VERSION "dbc-export 1 2025.20.8"

NS_ :

BS_:

BU_: ADSP APB APP APS BB BMS CC CP DAS DI DIF DIR EPAS3P EPAS3S EPBL EPBR GTW HVP ICR IDB PCS PM TCU UI UIS VC VCFRONT VCLEFT VCRIGHT VCSEC

BO_ 1383 ADSP_state: 7 ADSP
 SG_ ADSP_a2baState : 0|5@1+ (1,0) [0|31] "" Vector__XXX
 SG_ ADSP_a2bbState : 8|5@1+ (1,0) [0|31] "" Vector__XXX
 SG_ ADSP_baseamp0State : 13|3@1+ (1,0) [0|7] "" Vector__XXX
 SG_ ADSP_baseamp1State : 16|3@1+ (1,0) [0|7] "" Vector__XXX
 SG_ ADSP_baseamp2State : 19|3@1+ (1,0) [0|7] "" Vector__XXX
 SG_ ADSP_baseamp3State : 24|3@1+ (1,0) [0|7] "" Vector__XXX
 SG_ ADSP_audioReady : 27|1@1+ (1,0) [0|1] "" Vector__XXX
 SG_ ADSP_tcuI2SEnabled : 28|1@1+ (1,0) [0|1] "" Vector__XXX
 SG_ ADSP_ancState : 29|2@1+ (1,0) [0|3] "" Vector__XXX
 SG_ ADSP_telephonyRxMute : 31|1@1+ (1,0) [0|1] "" Vector__XXX
 SG_ ADSP_sourceSelect : 32|2@1+ (1,0) [0|3] "" Vector__XXX
 SG_ ADSP_tunerSelect : 34|1@1+ (1,0) [0|1] "" Vector__XXX
 SG_ ADSP_ancMode : 35|5@1+ (1,0) [0|31] "" Vector__XXX
 SG_ ADSP_spkMuteAll : 40|1@1+ (1,0) [0|1] "" Vector__XXX
 SG_ ADSP_allAudioReady : 41|1@1+ (1,0) [0|1] "" Vector__XXX
 SG_ ADSP_callState : 42|1@1+ (1,0) [0|1] "" Vector__XXX
 SG_ ADSP_telephonyTxMute : 43|1@1+ (1,0) [0|1] "" Vector__XXX
 SG_ ADSP_eCall_ENS_state : 44|3@1+ (1,0) [0|7] "" Vector__XXX
 SG_ ADSP_eCallSelfTest : 47|2@1+ (1,0) [0|3] "" Vector__XXX
 SG_ ADSP_eCallState : 49|1@1+ (1,0) [0|1] "" Vector__XXX
 SG_ ADSP_eCallMicrophoneStatus : 50|2@1+ (1,0) [0|3] "" Vector__XXX
 SG_ ADSP_eCallSpeakerStatus : 52|2@1+ (1,0) [0|3] "" Vector__XXX
 SG_ ADSP_a2baLoadShedded : 54|1@1+ (1,0) [0|1] "" Vector__XXX
 SG_ ADSP_requestFailoverSpeaker : 55|1@1+ (1,0) [0|1] "" Vector__XXX

BO_ 600 APB_status: 8 APB
 SG_ APB_watchdogState : 0|3@1+ (1,0) [0|6] "" Vector__XXX
 SG_ APB_fusedState : 3|2@1+ (1,0) [0|2] "" Vector__XXX
 SG_ APB_cameraHeaterRequest : 5|1@1+ (1,0) [0|1] "" Vector__XXX
 SG_ APB_factorySummonStatus : 6|4@1+ (1,0) [1|15] "" Vector__XXX
 SG_ APB_clipRecordingStatus : 10|3@1+ (1,0) [0|7] "" Vector__XXX
 SG_ APB_summonUnavailableReason : 14|5@1+ (1,0) [0|31] "" Vector__XXX
 SG_ APB_fsdSuspendState : 19|2@1+ (1,0) [0|2] "" Vector__XXX
 SG_ APB_fsdRevokeStrikeoutCount : 21|3@1+ (1,0) [0|6] "" Vector__XXX
 SG_ APB_teslaVisionSupported : 24|2@1+ (1,0) [0|2] "" Vector__XXX
 SG_ APB_teslaVisionUnsupportedReason : 26|3@1+ (1,0) [0|7] "" Vector__XXX
 SG_ APB_fsdRevokeCount : 29|3@1+ (1,0) [0|6] "" Vector__XXX
 SG_ APB_excessiveAccelPedalWarning : 32|1@1+ (1,0) [0|1] "" Vector__XXX
 SG_ APB_unifiedObjectStackSupported : 33|2@1+ (1,0) [0|2] "" Vector__XXX
 SG_ APB_DDAWSystemStatus : 38|3@1+ (1,0) [0|7] "" Vector__XXX
 SG_ APB_socOperatingMode : 41|2@1+ (1,0) [0|3] "" Vector__XXX
 SG_ APB_summonVersionIdentifier : 43|1@1+ (1,0) [0|1] "" Vector__XXX
 SG_ APB_sentryState : 44|3@1+ (1,0) [0|7] "" Vector__XXX
 SG_ APB_autoparkVersionIdentifier : 47|2@1+ (1,0) [0|3] "" Vector__XXX
 SG_ APB_suspendResumeAvailable : 51|1@1+ (1,0) [0|1] "" Vector__XXX
 SG_ APB_statusCounter : 52|4@1+ (1,0) [0|15] "" Vector__XXX
 SG_ APB_statusChecksum : 56|8@1+ (1,0) [0|255] "" Vector__XXX

BO_ 909 APP_VC_infoMessage: 8 APP
 SG_ APP_inTunnel : 0|2@1+ (1,0) [1|3] "" Vector__XXX
 SG_ APP_windshieldHeaterOnReason : 2|3@1+ (1,0) [1|7] "" Vector__XXX
 SG_ APP_selfieCameraBlocked : 6|2@1+ (1,0) [1|3] "" Vector__XXX
 SG_ APP_selfieCameraLUX : 8|8@1+ (1,0) [0|253] "lux" Vector__XXX
 SG_ APP_sceneTagClearlyRaining : 16|2@1+ (1,0) [1|3] "" Vector__XXX
 SG_ APP_sceneTagFog : 18|2@1+ (1,0) [1|3] "" Vector__XXX
 SG_ APP_sceneTagFullyBlocked : 20|2@1+ (1,0) [1|3] "" Vector__XXX
 SG_ APP_sceneTagIndoors : 22|2@1+ (1,0) [1|3] "" Vector__XXX
 SG_ APP_sceneTagLensFlare : 24|2@1+ (1,0) [1|3] "" Vector__XXX
 SG_ APP_sceneTagRaining : 26|2@1+ (1,0) [1|3] "" Vector__XXX
 SG_ APP_sceneTagSevereWeather : 28|2@1+ (1,0) [1|3] "" Vector__XXX
 SG_ APP_sceneTagSnowing : 30|2@1+ (1,0) [1|3] "" Vector__XXX
 SG_ APP_sceneTagSnowyRoad : 32|2@1+ (1,0) [1|3] "" Vector__XXX
 SG_ APP_sceneTagSunGlare : 34|2@1+ (1,0) [1|3] "" Vector__XXX
 SG_ APP_sceneTagTunnel : 36|2@1+ (1,0) [1|3] "" Vector__XXX
 SG_ APP_sceneTagWetRoad : 38|2@1+ (1,0) [1|3] "" Vector__XXX
 SG_ APP_fisheyeInPathVisibility : 40|3@1+ (1,0) [1|7] "" Vector__XXX
 SG_ APP_fisheyeOverallVisibility : 43|3@1+ (1,0) [1|7] "" Vector__XXX
 SG_ APP_mainInPathVisibility : 46|3@1+ (1,0) [1|7] "" Vector__XXX
 SG_ APP_mainOverallVisibility : 49|3@1+ (1,0) [1|7] "" Vector__XXX
 SG_ APP_narrowInPathVisibility : 52|3@1+ (1,0) [1|7] "" Vector__XXX
 SG_ APP_narrowOverallVisibility : 55|3@1+ (1,0) [1|7] "" Vector__XXX
 SG_ APP_frontCamOcclusionType : 58|3@1+ (1,0) [0|7] "" Vector__XXX

BO_ 2046 APP_camCalibrationStatus: 6 APP
 SG_ APP_cameraPosition M : 0|4@1+ (1,0) [0|15] "" Vector__XXX
 SG_ APP_mainCamExtPitchCal m1 : 8|9@1+ (0.05,-12.5) [-12.5|12.5] "deg" Vector__XXX
 SG_ APP_mainCamExtYawCal m1 : 17|9@1+ (0.05,-12.5) [-12.5|12.5] "deg" Vector__XXX
 SG_ APP_mainCalibTime m1 : 26|7@1+ (1,0) [0|126] "min" Vector__XXX
 SG_ APP_mainCalibProgress m1 : 33|7@1+ (1,0) [0|100] "percent" Vector__XXX
 SG_ APP_mainCalibrated m1 : 40|1@1+ (1,0) [0|1] "" Vector__XXX
 SG_ APP_narrowCamExtPitchCal m2 : 8|9@1+ (0.05,-12.5) [-12.5|12.5] "deg" Vector__XXX
 SG_ APP_narrowCamExtYawCal m2 : 17|9@1+ (0.05,-12.5) [-12.5|12.5] "deg" Vector__XXX
 SG_ APP_narrowCalibTime m2 : 26|7@1+ (1,0) [0|126] "min" Vector__XXX
 SG_ APP_narrowCalibProgress m2 : 33|7@1+ (1,0) [0|100] "percent" Vector__XXX
 SG_ APP_narrowCalibrated m2 : 40|1@1+ (1,0) [0|1] "" Vector__XXX
 SG_ APP_fisheyeCamExtPitchCal m3 : 8|9@1+ (0.05,-12.5) [-12.5|12.5] "deg" Vector__XXX
 SG_ APP_fisheyeCamExtYawCal m3 : 17|9@1+ (0.05,-12.5) [-12.5|12.5] "deg" Vector__XXX
 SG_ APP_fisheyeCalibTime m3 : 26|7@1+ (1,0) [0|126] "min" Vector__XXX
 SG_ APP_fisheyeCalibProgress m3 : 33|7@1+ (1,0) [0|100] "percent" Vector__XXX
 SG_ APP_fisheyeCalibrated m3 : 40|1@1+ (1,0) [0|1] "" Vector__XXX
 SG_ APP_lPillarCamExtPitchCal m4 : 8|9@1+ (0.05,-12.5) [-12.5|12.5] "deg" Vector__XXX
 SG_ APP_lPillarCamExtYawCal m4 : 17|9@1+ (0.05,-12.5) [-12.5|12.5] "deg" Vector__XXX
 SG_ APP_lPillarCalibTime m4 : 26|7@1+ (1,0) [0|126] "min" Vector__XXX
 SG_ APP_lPillarCalibProgress m4 : 33|7@1+ (1,0) [0|100] "percent" Vector__XXX
 SG_ APP_lPillarCalibrated m4 : 40|1@1+ (1,0) [0|1] "" Vector__XXX
 SG_ APP_rPillarCamExtPitchCal m5 : 8|9@1+ (0.05,-12.5) [-12.5|12.5] "deg" Vector__XXX
 SG_ APP_rPillarCamExtYawCal m5 : 17|9@1+ (0.05,-12.5) [-12.5|12.5] "deg" Vector__XXX
 SG_ APP_rPillarCalibTime m5 : 26|7@1+ (1,0) [0|126] "min" Vector__XXX
 SG_ APP_rPillarCalibProgress m5 : 33|7@1+ (1,0) [0|100] "percent" Vector__XXX
 SG_ APP_rPillarCalibrated m5 : 40|1@1+ (1,0) [0|1] "" Vector__XXX
 SG_ APP_lRepeatCamExtPitchCal m6 : 8|9@1+ (0.05,-12.5) [-12.5|12.5] "deg" Vector__XXX
 SG_ APP_lRepeatCamExtYawCal m6 : 17|9@1+ (0.05,-12.5) [-12.5|12.5] "deg" Vector__XXX
 SG_ APP_lRepeatCalibTime m6 : 26|7@1+ (1,0) [0|126] "min" Vector__XXX
 SG_ APP_lRepeatCalibProgress m6 : 33|7@1+ (1,0) [0|100] "percent" Vector__XXX
 SG_ APP_lRepeatCalibrated m6 : 40|1@1+ (1,0) [0|1] "" Vector__XXX
 SG_ APP_rRepeatCamExtPitchCal m7 : 8|9@1+ (0.05,-12.5) [-12.5|12.5] "deg" Vector__XXX
 SG_ APP_rRepeatCamExtYawCal m7 : 17|9@1+ (0.05,-12.5) [-12.5|12.5] "deg" Vector__XXX
 SG_ APP_rRepeatCalibTime m7 : 26|7@1+ (1,0) [0|126] "min" Vector__XXX
 SG_ APP_rRepeatCalibProgress m7 : 33|7@1+ (1,0) [0|100] "percent" Vector__XXX
 SG_ APP_rRepeatCalibrated m7 : 40|1@1+ (1,0) [0|1] "" Vector__XXX
 SG_ APP_backupCamExtPitchCal m8 : 8|9@1+ (0.05,-12.5) [-12.5|12.5] "deg" Vector__XXX
 SG_ APP_backupCamExtYawCal m8 : 17|9@1+ (0.05,-12.5) [-12.5|12.5] "deg" Vector__XXX
 SG_ APP_backupCalibTime m8 : 26|7@1+ (1,0) [0|126] "min" Vector__XXX
 SG_ APP_backupCalibProgress m8 : 33|7@1+ (1,0) [0|100] "percent" Vector__XXX
 SG_ APP_backupCalibrated m8 : 40|1@1+ (1,0) [0|1] "" Vector__XXX

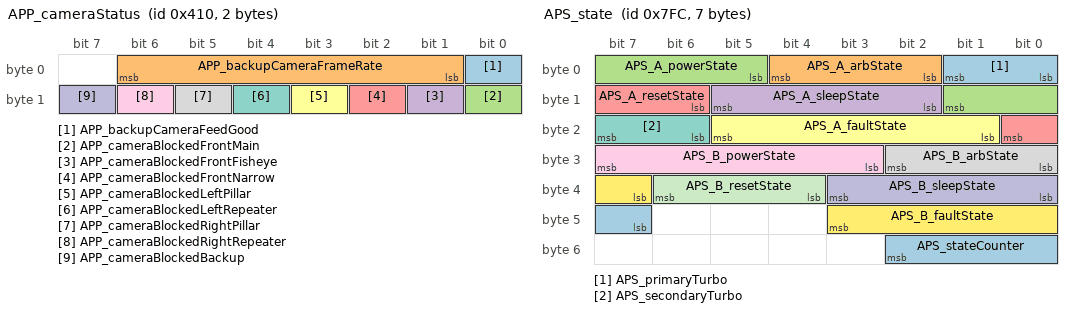
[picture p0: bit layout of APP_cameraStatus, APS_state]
BO_ 1040 APP_cameraStatus: 2 APP
 SG_ APP_backupCameraFeedGood : 0|1@1+ (1,0) [0|1] "" Vector__XXX
 SG_ APP_backupCameraFrameRate : 1|6@1+ (1,0) [0|63] "" Vector__XXX
 SG_ APP_cameraBlockedFrontMain : 8|1@1+ (1,0) [0|1] "" Vector__XXX
 SG_ APP_cameraBlockedFrontFisheye : 9|1@1+ (1,0) [0|1] "" Vector__XXX
 SG_ APP_cameraBlockedFrontNarrow : 10|1@1+ (1,0) [0|1] "" Vector__XXX
 SG_ APP_cameraBlockedLeftPillar : 11|1@1+ (1,0) [0|1] "" Vector__XXX
 SG_ APP_cameraBlockedLeftRepeater : 12|1@1+ (1,0) [0|1] "" Vector__XXX
 SG_ APP_cameraBlockedRightPillar : 13|1@1+ (1,0) [0|1] "" Vector__XXX
 SG_ APP_cameraBlockedRightRepeater : 14|1@1+ (1,0) [0|1] "" Vector__XXX
 SG_ APP_cameraBlockedBackup : 15|1@1+ (1,0) [0|1] "" Vector__XXX

BO_ 603 APP_environment: 1 APP
 SG_ APP_environmentRainy : 0|1@1+ (1,0) [0|1] "" Vector__XXX
 SG_ APP_environmentSnowy : 1|1@1+ (1,0) [0|1] "" Vector__XXX

BO_ 601 APP_status: 8 APP
 SG_ APP_watchdogState : 0|3@1+ (1,0) [0|6] "" Vector__XXX
 SG_ APP_fusedState : 3|2@1+ (1,0) [0|2] "" Vector__XXX
 SG_ APP_cameraHeaterRequest : 5|1@1+ (1,0) [0|1] "" Vector__XXX
 SG_ APP_factorySummonStatus : 6|4@1+ (1,0) [1|15] "" Vector__XXX
 SG_ APP_clipRecordingStatus : 10|3@1+ (1,0) [0|7] "" Vector__XXX
 SG_ APP_allowApActivationWithBrake : 13|1@1+ (1,0) [0|1] "" Vector__XXX
 SG_ APP_summonUnavailableReason : 14|5@1+ (1,0) [0|31] "" Vector__XXX
 SG_ APP_fsdSuspendState : 19|2@1+ (1,0) [0|2] "" Vector__XXX
 SG_ APP_fsdRevokeStrikeoutCount : 21|3@1+ (1,0) [0|6] "" Vector__XXX
 SG_ APP_teslaVisionSupported : 24|2@1+ (1,0) [0|2] "" Vector__XXX
 SG_ APP_teslaVisionUnsupportedReason : 26|3@1+ (1,0) [0|7] "" Vector__XXX
 SG_ APP_fsdRevokeCount : 29|3@1+ (1,0) [0|6] "" Vector__XXX
 SG_ APP_excessiveAccelPedalWarning : 32|1@1+ (1,0) [0|1] "" Vector__XXX
 SG_ APP_unifiedObjectStackSupported : 33|2@1+ (1,0) [0|2] "" Vector__XXX
 SG_ APP_DDAWSystemStatus : 38|3@1+ (1,0) [0|7] "" Vector__XXX
 SG_ APP_socOperatingMode : 41|2@1+ (1,0) [0|3] "" Vector__XXX
 SG_ APP_summonVersionIdentifier : 43|1@1+ (1,0) [0|1] "" Vector__XXX
 SG_ APP_sentryState : 44|3@1+ (1,0) [0|7] "" Vector__XXX
 SG_ APP_autoparkVersionIdentifier : 47|2@1+ (1,0) [0|3] "" Vector__XXX
 SG_ APP_suspendResumeAvailable : 51|1@1+ (1,0) [0|1] "" Vector__XXX
 SG_ APP_statusCounter : 52|4@1+ (1,0) [0|15] "" Vector__XXX
 SG_ APP_statusChecksum : 56|8@1+ (1,0) [0|255] "" Vector__XXX

BO_ 2044 APS_state: 7 APS
 SG_ APS_primaryTurbo : 0|2@1+ (1,0) [0|3] "" Vector__XXX
 SG_ APS_A_arbState : 2|3@1+ (1,0) [0|7] "" Vector__XXX
 SG_ APS_A_powerState : 5|5@1+ (1,0) [0|31] "" Vector__XXX
 SG_ APS_A_sleepState : 10|4@1+ (1,0) [0|15] "" Vector__XXX
 SG_ APS_A_resetState : 14|3@1+ (1,0) [0|7] "" Vector__XXX
 SG_ APS_A_faultState : 17|5@1+ (1,0) [0|31] "" Vector__XXX
 SG_ APS_secondaryTurbo : 22|2@1+ (1,0) [0|3] "" Vector__XXX
 SG_ APS_B_arbState : 24|3@1+ (1,0) [0|7] "" Vector__XXX
 SG_ APS_B_powerState : 27|5@1+ (1,0) [0|31] "" Vector__XXX
 SG_ APS_B_sleepState : 32|4@1+ (1,0) [0|15] "" Vector__XXX
 SG_ APS_B_resetState : 36|3@1+ (1,0) [0|7] "" Vector__XXX
 SG_ APS_B_faultState : 39|5@1+ (1,0) [0|31] "" Vector__XXX
 SG_ APS_stateCounter : 47|4@1+ (1,0) [0|15] "" Vector__XXX

BO_ 970 APS_status: 8 APS
 SG_ APS_appStatusMonitorState : 0|3@1+ (1,0) [0|7] "" Vector__XXX
 SG_ APS_vehBehaviorState : 4|4@1+ (1,0) [0|15] "" Vector__XXX
 SG_ APS_canMaster : 8|2@1+ (1,0) [0|2] "" Vector__XXX
 SG_ APS_appGpioState : 10|2@1+ (1,0) [0|3] "" Vector__XXX
 SG_ APS_eacInternalState : 12|3@1+ (1,0) [0|7] "" Vector__XXX
 SG_ APS_switchState : 15|1@1+ (1,0) [0|1] "" Vector__XXX
 SG_ APS_apbStatusMonitorState : 16|3@1+ (1,0) [0|7] "" Vector__XXX
 SG_ APS_apbGpioState : 20|2@1+ (1,0) [0|3] "" Vector__XXX
 SG_ APS_statusCounter : 22|4@1+ (1,0) [0|15] "" Vector__XXX
 SG_ APS_locLimitReason : 26|3@1+ (1,0) [0|7] "" Vector__XXX
 SG_ APS_appPowerStateRequest : 29|2@1+ (1,0) [0|3] "" Vector__XXX
 SG_ APS_appPowerStateReason : 31|4@1+ (1,0) [0|15] "" Vector__XXX
 SG_ APS_apbPowerStateRequest : 36|2@1+ (1,0) [0|3] "" Vector__XXX
 SG_ APS_apbPowerStateReason : 38|4@1+ (1,0) [0|15] "" Vector__XXX
 SG_ APS_heaterStateDebug : 43|3@1+ (1,0) [0|6] "" Vector__XXX
 SG_ APS_autosummonCounter : 46|3@1+ (1,0) [0|7] "" Vector__XXX
 SG_ APS_autosummonAlert : 49|1@1+ (1,0) [0|1] "" Vector__XXX
 SG_ APS_gpsAntennaState : 50|2@1+ (1,0) [0|3] "" Vector__XXX
 SG_ APS_arbState : 52|3@1+ (1,0) [0|7] "" Vector__XXX
 SG_ APS_socPowerOperatingMode : 55|2@1+ (1,0) [0|3] "" Vector__XXX
 SG_ APS_otherArbState : 57|3@1+ (1,0) [0|7] "" Vector__XXX

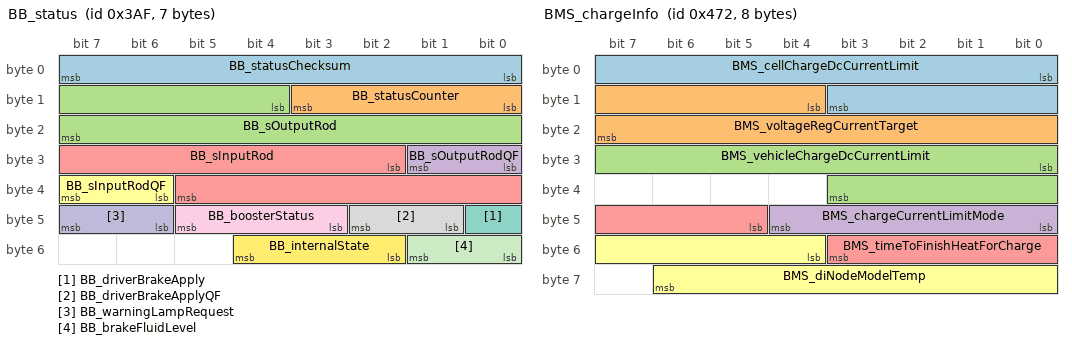
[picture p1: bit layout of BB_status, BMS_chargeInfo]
BO_ 943 BB_status: 7 BB
 SG_ BB_statusChecksum : 0|8@1+ (1,0) [0|255] "" Vector__XXX
 SG_ BB_statusCounter : 8|4@1+ (1,0) [0|15] "" Vector__XXX
 SG_ BB_sOutputRod : 12|12@1+ (0.015625,-5) [-5|47] "mm" Vector__XXX
 SG_ BB_sOutputRodQF : 24|2@1+ (1,0) [0|3] "" Vector__XXX
 SG_ BB_sInputRod : 26|12@1+ (0.015625,-5) [-5|47] "mm" Vector__XXX
 SG_ BB_sInputRodQF : 38|2@1+ (1,0) [0|3] "" Vector__XXX
 SG_ BB_driverBrakeApply : 40|1@1+ (1,0) [0|1] "" Vector__XXX
 SG_ BB_driverBrakeApplyQF : 41|2@1+ (1,0) [0|3] "" Vector__XXX
 SG_ BB_boosterStatus : 43|3@1+ (1,0) [0|7] "" Vector__XXX
 SG_ BB_warningLampRequest : 46|2@1+ (1,0) [0|3] "" Vector__XXX
 SG_ BB_brakeFluidLevel : 48|2@1+ (1,0) [0|3] "" Vector__XXX
 SG_ BB_internalState : 50|3@1+ (1,0) [0|7] "" Vector__XXX

BO_ 1138 BMS_chargeInfo: 8 BMS
 SG_ BMS_cellChargeDcCurrentLimit : 0|12@1+ (0.5,0) [0|2047.5] "A" Vector__XXX
 SG_ BMS_voltageRegCurrentTarget : 12|12@1+ (0.5,0) [0|2047.5] "A" Vector__XXX
 SG_ BMS_vehicleChargeDcCurrentLimit : 24|12@1+ (0.5,0) [0|2047.5] "A" Vector__XXX
 SG_ BMS_chargeCurrentLimitMode : 40|5@1+ (1,0) [0|31] "" Vector__XXX
 SG_ BMS_timeToFinishHeatForCharge : 45|7@1+ (5,0) [0|600] "min" Vector__XXX
 SG_ BMS_diNodeModelTemp : 52|11@1+ (0.1,-50) [-50|154.6] "degC" Vector__XXX

BO_ 2029 BMS_debugInfo_10Hz: 8 BMS
 SG_ BMS_10HzDebug_Id M : 0|6@1+ (1,0) [0|63] "" Vector__XXX
 SG_ BMS_activeCoolCellTargetT m33 : 6|9@1+ (0.25,-25) [-25|100] "DegC" Vector__XXX
 SG_ BMS_passiveCoolCellTargetT m33 : 15|9@1+ (0.25,-25) [-25|100] "DegC" Vector__XXX

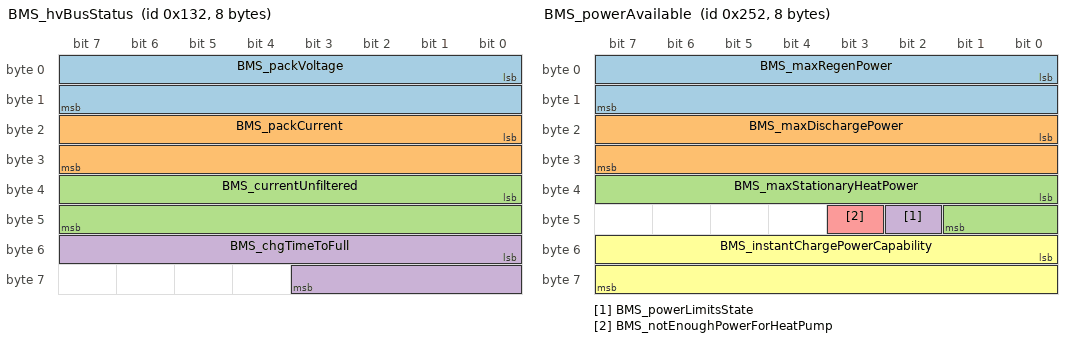
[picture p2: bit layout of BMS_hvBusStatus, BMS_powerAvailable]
BO_ 306 BMS_hvBusStatus: 8 BMS
 SG_ BMS_packVoltage : 0|16@1+ (0.01,0) [0|655.35] "V" Vector__XXX
 SG_ BMS_packCurrent : 16|16@1- (0.1,0) [-3276.7|3276.7] "A" Vector__XXX
 SG_ BMS_currentUnfiltered : 32|16@1- (0.05,-822) [-2460.3|816.3] "A" Vector__XXX
 SG_ BMS_chgTimeToFull : 48|12@1+ (0.01666667,0) [0|68.23334698] "Hours" Vector__XXX

BO_ 884 BMS_log1: 8 BMS
 SG_ BMS_log1MuxId M : 0|8@1+ (1,0) [0|255] "" Vector__XXX
 SG_ BMS_extDcPrechargeVoltageLimit m8 : 20|12@1+ (0.146502256393,0) [0|599.926739929] "V" Vector__XXX
 SG_ BMS_dcChargeCurrentRequest m8 : 32|14@1- (0.25,0) [-2048|2047.75] "A" Vector__XXX
 SG_ BMS_dcChargeCurrentLimit m8 : 46|13@1- (0.5,0) [-2048|2047.5] "A" Vector__XXX
 SG_ BMS_dcDischargeEnabled m8 : 59|1@1+ (1,0) [0|1] "" Vector__XXX
 SG_ BMS_rippleChargeRetryCount m8 : 60|3@1+ (1,0) [0|7] "" Vector__XXX
 SG_ BMS_dcChargeVoltageLimit m9 : 8|12@1+ (0.146502256393,0) [0|599.926739929] "V" Vector__XXX
 SG_ BMS_dcChargePowerLimit m9 : 20|12@1- (1,0) [-2048|2047] "kW" Vector__XXX
 SG_ BMS_maxExtIsoFcLinkV m9 : 48|13@1+ (0.134293735027,0) [0|1099.99998361] "V" Vector__XXX
 SG_ BMS_socByDeltaVEnabled m15 : 8|1@1+ (1,0) [0|1] "" Vector__XXX
 SG_ BMS_socByDvMaxSocLimit m15 : 9|10@1+ (0.1,0) [0|102.2] "%" Vector__XXX
 SG_ BMS_socByDvVoltageChangeOverAh m15 : 19|9@1+ (0.002,0) [0|1] "V" Vector__XXX
 SG_ BMS_socByDvMaxSocByAhCorrected m15 : 28|10@1+ (0.1,0) [0|102.2] "%" Vector__XXX
 SG_ BMS_socByDvMaxBrickVoltage m15 : 40|12@1+ (0.002,0) [0|5] "V" Vector__XXX
 SG_ BMS_socByDvMaxBrickId m15 : 56|8@1+ (1,1) [1|256] "" Vector__XXX

BO_ 946 BMS_log2: 8 BMS
 SG_ BMS_log2MuxId M : 0|7@1+ (1,0) [0|127] "" Vector__XXX
 SG_ BMS_cacAvg m0 : 8|13@1+ (0.1,0) [0|819.1] "Ah" Vector__XXX
 SG_ BMS_cacMin m0 : 24|13@1+ (0.1,0) [0|819.1] "Ah" Vector__XXX
 SG_ BMS_cacMinBrickId m0 : 37|7@1+ (1,1) [1|128] "" Vector__XXX
 SG_ BMS_cacMax m0 : 44|13@1+ (0.1,0) [0|819.1] "Ah" Vector__XXX
 SG_ BMS_cacMaxBrickId m0 : 57|7@1+ (1,1) [1|128] "" Vector__XXX
 SG_ BMS_acRippleConfigNvramValid m18 : 7|1@1+ (1,0) [0|1] "" Vector__XXX
 SG_ BMS_hvChain_useLeakyBucket m18 : 8|1@1+ (1,0) [0|1] "" Vector__XXX
 SG_ BMS_hvChain_iLimit m18 : 9|14@1+ (0.2,0) [0|3275] "A" Vector__XXX
 SG_ BMS_hvChain_limitingState m18 : 23|9@1+ (1,1) [1|511] "" Vector__XXX
 SG_ BMS_hvChain_limitingStateTempera m18 : 32|13@1- (0.1,367.6) [-40|775] "DegC" Vector__XXX
 SG_ BMS_acRippleIsSupported m18 : 45|1@1+ (1,0) [0|1] "" Vector__XXX
 SG_ BMS_acRippleStartTemperatureMax m18 : 46|9@1+ (0.25,-25) [-25|100] "DegC" Vector__XXX
 SG_ BMS_acRippleStartTemperatureMin m18 : 55|9@1+ (0.25,-25) [-25|100] "DegC" Vector__XXX
 SG_ BMS_fcLinkTestDecayTime m20 : 8|10@1+ (2,0) [0|2044] "mS" Vector__XXX
 SG_ BMS_fcLinkTestTimeSinceLastRun m20 : 18|12@1+ (0.0175824183971,0) [0|71.99] "Hours" Vector__XXX
 SG_ BMS_pcsPrechargeTargetVoltage m20 : 32|16@1- (0.1,0) [-3276.8|3276.7] "V" Vector__XXX
 SG_ BMS_recentOvUvAlert m20 : 48|1@1+ (1,0) [0|1] "" Vector__XXX
 SG_ BMS_recentIsoAlert m20 : 49|1@1+ (1,0) [0|1] "" Vector__XXX
 SG_ BMS_recentBmbMiaAlert m20 : 50|1@1+ (1,0) [0|1] "" Vector__XXX
 SG_ BMS_cacBlendingConfigNvramValid m20 : 51|1@1+ (1,0) [0|1] "" Vector__XXX
 SG_ BMS_cacBlendingEnabled m20 : 52|1@1+ (1,0) [0|1] "" Vector__XXX
 SG_ BMS_cacBlendPercentPerCycle m20 : 53|10@1+ (0.001,0) [0|1.023] "%" Vector__XXX
 SG_ BMS_energyVariableChgRequested m21 : 8|1@1+ (1,0) [0|1] "" Vector__XXX
 SG_ BMS_packRestTime m21 : 9|12@1+ (0.0175824183971,0) [0|71.99] "Hours" Vector__XXX
 SG_ BMS_idealEnergyFloor m21 : 21|10@1+ (0.1,0) [0|102.2] "KWh" Vector__XXX
 SG_ BMS_thmGradientSlopeCondition m21 : 31|1@1+ (1,0) [0|1] "" Vector__XXX
 SG_ BMS_recentSlopeConditon m21 : 32|1@1+ (1,0) [0|1] "" Vector__XXX
 SG_ BMS_dynamicEnergyBuffer m21 : 33|10@1+ (0.1,0) [0|102.2] "KWh" Vector__XXX
 SG_ BMS_temperatureCondition m21 : 43|1@1+ (1,0) [0|1] "" Vector__XXX
 SG_ BMS_thmGradientSlope m21 : 44|10@1- (0.01,0) [-5.12|5.11] "C/min" Vector__XXX
 SG_ BMS_thmGradient m21 : 56|8@1+ (0.1,0) [0|25.5] "C" Vector__XXX
 SG_ BMS_dSocNormalizedMin m33 : 8|12@1+ (0.0030517578125,-12.4969482422) [-12.4969482422|-0.003051757825] "%" Vector__XXX
 SG_ BMS_dSocNormalizedFiltMin m33 : 20|12@1+ (0.0030517578125,-12.4969482422) [-12.4969482422|-0.003051757825] "%" Vector__XXX
 SG_ BMS_dSocMinAlpha m33 : 32|12@1+ (0.0030517578125,-12.4969482422) [-12.4969482422|-0.003051757825] "%" Vector__XXX
 SG_ BMS_dSocMaxLowAlphaCounter m33 : 44|4@1+ (1,0) [0|15] "" Vector__XXX
 SG_ BMS_dSocMinAlphaBrickID m33 : 48|7@1+ (1,1) [1|128] "" Vector__XXX
 SG_ BMS_dSocCacMargin m33 : 55|9@1+ (0.0030517578125,0) [0|1.55639648438] "%" Vector__XXX
 SG_ BMS_lifeModelAvgTempSeverity m55 : 8|5@1+ (0.1,0) [0|3] "-" Vector__XXX
 SG_ BMS_lifeModelDepthOfDischargeSev m55 : 16|8@1+ (0.01,0) [0|1.5] "-" Vector__XXX
 SG_ BMS_lifeModelHistogramCapacityLo m55 : 24|9@1+ (0.1,0) [0|51] "%" Vector__XXX
 SG_ BMS_lifeModelHistogramBrickCapac m55 : 33|13@1+ (0.1,0) [0|819] "Ah" Vector__XXX
 SG_ BMS_lifeModelDcrGrowthPercent m55 : 48|14@1- (0.1,200) [-100|500] "%" Vector__XXX
 SG_ BMS_nominalFullPackEnergyRaw m56 : 8|16@1+ (0.02,0) [0|1310.68] "kWh" Vector__XXX
 SG_ BMS_userChargeCalibratingReason m56 : 24|2@1+ (1,0) [0|3] "" Vector__XXX
 SG_ BMS_nominalEnergyRemainingBuffer m56 : 32|16@1+ (0.02,0) [0|1310.68] "kWh" Vector__XXX
 SG_ BMS_idealEnergyRemainingBuffered m56 : 48|16@1+ (0.02,0) [0|1310.68] "kWh" Vector__XXX
 SG_ BMS_largestCacSpreadErrorLower m64 : 8|12@1+ (0.1,0) [0|409.4] "Ah" Vector__XXX
 SG_ BMS_lifeModelAverageCac m64 : 20|12@1+ (0.1,0) [0|409.4] "Ah" Vector__XXX
 SG_ BMS_lifeModelCacBrick1 m64 : 32|12@1+ (0.1,0) [0|409.4] "Ah" Vector__XXX
 SG_ BMS_lifeModelAverageOffset m64 : 44|10@1- (0.1,0) [-51.1|51.1] "Ah" Vector__XXX
 SG_ BMS_percentCacUpdatesInTimeWindo m64 : 54|10@1+ (0.1,0) [0|100] "%" Vector__XXX
 SG_ BMS_lifeModelMaxCacBrickId m65 : 8|8@1+ (1,1) [1|255] "" Vector__XXX
 SG_ BMS_lifeModelMaxCac m65 : 16|12@1+ (0.1,0) [0|409.4] "Ah" Vector__XXX
 SG_ BMS_lifeModelMinCacBrickId m65 : 28|8@1+ (1,1) [1|255] "" Vector__XXX
 SG_ BMS_lifeModelMinCac m65 : 36|12@1+ (0.1,0) [0|409.4] "Ah" Vector__XXX
 SG_ BMS_restingPointCacAvg m65 : 48|12@1+ (0.1,0) [0|409.4] "Ah" Vector__XXX
 SG_ BMS_cacEstimationSource m65 : 60|2@1+ (1,0) [0|3] "" Vector__XXX
 SG_ BMS_synchronizedCacMaxRaw m71 : 8|12@1+ (0.1,0) [0|409.4] "Ah" Vector__XXX
 SG_ BMS_synchronizedCacMinRaw m71 : 20|12@1+ (0.1,0) [0|409.4] "Ah" Vector__XXX
 SG_ BMS_largestSyncCacErrorStartSoc m71 : 32|10@1+ (0.1,0) [0|102.2] "%" Vector__XXX
 SG_ BMS_largestSyncCacErrorEndSoc m71 : 42|10@1+ (0.1,0) [0|102.2] "%" Vector__XXX
 SG_ BMS_runtimeSocConfigNvramValid m71 : 52|1@1+ (1,0) [0|1] "" Vector__XXX
 SG_ BMS_runtimeSocCorrectionsEnabled m71 : 53|1@1+ (1,0) [0|1] "" Vector__XXX
 SG_ BMS_rubberBandingEnabled m71 : 54|1@1+ (1,0) [0|1] "" Vector__XXX
 SG_ BMS_rubberBandingConfigNvramVali m71 : 55|1@1+ (1,0) [0|1] "" Vector__XXX
 SG_ BMS_runtimeSocMinTempForModel m71 : 56|6@1+ (0.5,0) [0|20] "DegC" Vector__XXX
 SG_ BMS_energyBufferConfigNvramValid m71 : 62|1@1+ (1,0) [0|1] "" Vector__XXX
 SG_ BMS_thermalEvent1pDetectConfigDi m71 : 63|1@1+ (1,0) [0|1] "" Vector__XXX
 SG_ BMS_sohEnergy m79 : 8|11@1+ (0.1,0) [0|204.6] "KWh" Vector__XXX
 SG_ BMS_fullCapacitySohEnergy m79 : 19|11@1+ (0.1,0) [0|204.6] "KWh" Vector__XXX
 SG_ BMS_calibratedCapacitySohEnergy m79 : 30|11@1+ (0.1,0) [0|204.6] "KWh" Vector__XXX
 SG_ BMS_estimatedCapacitySohEnergy m79 : 41|11@1+ (0.1,0) [0|204.6] "KWh" Vector__XXX
 SG_ BMS_prevUserFacingSohEnergy m79 : 52|11@1+ (0.1,0) [0|204.6] "KWh" Vector__XXX
 SG_ BMS_stateOfHealthMinCac m80 : 8|13@1+ (0.1,0) [0|819] "Ah" Vector__XXX
 SG_ BMS_lifeModelStorageLossPackAge m80 : 24|14@1+ (1,0) [0|16382] "days" Vector__XXX
 SG_ BMS_lifeModelThroughputCycleCoun m80 : 40|12@1+ (1,0) [0|4094] "Cycles" Vector__XXX
 SG_ BMS_lifeModelThroughputDcrCycleC m80 : 52|12@1+ (1,0) [0|4094] "Cycles" Vector__XXX
 SG_ BMS_energyWalkCounter m83 : 8|8@1+ (1,0) [0|255] "" Vector__XXX
 SG_ BMS_energyWalkTimeoutCounter m83 : 16|8@1+ (1,0) [0|255] "" Vector__XXX
 SG_ BMS_dynamicCcvEnabled m83 : 24|1@1+ (1,0) [0|1] "" Vector__XXX
 SG_ BMS_chargeTargetLookupSoc m83 : 32|10@1+ (0.1,0) [0|102.2] "%" Vector__XXX
 SG_ BMS_stateOfHealth m83 : 42|10@1+ (0.1,0) [0|100] "%" Vector__XXX

BO_ 914 BMS_packConfig: 8 BMS
 SG_ BMS_packConfigMultiplexer M : 0|8@1+ (1,0) [0|255] "" Vector__XXX
 SG_ BMS_reservedConfig_0 m0 : 8|5@1+ (1,0) [0|31] "" Vector__XXX
 SG_ BMS_moduleType m1 : 8|3@1+ (1,0) [0|7] "" Vector__XXX
 SG_ BMS_thermalPackType m1 : 11|4@1+ (1,0) [0|15] "" Vector__XXX
 SG_ BMS_packMass m1 : 16|8@1+ (1,300) [342|540] "kg" Vector__XXX
 SG_ BMS_platformMaxBusVoltage m1 : 24|10@1+ (1,300) [300|1300] "V" Vector__XXX
 SG_ BMS_standbySupplyContinuousPower m1 : 36|2@1+ (1,0) [0|3] "" Vector__XXX

BO_ 594 BMS_powerAvailable: 8 BMS
 SG_ BMS_maxRegenPower : 0|16@1+ (0.01,0) [0|655.35] "kW" Vector__XXX
 SG_ BMS_maxDischargePower : 16|16@1+ (0.013,0) [0|850] "kW" Vector__XXX
 SG_ BMS_maxStationaryHeatPower : 32|10@1+ (0.01,0) [0|10.23] "kW" Vector__XXX
 SG_ BMS_powerLimitsState : 42|1@1+ (1,0) [0|1] "" Vector__XXX
 SG_ BMS_notEnoughPowerForHeatPump : 43|1@1+ (1,0) [0|1] "" Vector__XXX
 SG_ BMS_instantChargePowerCapability : 48|16@1+ (0.05,0) [0|3276.7] "kW" Vector__XXX

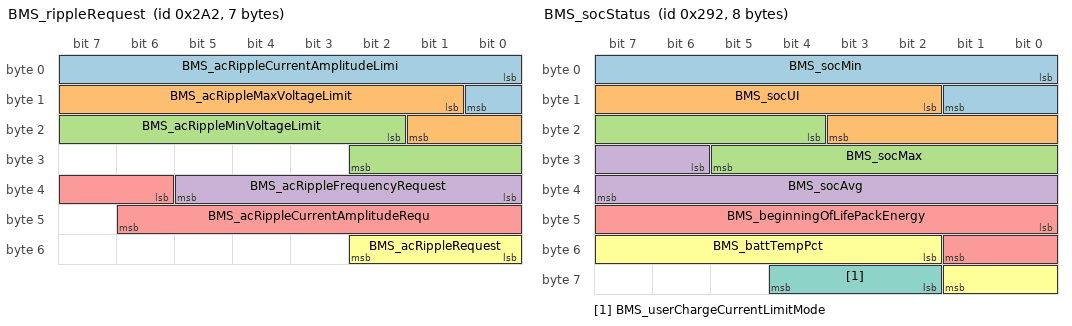
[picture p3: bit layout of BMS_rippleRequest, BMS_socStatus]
BO_ 674 BMS_rippleRequest: 7 BMS
 SG_ BMS_acRippleCurrentAmplitudeLimi : 0|9@1+ (1,0) [0|511] "A" Vector__XXX
 SG_ BMS_acRippleMaxVoltageLimit : 9|9@1+ (1,0) [0|511] "V" Vector__XXX
 SG_ BMS_acRippleMinVoltageLimit : 18|9@1+ (1,0) [0|511] "V" Vector__XXX
 SG_ BMS_acRippleFrequencyRequest : 32|6@1+ (1,80) [80|142] "Hz" Vector__XXX
 SG_ BMS_acRippleCurrentAmplitudeRequ : 38|9@1+ (1,0) [0|511] "A" Vector__XXX
 SG_ BMS_acRippleRequest : 48|3@1+ (1,0) [0|7] "" Vector__XXX

BO_ 658 BMS_socStatus: 8 BMS
 SG_ BMS_socMin : 0|10@1+ (0.1,0) [0|102.2] "%" Vector__XXX
 SG_ BMS_socUI : 10|10@1+ (0.1,0) [0|100] "%" Vector__XXX
 SG_ BMS_socMax : 20|10@1+ (0.1,0) [0|102.2] "%" Vector__XXX
 SG_ BMS_socAvg : 30|10@1+ (0.1,0) [0|102.2] "%" Vector__XXX
 SG_ BMS_beginningOfLifePackEnergy : 40|10@1+ (0.1,0) [0|102.2] "KWh" Vector__XXX
 SG_ BMS_battTempPct : 50|8@1+ (0.4,0) [0|100] "%" Vector__XXX
 SG_ BMS_userChargeCurrentLimitMode : 58|3@1+ (1,0) [0|7] "" Vector__XXX

BO_ 530 BMS_status: 8 BMS
 SG_ BMS_hvacPowerRequest : 0|1@1+ (1,0) [0|1] "" Vector__XXX
 SG_ BMS_notEnoughPowerForDrive : 1|1@1+ (1,0) [0|1] "" Vector__XXX
 SG_ BMS_notEnoughPowerForSupport : 2|1@1+ (1,0) [0|1] "" Vector__XXX
 SG_ BMS_preconditionAllowed : 3|1@1+ (1,0) [0|1] "" Vector__XXX
 SG_ BMS_updateAllowed : 4|1@1+ (1,0) [0|1] "" Vector__XXX
 SG_ BMS_activeHeatingWorthwhile : 5|1@1+ (1,0) [0|1] "" Vector__XXX
 SG_ BMS_cpMiaOnHvs : 6|1@1+ (1,0) [0|1] "" Vector__XXX
 SG_ BMS_pcsPwmEnabled : 7|1@1+ (1,0) [0|1] "" Vector__XXX
 SG_ BMS_contactorState : 8|3@1+ (1,0) [1|7] "" Vector__XXX
 SG_ BMS_userChargeStatus : 11|3@1+ (1,0) [0|7] "" Vector__XXX
 SG_ BMS_chargeRequest : 31|1@1+ (1,0) [0|1] "" Vector__XXX
 SG_ BMS_state : 32|4@1+ (1,0) [0|15] "" Vector__XXX
 SG_ BMS_diLimpRequest : 37|1@1+ (1,0) [0|1] "" Vector__XXX
 SG_ BMS_okToShipByAir : 38|1@1+ (1,0) [0|1] "" Vector__XXX
 SG_ BMS_okToShipByLand : 39|1@1+ (1,0) [0|1] "" Vector__XXX
 SG_ BMS_chgPowerAvailable : 40|12@1+ (0.125,0) [0|511.75] "kW" Vector__XXX
 SG_ BMS_chargeRetryCount : 53|3@1+ (1,0) [0|7] "" Vector__XXX
 SG_ BMS_conditioningRequest : 56|1@1+ (1,0) [0|1] "" Vector__XXX
 SG_ BMS_smStateRequest : 57|4@1+ (1,0) [0|15] "" Vector__XXX
 SG_ BMS_hvState : 61|3@1+ (1,0) [0|7] "" Vector__XXX

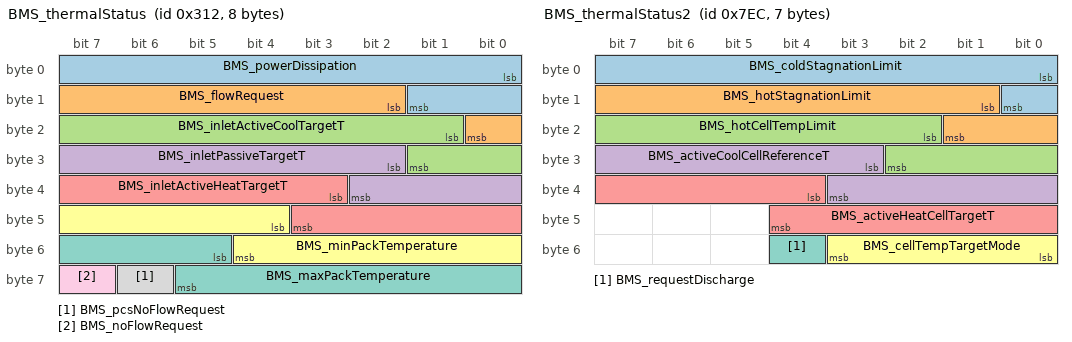
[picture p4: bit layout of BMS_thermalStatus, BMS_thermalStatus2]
BO_ 786 BMS_thermalStatus: 8 BMS
 SG_ BMS_powerDissipation : 0|10@1+ (0.02,0) [0|20] "kW" Vector__XXX
 SG_ BMS_flowRequest : 10|7@1+ (0.3,0) [0|38.1] "LPM" Vector__XXX
 SG_ BMS_inletActiveCoolTargetT : 17|9@1+ (0.25,-25) [-25|100] "DegC" Vector__XXX
 SG_ BMS_inletPassiveTargetT : 26|9@1+ (0.25,-25) [-25|100] "DegC" Vector__XXX
 SG_ BMS_inletActiveHeatTargetT : 35|9@1+ (0.25,-25) [-25|100] "DegC" Vector__XXX
 SG_ BMS_minPackTemperature : 44|9@1+ (0.25,-25) [-25|102.75] "DegC" Vector__XXX
 SG_ BMS_maxPackTemperature : 53|9@1+ (0.25,-25) [-25|102.75] "DegC" Vector__XXX
 SG_ BMS_pcsNoFlowRequest : 62|1@1+ (1,0) [0|1] "" Vector__XXX
 SG_ BMS_noFlowRequest : 63|1@1+ (1,0) [0|1] "" Vector__XXX

BO_ 2028 BMS_thermalStatus2: 7 BMS
 SG_ BMS_coldStagnationLimit : 0|9@1+ (0.25,-25) [-25|100] "DegC" Vector__XXX
 SG_ BMS_hotStagnationLimit : 9|9@1+ (0.25,-25) [-25|100] "DegC" Vector__XXX
 SG_ BMS_hotCellTempLimit : 18|9@1+ (0.25,-25) [-25|100] "DegC" Vector__XXX
 SG_ BMS_activeCoolCellReferenceT : 27|9@1+ (0.25,-25) [-25|100] "DegC" Vector__XXX
 SG_ BMS_activeHeatCellTargetT : 36|9@1+ (0.25,-25) [-25|100] "DegC" Vector__XXX
 SG_ BMS_cellTempTargetMode : 48|4@1+ (1,0) [0|15] "" Vector__XXX
 SG_ BMS_requestDischarge : 52|1@1+ (1,0) [0|1] "" Vector__XXX

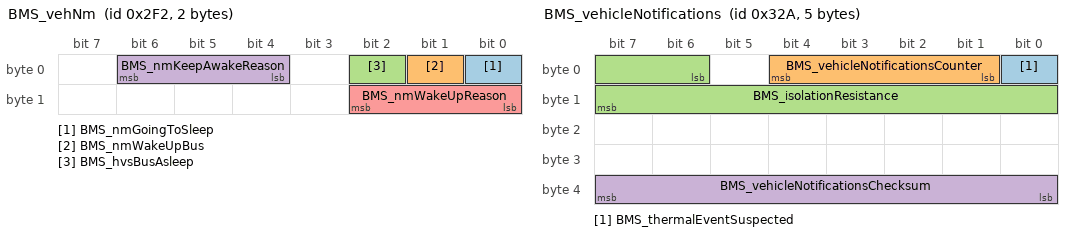
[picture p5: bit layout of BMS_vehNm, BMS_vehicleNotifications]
BO_ 754 BMS_vehNm: 2 BMS
 SG_ BMS_nmGoingToSleep : 0|1@1+ (1,0) [0|1] "" Vector__XXX
 SG_ BMS_nmWakeUpBus : 1|1@1+ (1,0) [0|1] "" Vector__XXX
 SG_ BMS_hvsBusAsleep : 2|1@1+ (1,0) [0|1] "" Vector__XXX
 SG_ BMS_nmKeepAwakeReason : 4|3@1+ (1,0) [1|7] "" Vector__XXX
 SG_ BMS_nmWakeUpReason : 8|3@1+ (1,0) [0|7] "" Vector__XXX

BO_ 810 BMS_vehicleNotifications: 5 BMS
 SG_ BMS_thermalEventSuspected : 0|1@1+ (1,0) [0|1] "" Vector__XXX
 SG_ BMS_vehicleNotificationsCounter : 1|4@1+ (1,0) [0|15] "" Vector__XXX
 SG_ BMS_isolationResistance : 6|10@1+ (10,0) [0|10000] "kOhm" Vector__XXX
 SG_ BMS_vehicleNotificationsChecksum : 32|8@1+ (1,0) [0|255] "" Vector__XXX

BO_ 797 CC_chgStatus2: 8 CC
 SG_ CC_chgStatus2Index M : 0|8@1+ (1,0) [0|255] "" Vector__XXX
 SG_ CC_buttonState m0 : 8|1@1+ (1,0) [0|1] "" Vector__XXX

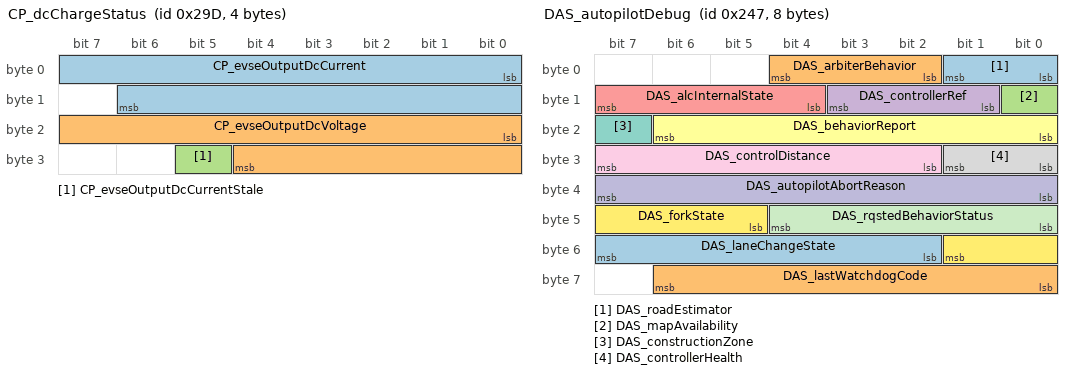
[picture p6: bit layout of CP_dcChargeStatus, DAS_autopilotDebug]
BO_ 669 CP_dcChargeStatus: 4 CP
 SG_ CP_evseOutputDcCurrent : 0|15@1- (0.125,0) [-2048|2047.875] "A" Vector__XXX
 SG_ CP_evseOutputDcVoltage : 16|13@1+ (0.07324219,0) [0|599.92675822] "V" Vector__XXX
 SG_ CP_evseOutputDcCurrentStale : 29|1@1+ (1,0) [0|1] "" Vector__XXX

BO_ 541 CP_evseStatus: 8 CP
 SG_ CP_evseAccept : 0|1@1+ (1,0) [0|1] "" Vector__XXX
 SG_ CP_evseRequest : 1|1@1+ (1,0) [0|1] "" Vector__XXX
 SG_ CP_proximity : 2|2@1+ (1,0) [1|3] "" Vector__XXX
 SG_ CP_pilot : 4|3@1+ (1,0) [0|6] "" Vector__XXX
 SG_ CP_digitalCommsEstablished : 7|1@1+ (1,0) [0|1] "" Vector__XXX
 SG_ CP_pilotCurrent : 8|8@1+ (0.5,0) [0|127.5] "A" Vector__XXX
 SG_ CP_cableType : 16|3@1+ (1,0) [0|7] "" Vector__XXX
 SG_ CP_iecPilotState : 19|4@1+ (1,0) [0|15] "" Vector__XXX
 SG_ CP_plcSupported : 23|1@1+ (1,0) [0|1] "" Vector__XXX
 SG_ CP_cableCurrentLimit : 24|7@1+ (1,0) [0|127] "A" Vector__XXX
 SG_ CP_teslaSwcanState : 34|4@1+ (1,0) [0|15] "" Vector__XXX
 SG_ CP_evseChargeType_UI : 38|2@1+ (1,0) [0|3] "" Vector__XXX
 SG_ CP_gbState : 40|4@1+ (1,0) [0|15] "" Vector__XXX
 SG_ CP_gbdcStopChargeReason : 44|4@1+ (1,0) [0|15] "" Vector__XXX
 SG_ CP_gbdcFailureReason : 48|2@1+ (1,0) [0|3] "" Vector__XXX
 SG_ CP_gbdcChargeAttempts : 50|2@1+ (1,0) [0|3] "" Vector__XXX
 SG_ CP_acChargeState : 52|3@1+ (1,0) [0|7] "" Vector__XXX
 SG_ CP_teslaDcState : 56|4@1+ (1,0) [0|15] "" Vector__XXX

BO_ 1885 CP_loggingFast: 8 CP
 SG_ CP_loggingFastSelect M : 0|4@1+ (1,0) [0|15] "" Vector__XXX
 SG_ CP_inductiveSensor_raw m0 : 4|28@1+ (1,0) [0|268435455] "" Vector__XXX
 SG_ CP_doorOpenActuationTime m0 : 32|14@1+ (1,0) [0|16383] "ms" Vector__XXX
 SG_ CP_doorCloseActuationTime m0 : 46|14@1+ (1,0) [0|16383] "ms" Vector__XXX
 SG_ CP_chargeCableSecured m0 : 60|1@1+ (1,0) [0|1] "" Vector__XXX
 SG_ CP_chargeCablePresent m0 : 61|1@1+ (1,0) [0|1] "" Vector__XXX
 SG_ CP_latchCheckAvailable m0 : 62|1@1+ (1,0) [0|1] "" Vector__XXX
 SG_ CP_UHF_controlState m2 : 4|4@1+ (1,0) [0|15] "" Vector__XXX
 SG_ CP_proximityV m2 : 8|16@1+ (0.0001,0) [0|6.5535] "V" Vector__XXX
 SG_ CP_proximityV_GBCC1 m2 : 24|14@1+ (0.001,0) [0|13.3] "V" Vector__XXX
 SG_ CP_proximityV_GBCC2 m2 : 38|14@1+ (0.001,0) [0|13.3] "V" Vector__XXX
 SG_ CP_doorPot m2 : 52|12@1+ (0.025,0) [0|100] "%" Vector__XXX
 SG_ CP_doorOpenRequest m3 : 16|4@1+ (1,0) [0|15] "" Vector__XXX
 SG_ CP_doorOpenEndOfDriveReason m3 : 20|3@1+ (1,0) [0|7] "" Vector__XXX
 SG_ CP_coverClosed m3 : 23|1@1+ (1,0) [0|1] "" Vector__XXX
 SG_ CP_doorCloseEndOfDriveReason m3 : 24|3@1+ (1,0) [0|7] "" Vector__XXX
 SG_ CP_doorCloseRequest m3 : 27|5@1+ (1,0) [0|31] "" Vector__XXX
 SG_ CP_latchDisengagingTime m3 : 32|10@1+ (1,0) [0|1023] "ms" Vector__XXX
 SG_ CP_latchEngagingTime m3 : 42|10@1+ (1,0) [0|1023] "ms" Vector__XXX
 SG_ CP_latchDisengagingStopReason m3 : 52|3@1+ (1,0) [0|7] "" Vector__XXX
 SG_ CP_latchEngagingStopReason m3 : 56|3@1+ (1,0) [0|7] "" Vector__XXX
 SG_ CP_doorIdDetectionState m3 : 59|2@1+ (1,0) [1|3] "" Vector__XXX
 SG_ CP_doorIdDetectedBin m3 : 61|2@1+ (1,0) [0|3] "" Vector__XXX

BO_ 2042 CP_loggingSlow: 8 CP
 SG_ CP_loggingSlowSelect M : 0|4@1+ (1,0) [0|15] "" Vector__XXX
 SG_ CP_UHF_chipState m3 : 4|3@1+ (1,0) [0|7] "" Vector__XXX
 SG_ CP_UHF_rssi m3 : 8|8@1+ (1,0) [0|255] "" Vector__XXX
 SG_ CP_UHF_rxOverflow m3 : 16|1@1+ (1,0) [0|1] "" Vector__XXX
 SG_ CP_UHF_rxNumBytes m3 : 17|8@1+ (1,0) [0|255] "" Vector__XXX
 SG_ CP_UHF_selfTestRssi m3 : 25|8@1+ (1,0) [0|255] "" Vector__XXX
 SG_ CP_latchI m3 : 33|12@1+ (0.0025,0) [0|10.2375] "A" Vector__XXX
 SG_ CP_inlet1HarnessIdState m3 : 45|2@1+ (1,0) [1|3] "" Vector__XXX
 SG_ CP_inlet1HarnessIdValue m3 : 47|3@1+ (1,0) [0|7] "" Vector__XXX
 SG_ CP_inlet2HarnessIdState m3 : 50|2@1+ (1,0) [1|3] "" Vector__XXX
 SG_ CP_inlet2HarnessIdValue m3 : 52|3@1+ (1,0) [0|7] "" Vector__XXX
 SG_ CP_inletHeaterState m3 : 55|2@1+ (1,0) [0|3] "" Vector__XXX
 SG_ CP_inletHeaterDuty m3 : 57|7@1+ (1,0) [0|100] "%" Vector__XXX
 SG_ CP_nvm_dataValid m5 : 4|1@1+ (1,0) [0|1] "" Vector__XXX
 SG_ CP_nvm_doorOpenCycles m5 : 8|16@1+ (1,0) [0|65535] "" Vector__XXX
 SG_ CP_nvm_doorCloseCycles m5 : 24|16@1+ (1,0) [0|65535] "" Vector__XXX
 SG_ CP_nvm_doorOpen m5 : 40|1@1+ (1,0) [0|1] "" Vector__XXX
 SG_ CP_nvm_doorPresent m5 : 41|1@1+ (1,0) [0|1] "" Vector__XXX
 SG_ CP_nvm_doorPresentValid m5 : 42|1@1+ (1,0) [0|1] "" Vector__XXX
 SG_ CP_nvm_badPilotDiodeDetected m5 : 43|1@1+ (1,0) [0|1] "" Vector__XXX
 SG_ CP_nvm_pilotDiodeFaultCount m5 : 44|3@1+ (1,0) [0|7] "" Vector__XXX
 SG_ CP_doorOpenLimiterMaxCount m5 : 47|4@1+ (1,0) [0|15] "counts" Vector__XXX
 SG_ CP_doorOpenLimiterMaxRequestType m5 : 51|4@1+ (1,0) [0|15] "" Vector__XXX
 SG_ CP_doorCloseLimiterMaxCount m5 : 55|4@1+ (1,0) [0|15] "counts" Vector__XXX
 SG_ CP_doorCloseLimiterMaxRequestTyp m5 : 59|5@1+ (1,0) [0|31] "" Vector__XXX

BO_ 528 CP_status: 8 CP
 SG_ CP_type : 0|2@1+ (1,0) [0|3] "" Vector__XXX
 SG_ CP_insertEnableLine : 2|1@1+ (1,0) [0|1] "" Vector__XXX
 SG_ CP_latchState : 3|2@1+ (1,0) [1|3] "" Vector__XXX
 SG_ CP_permanentPowerRequest : 5|1@1+ (1,0) [0|1] "" Vector__XXX
 SG_ CP_chargeDoorOpen : 6|1@1+ (1,0) [0|1] "" Vector__XXX
 SG_ CP_doorControlState : 8|3@1+ (1,0) [0|7] "" Vector__XXX
 SG_ CP_doorButtonPressed : 11|1@1+ (1,0) [0|1] "" Vector__XXX
 SG_ CP_swcanRelayClosed : 12|1@1+ (1,0) [0|1] "" Vector__XXX
 SG_ CP_inhibitOta : 13|1@1+ (1,0) [0|1] "" Vector__XXX
 SG_ CP_chargeCableState : 14|2@1+ (1,0) [1|3] "" Vector__XXX
 SG_ CP_latchControlState : 16|3@1+ (1,0) [0|7] "" Vector__XXX
 SG_ CP_ledColor : 19|4@1+ (1,0) [0|15] "" Vector__XXX
 SG_ CP_UHF_handleFound : 23|1@1+ (1,0) [0|1] "" Vector__XXX
 SG_ CP_faultLineSensed : 24|1@1+ (1,0) [0|1] "" Vector__XXX
 SG_ CP_doorPresenceState : 25|3@1+ (1,0) [0|7] "" Vector__XXX
 SG_ CP_inductiveSensorState : 28|3@1+ (1,0) [0|7] "" Vector__XXX
 SG_ CP_chargeDoorOpenUI : 31|1@1+ (1,0) [0|1] "" Vector__XXX
 SG_ CP_vehicleUnlockRequest : 32|1@1+ (1,0) [0|1] "" Vector__XXX
 SG_ CP_coldWeatherMode : 33|1@1+ (1,0) [0|1] "" Vector__XXX
 SG_ CP_latchEngaged : 35|1@1+ (1,0) [0|1] "" Vector__XXX
 SG_ CP_inletHeaterUiState : 40|3@1+ (1,0) [0|7] "" Vector__XXX

BO_ 893 CP_thermalStatus: 8 CP
 SG_ CP_thermalStatusSelect M : 0|1@1+ (1,0) [0|1] "" Vector__XXX
 SG_ CP_pinTemperature1 m1 : 8|8@1+ (0.8039216,-55) [-55|149.99] "C" Vector__XXX
 SG_ CP_pinTemperature2 m1 : 16|8@1+ (0.8039216,-55) [-55|149.99] "C" Vector__XXX
 SG_ CP_pinTemperature3 m1 : 24|8@1+ (0.8039216,-55) [-55|149.99] "C" Vector__XXX

BO_ 583 DAS_autopilotDebug: 8 DAS
 SG_ DAS_roadEstimator : 0|2@1+ (1,0) [0|3] "" Vector__XXX
 SG_ DAS_arbiterBehavior : 2|3@1+ (1,0) [0|7] "" Vector__XXX
 SG_ DAS_mapAvailability : 8|1@1+ (1,0) [0|1] "" Vector__XXX
 SG_ DAS_controllerRef : 9|3@1+ (1,0) [0|7] "" Vector__XXX
 SG_ DAS_alcInternalState : 12|4@1+ (1,0) [0|15] "" Vector__XXX
 SG_ DAS_behaviorReport : 16|7@1+ (1,0) [0|127] "" Vector__XXX
 SG_ DAS_constructionZone : 23|1@1+ (1,0) [0|1] "" Vector__XXX
 SG_ DAS_controllerHealth : 24|2@1+ (1,0) [0|3] "" Vector__XXX
 SG_ DAS_controlDistance : 26|6@1+ (2,0) [0|126] "m" Vector__XXX
 SG_ DAS_autopilotAbortReason : 32|8@1+ (1,0) [0|255] "" Vector__XXX
 SG_ DAS_rqstedBehaviorStatus : 40|5@1+ (1,0) [0|31] "" Vector__XXX
 SG_ DAS_forkState : 45|5@1+ (1,0) [0|31] "" Vector__XXX
 SG_ DAS_laneChangeState : 50|6@1+ (1,0) [0|63] "" Vector__XXX
 SG_ DAS_lastWatchdogCode : 56|7@1+ (1,0) [0|127] "" Vector__XXX

BO_ 2041 DAS_gpsStatus: 8 DAS
 SG_ DAS_gpsStatusMultiplexer M : 0|4@1+ (1,0) [0|15] "" Vector__XXX
 SG_ DAS_gpsTransportModeState m0 : 4|1@1+ (1,0) [0|1] "" Vector__XXX
 SG_ DAS_gpsSatsInUseHardware m0 : 5|4@1+ (1,0) [0|15] "" Vector__XXX
 SG_ DAS_gpsRejectingSatData m0 : 57|1@1+ (1,0) [0|1] "" Vector__XXX
 SG_ DAS_gpsWheelsOffMotionDetected m0 : 58|1@1+ (1,0) [0|1] "" Vector__XXX
 SG_ DAS_gpsFixTypeHardware m0 : 59|3@1+ (1,0) [0|7] "" Vector__XXX
 SG_ DAS_gpsRawxEnabled m0 : 62|1@1+ (1,0) [0|1] "" Vector__XXX
 SG_ DAS_gpsRxmRawxMia m1 : 4|1@1+ (1,0) [0|1] "" Vector__XXX
 SG_ DAS_gpsRxmSfrbxMia m1 : 5|1@1+ (1,0) [0|1] "" Vector__XXX
 SG_ DAS_gpsEsfMeasMia m1 : 6|1@1+ (1,0) [0|1] "" Vector__XXX
 SG_ DAS_gpsEsfRawMia m1 : 7|1@1+ (1,0) [0|1] "" Vector__XXX
 SG_ DAS_gpsNavStatusMia m1 : 8|1@1+ (1,0) [0|1] "" Vector__XXX
 SG_ DAS_gpsSoftwareConfigured m1 : 9|1@1+ (1,0) [0|1] "" Vector__XXX
 SG_ DAS_gpsSoftwareUsed m1 : 10|1@1+ (1,0) [0|1] "" Vector__XXX
 SG_ DAS_gpsSoftwareFastStartReady m1 : 11|1@1+ (1,0) [0|1] "" Vector__XXX
 SG_ DAS_gpsSatsInUseSoftware m1 : 12|4@1+ (1,0) [0|15] "" Vector__XXX
 SG_ DAS_gpsFixTypeSoftware m1 : 16|3@1+ (1,0) [0|7] "" Vector__XXX
 SG_ DAS_gpsCWJammingInidcator m1 : 19|5@1+ (8,0) [0|248] "-" Vector__XXX
 SG_ DAS_gpsJammingState m1 : 24|2@1+ (1,0) [0|3] "" Vector__XXX
 SG_ DAS_gpsSpoofDetectorState m1 : 26|2@1+ (1,0) [0|3] "" Vector__XXX
 SG_ DAS_gpsInvalidMsgPercentage m1 : 28|4@1+ (6,0) [0|90] "%" Vector__XXX
 SG_ DAS_gnssConstellationsState m1 : 32|2@1+ (1,0) [0|3] "" Vector__XXX
 SG_ DAS_gpsReceiverNoiseLevel m1 : 34|6@1+ (8,0) [0|504] "-" Vector__XXX
 SG_ DAS_gpsAutomaticGainControl m1 : 40|8@1+ (32,0) [0|8160] "-" Vector__XXX
 SG_ DAS_gpsPreviousPositionDeltaHw m1 : 48|6@1+ (3,0) [0|189] "m" Vector__XXX
 SG_ DAS_gpsPreviousPositionDeltaSw m1 : 54|6@1+ (3,0) [0|189] "m" Vector__XXX
 SG_ DAS_gpsNmeaDispatchFailureCount m1 : 60|4@1+ (5,0) [0|75] "-" Vector__XXX
 SG_ DAS_gnssMaxInstantaneousCnorGps m2 : 4|6@1+ (1,0) [0|63] "" Vector__XXX
 SG_ DAS_gnssMaxInstantaneousCnorGal m2 : 10|6@1+ (1,0) [0|63] "" Vector__XXX
 SG_ DAS_gnssMaxInstantaneousCnorBds m2 : 16|6@1+ (1,0) [0|63] "" Vector__XXX
 SG_ DAS_gpsResetReason m2 : 22|4@1+ (1,0) [0|15] "" Vector__XXX
 SG_ DAS_gpsAccuracyHorizontal m2 : 26|6@1+ (1,0) [0|63] "m" Vector__XXX
 SG_ DAS_gpsAccuracyVertical m2 : 32|6@1+ (1,0) [0|63] "m" Vector__XXX
 SG_ DAS_gpsSolutionFallback m2 : 38|1@1+ (1,0) [0|1] "" Vector__XXX
 SG_ DAS_gpsToMcuSource m2 : 39|3@1+ (1,0) [0|7] "" Vector__XXX
 SG_ DAS_gpsSolutionSoc m2 : 42|2@1+ (1,0) [0|3] "" Vector__XXX
 SG_ DAS_gpsRedundancyActive m2 : 44|1@1+ (1,0) [0|1] "" Vector__XXX
 SG_ DAS_gpsFixTypeSoftwareSocB m2 : 45|3@1+ (1,0) [0|7] "" Vector__XXX
 SG_ DAS_gpsSatsInUseSoftwareSocB m2 : 48|4@1+ (1,0) [0|15] "" Vector__XXX
 SG_ DAS_gnssNumSatsGps m3 : 4|4@1+ (1,0) [0|15] "" Vector__XXX
 SG_ DAS_gnssNumSatsGal m3 : 8|4@1+ (1,0) [0|15] "" Vector__XXX
 SG_ DAS_gnssNumSatsBds m3 : 12|4@1+ (1,0) [0|15] "" Vector__XXX
 SG_ DAS_gnssAvgInstantaneousCnorGps m3 : 16|6@1+ (1,0) [0|63] "" Vector__XXX
 SG_ DAS_gnssAvgInstantaneousCnorGal m3 : 22|6@1+ (1,0) [0|63] "" Vector__XXX
 SG_ DAS_gnssAvgInstantaneousCnorBds m3 : 28|6@1+ (1,0) [0|63] "" Vector__XXX
 SG_ DAS_gnssAvgInstantaneousCnorGpsL m3 : 46|6@1+ (1,0) [0|63] "" Vector__XXX
 SG_ DAS_gnssAvgInstantaneousCnorGalL m3 : 52|6@1+ (1,0) [0|63] "" Vector__XXX
 SG_ DAS_gnssAvgInstantaneousCnorBdsL m3 : 58|6@1+ (1,0) [0|63] "" Vector__XXX

BO_TX_BU_ 1383 : ADSP;
BO_TX_BU_ 600 : APB;
BO_TX_BU_ 909 : APP;
BO_TX_BU_ 2046 : APP;
BO_TX_BU_ 1040 : APP;
BO_TX_BU_ 603 : APP;
BO_TX_BU_ 601 : APP;
BO_TX_BU_ 2044 : APS;
BO_TX_BU_ 970 : APS;
BO_TX_BU_ 943 : BB;
BO_TX_BU_ 1138 : BMS;
BO_TX_BU_ 2029 : BMS;
BO_TX_BU_ 306 : BMS;
BO_TX_BU_ 884 : BMS;
BO_TX_BU_ 946 : BMS;
BO_TX_BU_ 914 : BMS;
BO_TX_BU_ 594 : BMS;
BO_TX_BU_ 674 : BMS;
BO_TX_BU_ 658 : BMS;
BO_TX_BU_ 530 : BMS;
BO_TX_BU_ 786 : BMS;
BO_TX_BU_ 2028 : BMS;
BO_TX_BU_ 754 : BMS;
BO_TX_BU_ 810 : BMS;
BO_TX_BU_ 797 : CC;
BO_TX_BU_ 669 : CP;
BO_TX_BU_ 541 : CP;
BO_TX_BU_ 1885 : CP;
BO_TX_BU_ 2042 : CP;
BO_TX_BU_ 528 : CP;
BO_TX_BU_ 893 : CP;
BO_TX_BU_ 583 : DAS;
BO_TX_BU_ 2041 : DAS;

CM_ "Tesla Model 3 CAN bus database; bus ETH (Ethernet-side ids, not CAN ids); firmware 2025.20.8. Decoded CAN signal definitions (layout, scaling, units, value tables).";
CM_ BU_ ADSP "Audio amplifier";
CM_ BU_ APB "APB ECU";
CM_ BU_ APP "Driver assistance computer (primary)";
CM_ BU_ APS "Driver assistance computer (secondary)";
CM_ BU_ BB "BB ECU";
CM_ BU_ BMS "High-voltage battery management system";
CM_ BU_ CC "Charge cable controller";
CM_ BU_ CP "Charge port controller";
CM_ BU_ DAS "Driver assistance computer";
CM_ BU_ DI "Drive inverter";
CM_ BU_ DIF "Front drive inverter";
CM_ BU_ DIR "Rear drive inverter";
CM_ BU_ EPAS3P "Electric power steering (primary)";
CM_ BU_ EPAS3S "Electric power steering (secondary)";
CM_ BU_ EPBL "Left electric parking brake";
CM_ BU_ EPBR "Right electric parking brake";
CM_ BU_ GTW "Gateway";
CM_ BU_ HVP "High-voltage processor (pack contactor and isolation controller)";
CM_ BU_ ICR "ICR ECU";
CM_ BU_ IDB "IDB ECU";
CM_ BU_ PCS "Power conversion system (on-board charger and DC-DC converter)";
CM_ BU_ PM "PM ECU";
CM_ BU_ TCU "TCU ECU";
CM_ BU_ UI "Touchscreen user interface computer";
CM_ BU_ UIS "UIS ECU";
CM_ BU_ VC "VC ECU";
CM_ BU_ VCFRONT "Front body controller";
CM_ BU_ VCLEFT "Left body controller";
CM_ BU_ VCRIGHT "Right body controller";
CM_ BU_ VCSEC "Vehicle security controller";
CM_ BO_ 1383 "Audio amplifier message: state";
CM_ SG_ 1383 ADSP_a2baState "Reports the state of the Automotive Audio Bus A (A2B-A) network.";
CM_ SG_ 1383 ADSP_a2bbState "Reports the state of the Automotive Audio Bus B (A2B-B) network.";
CM_ SG_ 1383 ADSP_baseamp0State "Audio amplifier: baseamp0 state";
CM_ SG_ 1383 ADSP_baseamp1State "Audio amplifier: baseamp1 state";
CM_ SG_ 1383 ADSP_baseamp2State "Audio amplifier: baseamp2 state";
CM_ SG_ 1383 ADSP_baseamp3State "Audio amplifier: baseamp3 state";
CM_ SG_ 1383 ADSP_audioReady "Audio is ready";
CM_ SG_ 1383 ADSP_tcuI2SEnabled "Reports whether the Telematics Control Unit (TCU) Integrated-circuit Sound (I2S) clock is enabled.";
CM_ SG_ 1383 ADSP_ancState "Reports the state of the Active Noise Canceling (ANC) Digital Signal Processing (DSP).";
CM_ SG_ 1383 ADSP_telephonyRxMute "Reports the telephony receive mute status.";
CM_ SG_ 1383 ADSP_sourceSelect "Reports the current audio source.";
CM_ SG_ 1383 ADSP_tunerSelect "Audio amplifier: tuner select";
CM_ SG_ 1383 ADSP_ancMode "Reports the Active Noise Cancelling (ANC) mode.";
CM_ SG_ 1383 ADSP_spkMuteAll "Reports when all audio speakers are muted.";
CM_ SG_ 1383 ADSP_allAudioReady "Reports when all audio peripherals are ready.";
CM_ SG_ 1383 ADSP_callState "Reports the current call state.";
CM_ SG_ 1383 ADSP_telephonyTxMute "Reports the telephony transmit mute status.";
CM_ SG_ 1383 ADSP_eCall_ENS_state "ADSP-ECALL-ENS state";
CM_ SG_ 1383 ADSP_eCallSelfTest "eCall seft-test result";
CM_ SG_ 1383 ADSP_eCallState "eCall State";
CM_ SG_ 1383 ADSP_eCallMicrophoneStatus "status of microphone";
CM_ SG_ 1383 ADSP_eCallSpeakerStatus "status of eCall speakers";
CM_ SG_ 1383 ADSP_a2baLoadShedded "Audio amplifier: a2ba load shedded";
CM_ SG_ 1383 ADSP_requestFailoverSpeaker "Reports requests for failover speaker for chimes.";
CM_ BO_ 600 "APB ECU message: status";
CM_ SG_ 600 APB_watchdogState "State of system watchdog on ParkerB; raw 7 = signal not available (SNA)";
CM_ SG_ 600 APB_fusedState "APB ECU: fused state; raw 3 = signal not available (SNA)";
CM_ SG_ 600 APB_cameraHeaterRequest "Indicates if heater grid is active because of request from Autopilot (AP) cameras.";
CM_ SG_ 600 APB_factorySummonStatus "APB ECU: factory summon status; raw 0 = signal not available (SNA)";
CM_ SG_ 600 APB_clipRecordingStatus "APB ECU: clip recording status";
CM_ SG_ 600 APB_summonUnavailableReason "Reports the reason why smart summon is currently unavailable.";
CM_ SG_ 600 APB_fsdSuspendState "APB ECU: fsd suspend state; raw 3 = signal not available (SNA)";
CM_ SG_ 600 APB_fsdRevokeStrikeoutCount "APB ECU: fsd revoke strikeout count; raw 7 = signal not available (SNA)";
CM_ SG_ 600 APB_teslaVisionSupported "APB ECU: tesla vision supported; raw 3 = signal not available (SNA)";
CM_ SG_ 600 APB_teslaVisionUnsupportedReason "APB ECU: tesla vision unsupported reason";
CM_ SG_ 600 APB_fsdRevokeCount "APB ECU: fsd revoke count; raw 7 = signal not available (SNA)";
CM_ SG_ 600 APB_excessiveAccelPedalWarning "Indicates that driver is using acceleration pedal continuously and excessively.";
CM_ SG_ 600 APB_unifiedObjectStackSupported "APB ECU: unified object stack supported; raw 3 = signal not available (SNA)";
CM_ SG_ 600 APB_DDAWSystemStatus "Reports the Driver Drowsiness and Attention Warning (DDAW) system status; raw 4 = signal not available (SNA)";
CM_ SG_ 600 APB_socOperatingMode "Reports the operating mode of the System on Chip (SoC).";
CM_ SG_ 600 APB_summonVersionIdentifier "APB ECU: summon version identifier";
CM_ SG_ 600 APB_sentryState "Reports the Sentry mode state on Hardware 4 (HW4) and later vehicles; raw 6 = signal not available (SNA)";
CM_ SG_ 600 APB_autoparkVersionIdentifier "Indicates which version of autopark will actively control the vehicle during user interactions.";
CM_ SG_ 600 APB_suspendResumeAvailable "APB ECU: suspend resume available";
CM_ SG_ 600 APB_statusCounter "APB ECU: status counter";
CM_ SG_ 600 APB_statusChecksum "APB ECU: status checksum";
CM_ BO_ 909 "Driver assistance computer (primary) message: VC info message";
CM_ SG_ 909 APP_inTunnel "Driver assistance computer (primary): in tunnel; raw 0 = signal not available (SNA)";
CM_ SG_ 909 APP_windshieldHeaterOnReason "Reports the reason why Autopilot (AP) is turning windshield heater on; raw 0 = signal not available (SNA)";
CM_ SG_ 909 APP_selfieCameraBlocked "Indicates if the selfie camera is currently blocked, or if this selfie camera model doesn't report lux; raw 0 = signal not available (SNA)";
CM_ SG_ 909 APP_selfieCameraLUX "Reports lux reading. Note that selfie camera lux is not currently calibrated against other cameras so the range is different; raw 255 = signal not available (SNA)";
CM_ SG_ 909 APP_sceneTagClearlyRaining "Indicates if the vision scene tag is clearly raining; raw 0 = signal not available (SNA)";
CM_ SG_ 909 APP_sceneTagFog "Indicates if the vision scene tag detects fog; raw 0 = signal not available (SNA)";
CM_ SG_ 909 APP_sceneTagFullyBlocked "Indicates if the vision scene tag detects a fully blocked view; raw 0 = signal not available (SNA)";
CM_ SG_ 909 APP_sceneTagIndoors "Indicates if the vision scene tag detects an indoor environment; raw 0 = signal not available (SNA)";
CM_ SG_ 909 APP_sceneTagLensFlare "Indicates if the vision scene tag detects lens flare; raw 0 = signal not available (SNA)";
CM_ SG_ 909 APP_sceneTagRaining "Indicates if the vision scene tag detects raining conditions; raw 0 = signal not available (SNA)";
CM_ SG_ 909 APP_sceneTagSevereWeather "Indicates if the vision scene tag detects severe weather conditions; raw 0 = signal not available (SNA)";
CM_ SG_ 909 APP_sceneTagSnowing "Indicates if the vision scene tag detects snowing conditions; raw 0 = signal not available (SNA)";
CM_ SG_ 909 APP_sceneTagSnowyRoad "Indicates if the vision scene tag detects snowy road conditions; raw 0 = signal not available (SNA)";
CM_ SG_ 909 APP_sceneTagSunGlare "Indicates if the vision scene tag detects sun glare conditions; raw 0 = signal not available (SNA)";
CM_ SG_ 909 APP_sceneTagTunnel "Indicates if the vision scene tag detects a tunnel environment; raw 0 = signal not available (SNA)";
CM_ SG_ 909 APP_sceneTagWetRoad "Indicates if the vision scene tag detects wet road conditions; raw 0 = signal not available (SNA)";
CM_ SG_ 909 APP_fisheyeInPathVisibility "Driver assistance computer (primary): fisheye in path visibility; raw 0 = signal not available (SNA)";
CM_ SG_ 909 APP_fisheyeOverallVisibility "Driver assistance computer (primary): fisheye overall visibility; raw 0 = signal not available (SNA)";
CM_ SG_ 909 APP_mainInPathVisibility "Driver assistance computer (primary): main in path visibility; raw 0 = signal not available (SNA)";
CM_ SG_ 909 APP_mainOverallVisibility "Driver assistance computer (primary): main overall visibility; raw 0 = signal not available (SNA)";
CM_ SG_ 909 APP_narrowInPathVisibility "Driver assistance computer (primary): narrow in path visibility; raw 0 = signal not available (SNA)";
CM_ SG_ 909 APP_narrowOverallVisibility "Driver assistance computer (primary): narrow overall visibility; raw 0 = signal not available (SNA)";
CM_ SG_ 909 APP_frontCamOcclusionType "Reports the current type of what is obstructing the front camera vision.";
CM_ BO_ 2046 "Driver assistance computer (primary) message: cam calibration status";
CM_ SG_ 2046 APP_cameraPosition "Driver assistance computer (primary): camera position";
CM_ SG_ 2046 APP_mainCamExtPitchCal "The calibration, pitch or yaw offset of a camera; raw 511 = signal not available (SNA)";
CM_ SG_ 2046 APP_mainCamExtYawCal "The calibration, pitch or yaw offset of a camera; raw 511 = signal not available (SNA)";
CM_ SG_ 2046 APP_mainCalibTime "Driver assistance computer (primary): main calib time; raw 127 = signal not available (SNA)";
CM_ SG_ 2046 APP_mainCalibProgress "The percent progress of the main camera calibration; raw 127 = signal not available (SNA)";
CM_ SG_ 2046 APP_mainCalibrated "Whether or not the main camera is calibrated.";
CM_ SG_ 2046 APP_narrowCamExtPitchCal "The calibration, pitch or yaw offset of a camera; raw 511 = signal not available (SNA)";
CM_ SG_ 2046 APP_narrowCamExtYawCal "The calibration, pitch or yaw offset of a camera; raw 511 = signal not available (SNA)";
CM_ SG_ 2046 APP_narrowCalibTime "Driver assistance computer (primary): narrow calib time; raw 127 = signal not available (SNA)";
CM_ SG_ 2046 APP_narrowCalibProgress "The percent progress of the narrow camera calibration; raw 127 = signal not available (SNA)";
CM_ SG_ 2046 APP_narrowCalibrated "Whether or not the narrow camera is calibrated.";
CM_ SG_ 2046 APP_fisheyeCamExtPitchCal "The calibration, pitch or yaw offset of a camera; raw 511 = signal not available (SNA)";
CM_ SG_ 2046 APP_fisheyeCamExtYawCal "The calibration, pitch or yaw offset of a camera; raw 511 = signal not available (SNA)";
CM_ SG_ 2046 APP_fisheyeCalibTime "Driver assistance computer (primary): fisheye calib time; raw 127 = signal not available (SNA)";
CM_ SG_ 2046 APP_fisheyeCalibProgress "The percent progress of the fisheye camera calibration; raw 127 = signal not available (SNA)";
CM_ SG_ 2046 APP_fisheyeCalibrated "Whether or not the fisheye camera is calibrated.";
CM_ SG_ 2046 APP_lPillarCamExtPitchCal "The calibration, pitch or yaw offset of a camera; raw 511 = signal not available (SNA)";
CM_ SG_ 2046 APP_lPillarCamExtYawCal "The calibration, pitch or yaw offset of a camera; raw 511 = signal not available (SNA)";
CM_ SG_ 2046 APP_lPillarCalibTime "Driver assistance computer (primary): l pillar calib time; raw 127 = signal not available (SNA)";
CM_ SG_ 2046 APP_lPillarCalibProgress "The percent progress of the left pillar camera calibration; raw 127 = signal not available (SNA)";
CM_ SG_ 2046 APP_lPillarCalibrated "Whether or not the left pillar camera is calibrated.";
CM_ SG_ 2046 APP_rPillarCamExtPitchCal "The calibration, pitch or yaw offset of a camera; raw 511 = signal not available (SNA)";
CM_ SG_ 2046 APP_rPillarCamExtYawCal "The calibration, pitch or yaw offset of a camera; raw 511 = signal not available (SNA)";
CM_ SG_ 2046 APP_rPillarCalibTime "Driver assistance computer (primary): r pillar calib time; raw 127 = signal not available (SNA)";
CM_ SG_ 2046 APP_rPillarCalibProgress "The percent progress of the right pillar camera calibration; raw 127 = signal not available (SNA)";
CM_ SG_ 2046 APP_rPillarCalibrated "Whether or not the right pillar camera is calibrated.";
CM_ SG_ 2046 APP_lRepeatCamExtPitchCal "The calibration, pitch or yaw offset of a camera; raw 511 = signal not available (SNA)";
CM_ SG_ 2046 APP_lRepeatCamExtYawCal "The calibration, pitch or yaw offset of a camera; raw 511 = signal not available (SNA)";
CM_ SG_ 2046 APP_lRepeatCalibTime "Driver assistance computer (primary): l repeat calib time; raw 127 = signal not available (SNA)";
CM_ SG_ 2046 APP_lRepeatCalibProgress "The percent progress of the left repeater camera calibration; raw 127 = signal not available (SNA)";
CM_ SG_ 2046 APP_lRepeatCalibrated "Whether or not the left repeater camera is calibrated.";
CM_ SG_ 2046 APP_rRepeatCamExtPitchCal "The calibration, pitch or yaw offset of a camera; raw 511 = signal not available (SNA)";
CM_ SG_ 2046 APP_rRepeatCamExtYawCal "The calibration, pitch or yaw offset of a camera; raw 511 = signal not available (SNA)";
CM_ SG_ 2046 APP_rRepeatCalibTime "Driver assistance computer (primary): r repeat calib time; raw 127 = signal not available (SNA)";
CM_ SG_ 2046 APP_rRepeatCalibProgress "The percent progress of the right repeater camera calibration; raw 127 = signal not available (SNA)";
CM_ SG_ 2046 APP_rRepeatCalibrated "Whether or not the right repeater camera is calibrated.";
CM_ SG_ 2046 APP_backupCamExtPitchCal "The calibration, pitch or yaw offset of a camera; raw 511 = signal not available (SNA)";
CM_ SG_ 2046 APP_backupCamExtYawCal "The calibration, pitch or yaw offset of a camera; raw 511 = signal not available (SNA)";
CM_ SG_ 2046 APP_backupCalibTime "Driver assistance computer (primary): backup calib time; raw 127 = signal not available (SNA)";
CM_ SG_ 2046 APP_backupCalibProgress "The percent progress of the backup calibration; raw 127 = signal not available (SNA)";
CM_ SG_ 2046 APP_backupCalibrated "Whether or not the backup camera is calibrated.";
CM_ BO_ 1040 "Driver assistance computer (primary) message: camera status";
CM_ SG_ 1040 APP_backupCameraFeedGood "Indicates if the backup camera stream is healthy.";
CM_ SG_ 1040 APP_backupCameraFrameRate "The backup camera frame rate.";
CM_ SG_ 1040 APP_cameraBlockedFrontMain "Indicates that a blockage was detected by the main forward camera.";
CM_ SG_ 1040 APP_cameraBlockedFrontFisheye "Indicates that a blockage was detected by the fisheye camera.";
CM_ SG_ 1040 APP_cameraBlockedFrontNarrow "Indicates that a blockage was detected by the narrow camera.";
CM_ SG_ 1040 APP_cameraBlockedLeftPillar "Indicates that a blockage was detected by the left pillar camera.";
CM_ SG_ 1040 APP_cameraBlockedLeftRepeater "Indicates that a blockage was detected by the left repeater camera.";
CM_ SG_ 1040 APP_cameraBlockedRightPillar "Indicates that a blockage was detected by the right pillar camera.";
CM_ SG_ 1040 APP_cameraBlockedRightRepeater "Indicates that a blockage was detected by the right repeater camera.";
CM_ SG_ 1040 APP_cameraBlockedBackup "Indicates that a blockage was detected by the backup camera.";
CM_ BO_ 603 "Driver assistance computer (primary) message: environment";
CM_ SG_ 603 APP_environmentRainy "Driver assistance computer (primary): environment rainy";
CM_ SG_ 603 APP_environmentSnowy "Driver assistance computer (primary): environment snowy";
CM_ BO_ 601 "Driver assistance computer (primary) message: status";
CM_ SG_ 601 APP_watchdogState "State of system watchdog on ParkerB; raw 7 = signal not available (SNA)";
CM_ SG_ 601 APP_fusedState "Driver assistance computer (primary): fused state; raw 3 = signal not available (SNA)";
CM_ SG_ 601 APP_cameraHeaterRequest "Indicates if heater grid is active because of request from AP cameras.";
CM_ SG_ 601 APP_factorySummonStatus "Driver assistance computer (primary): factory summon status; raw 0 = signal not available (SNA)";
CM_ SG_ 601 APP_clipRecordingStatus "Driver assistance computer (primary): clip recording status";
CM_ SG_ 601 APP_allowApActivationWithBrake "Indicates whether Autopilot (AP) activation while brake pressed is allowed.";
CM_ SG_ 601 APP_summonUnavailableReason "The reason why smart summon is currently unavailable.";
CM_ SG_ 601 APP_fsdSuspendState "If FSD feature is suspended on this car; raw 3 = signal not available (SNA)";
CM_ SG_ 601 APP_fsdRevokeStrikeoutCount "Reports the number of strikeouts counted towards revoking Full Self-Driving (FSD) feature; raw 7 = signal not available (SNA)";
CM_ SG_ 601 APP_teslaVisionSupported "Whether autopilot can support tesla vision; raw 3 = signal not available (SNA)";
CM_ SG_ 601 APP_teslaVisionUnsupportedReason "Reason for vehicle not supporting tesla vision";
CM_ SG_ 601 APP_fsdRevokeCount "Reports the number of times the car has had Full Self-Driving (FSD) revoked; raw 7 = signal not available (SNA)";
CM_ SG_ 601 APP_excessiveAccelPedalWarning "Indicates that driver is using acceleration pedal continously and excessively";
CM_ SG_ 601 APP_unifiedObjectStackSupported "Whether autopilot can support unified objects stack for tesla vision; raw 3 = signal not available (SNA)";
CM_ SG_ 601 APP_DDAWSystemStatus "DDAW system status; raw 4 = signal not available (SNA)";
CM_ SG_ 601 APP_socOperatingMode "Operating Mode of the SOC";
CM_ SG_ 601 APP_summonVersionIdentifier "Driver assistance computer (primary): summon version identifier";
CM_ SG_ 601 APP_sentryState "Reports the Sentry mode state on Gen. 4 Hardware (HW4) and later vehicles; raw 6 = signal not available (SNA)";
CM_ SG_ 601 APP_autoparkVersionIdentifier "Driver assistance computer (primary): autopark version identifier";
CM_ SG_ 601 APP_suspendResumeAvailable "Driver assistance computer (primary): suspend resume available";
CM_ SG_ 601 APP_statusCounter "Driver assistance computer (primary): status counter";
CM_ SG_ 601 APP_statusChecksum "Driver assistance computer (primary): status checksum";
CM_ BO_ 2044 "Driver assistance computer (secondary) message: state";
CM_ SG_ 2044 APS_primaryTurbo "Which of the two Turbos currently holds the primary role.";
CM_ SG_ 2044 APS_A_arbState "The state of the arbitration state machine of Turbo A.";
CM_ SG_ 2044 APS_A_powerState "The state of the power state machine of Turbo A.";
CM_ SG_ 2044 APS_A_sleepState "The state of the sleep state machine of Turbo A.";
CM_ SG_ 2044 APS_A_resetState "The state of the reset state machine of Turbo A.";
CM_ SG_ 2044 APS_A_faultState "The state of the fault state machine of Turbo A.";
CM_ SG_ 2044 APS_secondaryTurbo "Which of the two Turbos currently holds the secondary role.";
CM_ SG_ 2044 APS_B_arbState "The state of the arbitration state machine of Turbo B.";
CM_ SG_ 2044 APS_B_powerState "The state of the power state machine of Turbo B.";
CM_ SG_ 2044 APS_B_sleepState "The state of the sleep state machine of Turbo B.";
CM_ SG_ 2044 APS_B_resetState "The state of the reset state machine of Turbo B.";
CM_ SG_ 2044 APS_B_faultState "The state of the fault state machine of Turbo B.";
CM_ SG_ 2044 APS_stateCounter "Driver assistance computer (secondary): state counter";
CM_ BO_ 970 "Driver assistance computer (secondary) message: status";
CM_ SG_ 970 APS_appStatusMonitorState "The current status of APE, indicates the health of the stack on the APE";
CM_ SG_ 970 APS_vehBehaviorState "Driver assistance computer (secondary): veh behavior state";
CM_ SG_ 970 APS_canMaster "Indicates which of the autopilot computers is currently controlling outgoing CAN traffic; raw 3 = signal not available (SNA)";
CM_ SG_ 970 APS_appGpioState "The GPIO state of APEA, indicates the health of the primary Parker (HW2 and HW2.5)";
CM_ SG_ 970 APS_eacInternalState "Indicates the internal state of the external angle control monitor running on Aurix.";
CM_ SG_ 970 APS_switchState "Driver assistance computer (secondary): switch state";
CM_ SG_ 970 APS_apbStatusMonitorState "The current status of APEB, indicates the health of the stack on the APEB";
CM_ SG_ 970 APS_apbGpioState "The GPIO state of APEB, indicates the health of the secondary Parker (HW2.5 only)";
CM_ SG_ 970 APS_statusCounter "Driver assistance computer (secondary): status counter";
CM_ SG_ 970 APS_locLimitReason "Indicates why longitudinal control limits are currently not relaxed";
CM_ SG_ 970 APS_appPowerStateRequest "Indicates ap primary power state request";
CM_ SG_ 970 APS_appPowerStateReason "Indicates ap primary power state reason";
CM_ SG_ 970 APS_apbPowerStateRequest "Indicates ap backup power state request";
CM_ SG_ 970 APS_apbPowerStateReason "Indicates ap backup power state reason";
CM_ SG_ 970 APS_heaterStateDebug "Driver assistance computer (secondary): heater state debug; raw 7 = signal not available (SNA)";
CM_ SG_ 970 APS_autosummonCounter "Driver assistance computer (secondary): autosummon counter";
CM_ SG_ 970 APS_autosummonAlert "Driver assistance computer (secondary): autosummon alert";
CM_ SG_ 970 APS_gpsAntennaState "Driver assistance computer (secondary): gps antenna state";
CM_ SG_ 970 APS_arbState "Reports the state of the arbitration state machine of this System on Chip (SoC).";
CM_ SG_ 970 APS_socPowerOperatingMode "Reports the total number of System on Chips (SoCs) that are powered on to provide support for active Autopilot features.";
CM_ SG_ 970 APS_otherArbState "Reports the state of the arbitration state machine of the other System on Chip (SoC). Lets the current SoC know the state of the other SoC to achieve safer operations.";
CM_ BO_ 943 "BB ECU message: status";
CM_ SG_ 943 BB_statusChecksum "BB ECU: status checksum";
CM_ SG_ 943 BB_statusCounter "BB ECU: status counter";
CM_ SG_ 943 BB_sOutputRod "Reports the measured brake booster (BB) plunger piston position";
CM_ SG_ 943 BB_sOutputRodQF "Reports the BB_sOutputRod signal qualifier";
CM_ SG_ 943 BB_sInputRod "Reports the measured brake booster (BB) input rod stroke.";
CM_ SG_ 943 BB_sInputRodQF "Reports the BB_sInputRod signal qualifier.";
CM_ SG_ 943 BB_driverBrakeApply "Indicates whether the driver operates the brake pedal. Only active when the driver brakes, not when an external brake command implemented on brake booster (BB).";
CM_ SG_ 943 BB_driverBrakeApplyQF "Qualifier for BB_driverBrakeApply";
CM_ SG_ 943 BB_boosterStatus "Indication of the brake booster (BB) functional state";
CM_ SG_ 943 BB_warningLampRequest "Request from brake booster (BB) to enable the red brake lamp";
CM_ SG_ 943 BB_brakeFluidLevel "Indication of the brake fluid reservoir fluid level sensor status measured by the brake booster (BB).";
CM_ SG_ 943 BB_internalState "Indication of the brake booster (BB) internal state";
CM_ BO_ 1138 "High-voltage battery management system message: charge info";
CM_ SG_ 1138 BMS_cellChargeDcCurrentLimit "DC current target based on cell voltage & temp tables";
CM_ SG_ 1138 BMS_voltageRegCurrentTarget "DC current target based on voltage regulator";
CM_ SG_ 1138 BMS_vehicleChargeDcCurrentLimit "Charge current target after all aggregating all vehicle-side limits, exclude EVSE limits";
CM_ SG_ 1138 BMS_chargeCurrentLimitMode "BMS charging current limiting factor";
CM_ SG_ 1138 BMS_timeToFinishHeatForCharge "High-voltage battery management system: time to finish heat for charge; raw 127 = signal not available (SNA)";
CM_ SG_ 1138 BMS_diNodeModelTemp "High-voltage battery management system: di node model temp; raw 2047 = signal not available (SNA)";
CM_ BO_ 2029 "High-voltage battery management system message: debug info 10 hz";
CM_ SG_ 2029 BMS_10HzDebug_Id "High-voltage battery management system: 10 hz debug id";
CM_ SG_ 2029 BMS_activeCoolCellTargetT "High-voltage battery management system: active cool cell target t";
CM_ SG_ 2029 BMS_passiveCoolCellTargetT "High-voltage battery management system: passive cool cell target t";
CM_ BO_ 306 "High-voltage battery management system message: hv bus status";
CM_ SG_ 306 BMS_packVoltage "Measures voltage on the battery side of the High Voltage (HV) contactors.";
CM_ SG_ 306 BMS_packCurrent "Current measured at the HV contactors of the HV battery; raw 32768 = signal not available (SNA)";
CM_ SG_ 306 BMS_currentUnfiltered "Pack current with no filters applied; raw 32768 = signal not available (SNA)";
CM_ SG_ 306 BMS_chgTimeToFull "Estimated time remaining until charge termination percent will be reached; raw 4095 = signal not available (SNA)";
CM_ BO_ 884 "High-voltage battery management system message: log1";
CM_ SG_ 884 BMS_log1MuxId "High-voltage battery management system: log1 mux id";
CM_ SG_ 884 BMS_extDcPrechargeVoltageLimit "High-voltage battery management system: ext dc precharge voltage limit";
CM_ SG_ 884 BMS_dcChargeCurrentRequest "The BMS's instantaneous DC charge current request to the EVSE";
CM_ SG_ 884 BMS_dcChargeCurrentLimit "The vehicle's charge current limit on a DC EVSE's output";
CM_ SG_ 884 BMS_dcDischargeEnabled "High-voltage battery management system: dc discharge enabled";
CM_ SG_ 884 BMS_rippleChargeRetryCount "High-voltage battery management system: ripple charge retry count";
CM_ SG_ 884 BMS_dcChargeVoltageLimit "The vehicle's charge voltage limit on a DC EVSE's output";
CM_ SG_ 884 BMS_dcChargePowerLimit "Max power limit for pack during DC charging";
CM_ SG_ 884 BMS_maxExtIsoFcLinkV "The max voltage read on the FC link during the external isolation check";
CM_ SG_ 884 BMS_socByDeltaVEnabled "High-voltage battery management system: soc by delta v enabled";
CM_ SG_ 884 BMS_socByDvMaxSocLimit "High-voltage battery management system: soc by dv max soc limit";
CM_ SG_ 884 BMS_socByDvVoltageChangeOverAh "High-voltage battery management system: soc by dv voltage change over ah";
CM_ SG_ 884 BMS_socByDvMaxSocByAhCorrected "High-voltage battery management system: soc by dv max soc by ah corrected";
CM_ SG_ 884 BMS_socByDvMaxBrickVoltage "High-voltage battery management system: soc by dv max brick voltage";
CM_ SG_ 884 BMS_socByDvMaxBrickId "High-voltage battery management system: soc by dv max brick id";
CM_ BO_ 946 "High-voltage battery management system message: log2";
CM_ SG_ 946 BMS_log2MuxId "High-voltage battery management system: log2 mux id";
CM_ SG_ 946 BMS_cacAvg "BMS Calculated Ah Capacity (CAC). This is the average of all the brick CACs";
CM_ SG_ 946 BMS_cacMin "BMS Calculated Ah Capacity (CAC). This is the min of all the brick CACs";
CM_ SG_ 946 BMS_cacMinBrickId "High-voltage battery management system: cac min brick id";
CM_ SG_ 946 BMS_cacMax "BMS Calculated Ah Capacity (CAC). This is the max of all the brick CACs";
CM_ SG_ 946 BMS_cacMaxBrickId "High-voltage battery management system: cac max brick id";
CM_ SG_ 946 BMS_acRippleConfigNvramValid "High-voltage battery management system: ac ripple config nvram valid";
CM_ SG_ 946 BMS_hvChain_useLeakyBucket "Is the leaky bucket being used - an indicator of the HV Chain Model health";
CM_ SG_ 946 BMS_hvChain_iLimit "High-voltage battery management system: hv chain i limit; raw 16383 = signal not available (SNA)";
CM_ SG_ 946 BMS_hvChain_limitingState "High-voltage battery management system: hv chain limiting state; raw 511 = signal not available (SNA)";
CM_ SG_ 946 BMS_hvChain_limitingStateTempera "High-voltage battery management system: hv chain limiting state temperature; raw 4096 = signal not available (SNA)";
CM_ SG_ 946 BMS_acRippleIsSupported "High-voltage battery management system: ac ripple is supported";
CM_ SG_ 946 BMS_acRippleStartTemperatureMax "High-voltage battery management system: ac ripple start temperature max";
CM_ SG_ 946 BMS_acRippleStartTemperatureMin "High-voltage battery management system: ac ripple start temperature min";
CM_ SG_ 946 BMS_fcLinkTestDecayTime "High-voltage battery management system: fc link test decay time; raw 1023 = signal not available (SNA)";
CM_ SG_ 946 BMS_fcLinkTestTimeSinceLastRun "High-voltage battery management system: fc link test time since last run";
CM_ SG_ 946 BMS_pcsPrechargeTargetVoltage "Target voltage for precharging HV bus";
CM_ SG_ 946 BMS_recentOvUvAlert "At least one of the Brick OV or UV alerts has been active recently; consumed by BMS_a049_SW_Thermal_Event set condition";
CM_ SG_ 946 BMS_recentIsoAlert "At least one of the isolation alerts has been active recently; consumed by BMS_a049_SW_Thermal_Event set condition";
CM_ SG_ 946 BMS_recentBmbMiaAlert "At least one of the BMB communication alerts has been active recently; consumed by BMS_a049_SW_Thermal_Event set condition";
CM_ SG_ 946 BMS_cacBlendingConfigNvramValid "High-voltage battery management system: cac blending config nvram valid";
CM_ SG_ 946 BMS_cacBlendingEnabled "High-voltage battery management system: cac blending enabled";
CM_ SG_ 946 BMS_cacBlendPercentPerCycle "High-voltage battery management system: cac blend percent per cycle";
CM_ SG_ 946 BMS_energyVariableChgRequested "High-voltage battery management system: energy variable chg requested";
CM_ SG_ 946 BMS_packRestTime "Minimum resting time of all bricks";
CM_ SG_ 946 BMS_idealEnergyFloor "Ideal energy estimate based on the min bounded SOC that accounts for accumulated shunt error; raw 1023 = signal not available (SNA)";
CM_ SG_ 946 BMS_thmGradientSlopeCondition "High-voltage battery management system: thm gradient slope condition";
CM_ SG_ 946 BMS_recentSlopeConditon "High-voltage battery management system: recent slope conditon";
CM_ SG_ 946 BMS_dynamicEnergyBuffer "BMS estimate of energy error based on SOC measurement inaccuracy; raw 1023 = signal not available (SNA)";
CM_ SG_ 946 BMS_temperatureCondition "High-voltage battery management system: temperature condition";
CM_ SG_ 946 BMS_thmGradientSlope "High-voltage battery management system: thm gradient slope";
CM_ SG_ 946 BMS_thmGradient "High-voltage battery management system: thm gradient";
CM_ SG_ 946 BMS_dSocNormalizedMin "High-voltage battery management system: d soc normalized min; raw 4095 = signal not available (SNA)";
CM_ SG_ 946 BMS_dSocNormalizedFiltMin "High-voltage battery management system: d soc normalized filt min; raw 4095 = signal not available (SNA)";
CM_ SG_ 946 BMS_dSocMinAlpha "minimum calculated alpha value across all bricks and all dSOC calculations; raw 4095 = signal not available (SNA)";
CM_ SG_ 946 BMS_dSocMaxLowAlphaCounter "High-voltage battery management system: d soc max low alpha counter";
CM_ SG_ 946 BMS_dSocMinAlphaBrickID "High-voltage battery management system: d soc min alpha brick ID";
CM_ SG_ 946 BMS_dSocCacMargin "High-voltage battery management system: d soc cac margin; raw 511 = signal not available (SNA)";
CM_ SG_ 946 BMS_lifeModelAvgTempSeverity "High-voltage battery management system: life model avg temp severity; raw 31 = signal not available (SNA)";
CM_ SG_ 946 BMS_lifeModelDepthOfDischargeSev "High-voltage battery management system: life model depth of discharge severity; raw 255 = signal not available (SNA)";
CM_ SG_ 946 BMS_lifeModelHistogramCapacityLo "High-voltage battery management system: life model histogram capacity loss; raw 511 = signal not available (SNA)";
CM_ SG_ 946 BMS_lifeModelHistogramBrickCapac "High-voltage battery management system: life model histogram brick capacity; raw 8191 = signal not available (SNA)";
CM_ SG_ 946 BMS_lifeModelDcrGrowthPercent "High-voltage battery management system: life model dcr growth percent; raw 8192 = signal not available (SNA)";
CM_ SG_ 946 BMS_nominalFullPackEnergyRaw "Non-latched version of BMS_nominalEnergyRemaining; raw 65535 = signal not available (SNA)";
CM_ SG_ 946 BMS_userChargeCalibratingReason "High-voltage battery management system: user charge calibrating reason";
CM_ SG_ 946 BMS_nominalEnergyRemainingBuffer "Buffered version of BMS_nominalEnergyRemaining; raw 65535 = signal not available (SNA)";
CM_ SG_ 946 BMS_idealEnergyRemainingBuffered "Buffered version of BMS_idealEnergyRemaining; raw 65535 = signal not available (SNA)";
CM_ SG_ 946 BMS_largestCacSpreadErrorLower "High-voltage battery management system: largest cac spread error lower; raw 4095 = signal not available (SNA)";
CM_ SG_ 946 BMS_lifeModelAverageCac "High-voltage battery management system: life model average cac; raw 4095 = signal not available (SNA)";
CM_ SG_ 946 BMS_lifeModelCacBrick1 "High-voltage battery management system: life model cac brick1; raw 4095 = signal not available (SNA)";
CM_ SG_ 946 BMS_lifeModelAverageOffset "High-voltage battery management system: life model average offset; raw 512 = signal not available (SNA)";
CM_ SG_ 946 BMS_percentCacUpdatesInTimeWindo "High-voltage battery management system: percent cac updates in time window";
CM_ SG_ 946 BMS_lifeModelMaxCacBrickId "High-voltage battery management system: life model max cac brick id; raw 255 = signal not available (SNA)";
CM_ SG_ 946 BMS_lifeModelMaxCac "High-voltage battery management system: life model max cac; raw 4095 = signal not available (SNA)";
CM_ SG_ 946 BMS_lifeModelMinCacBrickId "High-voltage battery management system: life model min cac brick id; raw 255 = signal not available (SNA)";
CM_ SG_ 946 BMS_lifeModelMinCac "High-voltage battery management system: life model min cac; raw 4095 = signal not available (SNA)";
CM_ SG_ 946 BMS_restingPointCacAvg "High-voltage battery management system: resting point cac avg; raw 4095 = signal not available (SNA)";
CM_ SG_ 946 BMS_cacEstimationSource "High-voltage battery management system: cac estimation source";
CM_ SG_ 946 BMS_synchronizedCacMaxRaw "High-voltage battery management system: synchronized cac max raw; raw 4095 = signal not available (SNA)";
CM_ SG_ 946 BMS_synchronizedCacMinRaw "High-voltage battery management system: synchronized cac min raw; raw 4095 = signal not available (SNA)";
CM_ SG_ 946 BMS_largestSyncCacErrorStartSoc "Start SOC for CAC update from the brick with the highest synchronized CAC error";
CM_ SG_ 946 BMS_largestSyncCacErrorEndSoc "Start SOC for CAC update from the brick with the highest synchronized CAC error";
CM_ SG_ 946 BMS_runtimeSocConfigNvramValid "High-voltage battery management system: runtime soc config nvram valid";
CM_ SG_ 946 BMS_runtimeSocCorrectionsEnabled "High-voltage battery management system: runtime soc corrections enabled";
CM_ SG_ 946 BMS_rubberBandingEnabled "Reports whether rubber banding of output energy corrections is enabled.";
CM_ SG_ 946 BMS_rubberBandingConfigNvramVali "High-voltage battery management system: rubber banding config nvram valid";
CM_ SG_ 946 BMS_runtimeSocMinTempForModel "High-voltage battery management system: runtime soc min temp for model";
CM_ SG_ 946 BMS_energyBufferConfigNvramValid "High-voltage battery management system: energy buffer config nvram valid";
CM_ SG_ 946 BMS_thermalEvent1pDetectConfigDi "High-voltage battery management system: thermal event1p detect config disabled";
CM_ SG_ 946 BMS_sohEnergy "Battery SOH energy estimate. If calibrated SOH capacity is unavailable, this value is a filtered result from brick CACs; raw 2047 = signal not available (SNA)";
CM_ SG_ 946 BMS_fullCapacitySohEnergy "Energy estimate using nominal brick capacity at maximum SOC using SOH retention test conditions; raw 2047 = signal not available (SNA)";
CM_ SG_ 946 BMS_calibratedCapacitySohEnergy "Energy estimate using CAC from the most recent valid SOH test at maximum SOC using SOH retention test conditions; raw 2047 = signal not available (SNA)";
CM_ SG_ 946 BMS_estimatedCapacitySohEnergy "Energy estimate using filtered brick capacities at maximum SOC using SOH retention test conditions; raw 2047 = signal not available (SNA)";
CM_ SG_ 946 BMS_prevUserFacingSohEnergy "The last soh energy stored in NVM for rate limiting purposes; raw 2047 = signal not available (SNA)";
CM_ SG_ 946 BMS_stateOfHealthMinCac "Reports the minimum Calculated Amp-hour Capacity (CAC) by aged Open Circuit Voltage (OCV) raw values across bricks that could be used in State of Health (SOH) calculations; raw 8191 = signal not available (SNA)";
CM_ SG_ 946 BMS_lifeModelStorageLossPackAge "High-voltage battery management system: life model storage loss pack age; raw 16383 = signal not available (SNA)";
CM_ SG_ 946 BMS_lifeModelThroughputCycleCoun "High-voltage battery management system: life model throughput cycle count; raw 4095 = signal not available (SNA)";
CM_ SG_ 946 BMS_lifeModelThroughputDcrCycleC "High-voltage battery management system: life model throughput dcr cycle count; raw 4095 = signal not available (SNA)";
CM_ SG_ 946 BMS_energyWalkCounter "High-voltage battery management system: energy walk counter";
CM_ SG_ 946 BMS_energyWalkTimeoutCounter "High-voltage battery management system: energy walk timeout counter";
CM_ SG_ 946 BMS_dynamicCcvEnabled "High-voltage battery management system: dynamic ccv enabled";
CM_ SG_ 946 BMS_chargeTargetLookupSoc "High-voltage battery management system: charge target lookup soc";
CM_ SG_ 946 BMS_stateOfHealth "Most recent battery capacity estimate, from a successful SOH test in %; raw 1023 = signal not available (SNA)";
CM_ BO_ 914 "High-voltage battery management system message: pack config";
CM_ SG_ 914 BMS_packConfigMultiplexer "High-voltage battery management system: pack config multiplexer";
CM_ SG_ 914 BMS_reservedConfig_0 "High-voltage battery management system: reserved config 0";
CM_ SG_ 914 BMS_moduleType "High-voltage battery management system: module type";
CM_ SG_ 914 BMS_thermalPackType "High-voltage battery management system: thermal pack type";
CM_ SG_ 914 BMS_packMass "High-voltage battery management system: pack mass";
CM_ SG_ 914 BMS_platformMaxBusVoltage "High-voltage battery management system: platform max bus voltage";
CM_ SG_ 914 BMS_standbySupplyContinuousPower "High-voltage battery management system: standby supply continuous power limit";
CM_ BO_ 594 "High-voltage battery management system message: power available";
CM_ SG_ 594 BMS_maxRegenPower "Calculated max regen power";
CM_ SG_ 594 BMS_maxDischargePower "Calculated max discharge power possible based on max discharge current and sum of loaded voltages";
CM_ SG_ 594 BMS_maxStationaryHeatPower "Maximum heating power the DI can produce when in stationary heating mode";
CM_ SG_ 594 BMS_powerLimitsState "High-voltage battery management system: power limits state";
CM_ SG_ 594 BMS_notEnoughPowerForHeatPump "Flag indicating the min pack power is lower than specified threshold to support heating with the heat pump";
CM_ SG_ 594 BMS_instantChargePowerCapability "Indicates the instantaneous charge power capability of the high voltage battery; raw 65535 = signal not available (SNA)";
CM_ BO_ 674 "High-voltage battery management system message: ripple request";
CM_ SG_ 674 BMS_acRippleCurrentAmplitudeLimi "Transmits the Battery Management System (BMS) AC ripple current amplitude limit to the Electric Vehicle Supply Equipment (EVSE).";
CM_ SG_ 674 BMS_acRippleMaxVoltageLimit "Reports the maximum voltage limit when the Electric Vehicle Supply Equipment (EVSE) is performing the AC ripple.";
CM_ SG_ 674 BMS_acRippleMinVoltageLimit "Reports the minimum voltage limit when the Electric Vehicle Supply Equipment (EVSE) is performing the AC ripple.";
CM_ SG_ 674 BMS_acRippleFrequencyRequest "Transmits the Battery Management System (BMS) AC ripple frequency request to the Electric Vehicle Supply Equipment (EVSE); raw 63 = signal not available (SNA)";
CM_ SG_ 674 BMS_acRippleCurrentAmplitudeRequ "Transmits the Battery Management System (BMS) AC ripple current amplitude request to the Electric Vehicle Supply Equipment (EVSE).";
CM_ SG_ 674 BMS_acRippleRequest "High-voltage battery management system: ac ripple request";
CM_ BO_ 658 "High-voltage battery management system message: soc status";
CM_ SG_ 658 BMS_socMin "BMS State Of Charge (SOC). This is the minimum brick SOC.";
CM_ SG_ 658 BMS_socUI "BMS State Of Energy (SOE) for the UI. This is ideal discharge energy from present state / ideal discharge energy from full.";
CM_ SG_ 658 BMS_socMax "BMS State Of Charge (SOC). This is the maximum brick SOC.";
CM_ SG_ 658 BMS_socAvg "BMS State Of Charge (SOC). This is the average of all the brick SOCs";
CM_ SG_ 658 BMS_beginningOfLifePackEnergy "High-voltage battery management system: beginning of life pack energy; raw 1023 = signal not available (SNA)";
CM_ SG_ 658 BMS_battTempPct "High-voltage battery management system: batt temp pct; raw 255 = signal not available (SNA)";
CM_ SG_ 658 BMS_userChargeCurrentLimitMode "BMS' user-facing reason for charge being either limited or not limited";
CM_ BO_ 530 "High-voltage battery management system message: status";
CM_ SG_ 530 BMS_hvacPowerRequest "High-voltage battery management system: hvac power request";
CM_ SG_ 530 BMS_notEnoughPowerForDrive "Flag indicating the min pack power is lower than specified threshold to support drive";
CM_ SG_ 530 BMS_notEnoughPowerForSupport "Flag indicating if the system can support a new request for 12V battery support";
CM_ SG_ 530 BMS_preconditionAllowed "High-voltage battery management system: precondition allowed";
CM_ SG_ 530 BMS_updateAllowed "High-voltage battery management system: update allowed";
CM_ SG_ 530 BMS_activeHeatingWorthwhile "Determination by the Battery Management System (BMS) if active heating is worthwhile";
CM_ SG_ 530 BMS_cpMiaOnHvs "Flag indicating that BMS is no longer receiving comms from CP on HVS bus";
CM_ SG_ 530 BMS_pcsPwmEnabled "Reports the state of the PCS_PWM_ENABLE input on the HVBMS, which is derived from the P1-12-DCDC-ENABLE input, which comes from VCFRONT";
CM_ SG_ 530 BMS_contactorState "BMS Contactor Status; raw 0 = signal not available (SNA)";
CM_ SG_ 530 BMS_userChargeStatus "BMS charge status for UI display. Renamed from BMS_uiChargeStatus";
CM_ SG_ 530 BMS_chargeRequest "Indicates charge is available and charge is desired";
CM_ SG_ 530 BMS_state "BMS operating state; raw 9 = signal not available (SNA)";
CM_ SG_ 530 BMS_diLimpRequest "BMS request to DI to enter limp mode";
CM_ SG_ 530 BMS_okToShipByAir "High-voltage battery management system: ok to ship by air";
CM_ SG_ 530 BMS_okToShipByLand "High-voltage battery management system: ok to ship by land";
CM_ SG_ 530 BMS_chgPowerAvailable "BMS available charge power; raw 4095 = signal not available (SNA)";
CM_ SG_ 530 BMS_chargeRetryCount "Number of retries remaining to enable charge";
CM_ SG_ 530 BMS_conditioningRequest "BMS request to enable conditioning so it can attempt FEIM recovery";
CM_ SG_ 530 BMS_smStateRequest "BMS high level state request; raw 9 = signal not available (SNA)";
CM_ SG_ 530 BMS_hvState "BMS high voltage state";
CM_ BO_ 786 "High-voltage battery management system message: thermal status";
CM_ SG_ 786 BMS_powerDissipation "High-voltage battery management system: power dissipation";
CM_ SG_ 786 BMS_flowRequest "Requested coolant flow rate in liters per minute (LPM) from the Battery Management System (BMS) to the thermal module";
CM_ SG_ 786 BMS_inletActiveCoolTargetT "Calculated active cooling temperature target at the inlet";
CM_ SG_ 786 BMS_inletPassiveTargetT "Calculated passive temperature target at the inlet";
CM_ SG_ 786 BMS_inletActiveHeatTargetT "Calculated active heating temperature target at the inlet";
CM_ SG_ 786 BMS_minPackTemperature "Minimum pack temperature for consumption by external entities";
CM_ SG_ 786 BMS_maxPackTemperature "Maximum pack temperature for consumption by external entities";
CM_ SG_ 786 BMS_pcsNoFlowRequest "High-voltage battery management system: pcs no flow request";
CM_ SG_ 786 BMS_noFlowRequest "High-voltage battery management system: no flow request";
CM_ BO_ 2028 "High-voltage battery management system message: thermal status2";
CM_ SG_ 2028 BMS_coldStagnationLimit "Minimum temperature at which the pack is allowed to be used as a heat-energy source";
CM_ SG_ 2028 BMS_hotStagnationLimit "Maximum temperature at which we allow the pack to be used for heat-energy storage";
CM_ SG_ 2028 BMS_hotCellTempLimit "Maximum temperature at which the pack will allow limp mode levels of current";
CM_ SG_ 2028 BMS_activeCoolCellReferenceT "Desired cell temperature reference which composes the temperature trajectory portion of the active cooling target temperature controls";
CM_ SG_ 2028 BMS_activeHeatCellTargetT "Desired cell temperature which feeds as an input to the active heating target temperature, before any additional controls calculations";
CM_ SG_ 2028 BMS_cellTempTargetMode "Operating mode of the thermal controls for the Battery Management System (BMS)";
CM_ SG_ 2028 BMS_requestDischarge "Flag identifying when the Battery Management System (BMS) is requesting the battery pack to be discharged";
CM_ BO_ 754 "High-voltage battery management system message: veh nm";
CM_ SG_ 754 BMS_nmGoingToSleep "High-voltage battery management system: nm going to sleep";
CM_ SG_ 754 BMS_nmWakeUpBus "High-voltage battery management system: nm wake up bus";
CM_ SG_ 754 BMS_hvsBusAsleep "HVS bus reported as off";
CM_ SG_ 754 BMS_nmKeepAwakeReason "BMS' determined reason to keep CAN awake; raw 0 = signal not available (SNA)";
CM_ SG_ 754 BMS_nmWakeUpReason "BMS' determined reason to wake up CAN";
CM_ BO_ 810 "High-voltage battery management system message: vehicle notifications";
CM_ SG_ 810 BMS_thermalEventSuspected "Indicates the Battery Management System (BMS) has detected conditions that reflect a possible battery thermal event";
CM_ SG_ 810 BMS_vehicleNotificationsCounter "High-voltage battery management system: vehicle notifications counter";
CM_ SG_ 810 BMS_isolationResistance "Resistance between HV bus and chassis; raw 1023 = signal not available (SNA)";
CM_ SG_ 810 BMS_vehicleNotificationsChecksum "High-voltage battery management system: vehicle notifications checksum";
CM_ BO_ 797 "Charge cable controller message: chg status2";
CM_ SG_ 797 CC_chgStatus2Index "Charge cable controller: chg status2 index";
CM_ SG_ 797 CC_buttonState "Charge cable controller: button state";
CM_ BO_ 669 "Charge port controller message: dc charge status";
CM_ SG_ 669 CP_evseOutputDcCurrent "The DC EVSE's measured output current";
CM_ SG_ 669 CP_evseOutputDcVoltage "The DC EVSE's measured output voltage";
CM_ SG_ 669 CP_evseOutputDcCurrentStale "Indicates whether the data in CP_evseOutputDcCurrent has not been updated with new info from the DC EVSE recently";
CM_ BO_ 541 "Charge port controller message: evse status";
CM_ SG_ 541 CP_evseAccept "State of pilot EVSE accept state";
CM_ SG_ 541 CP_evseRequest "Request to close AC EVSE relays, used when digital communications have been established";
CM_ SG_ 541 CP_proximity "Sensed state of proximity for all inlets; raw 0 = signal not available (SNA)";
CM_ SG_ 541 CP_pilot "State of EVSE pilot signal sensed by the charge port; raw 7 = signal not available (SNA)";
CM_ SG_ 541 CP_digitalCommsEstablished "Indicates whether digital communications have been established with an EVSE";
CM_ SG_ 541 CP_pilotCurrent "Line current limit detected from pilot signal";
CM_ SG_ 541 CP_cableType "Type of charge cable detected; raw 4 = signal not available (SNA)";
CM_ SG_ 541 CP_iecPilotState "State of the control pilot as defined in IEC-61851-1; raw 9 = signal not available (SNA)";
CM_ SG_ 541 CP_plcSupported "Indicates whether PLC hardware is populated for CCS charging support";
CM_ SG_ 541 CP_cableCurrentLimit "Charge port controller: cable current limit";
CM_ SG_ 541 CP_teslaSwcanState "Charge port controller: tesla swcan state";
CM_ SG_ 541 CP_evseChargeType_UI "Reports the type of Electric Vehicle Supply Equipment (EVSE) connected.";
CM_ SG_ 541 CP_gbState "State of GB DC charging";
CM_ SG_ 541 CP_gbdcStopChargeReason "Reason for stopping GB DC charging";
CM_ SG_ 541 CP_gbdcFailureReason "Reason for failure of GB DC charging";
CM_ SG_ 541 CP_gbdcChargeAttempts "Number of GB DC charging retries used";
CM_ SG_ 541 CP_acChargeState "Charge port controller: ac charge state";
CM_ SG_ 541 CP_teslaDcState "Reports the state of the Tesla direct current (DC) state machine.";
CM_ BO_ 1885 "Charge port controller message: logging fast";
CM_ SG_ 1885 CP_loggingFastSelect "Charge port controller: logging fast select";
CM_ SG_ 1885 CP_inductiveSensor_raw "Charge port controller: inductive sensor raw";
CM_ SG_ 1885 CP_doorOpenActuationTime "Charge port controller: door open actuation time";
CM_ SG_ 1885 CP_doorCloseActuationTime "Charge port controller: door close actuation time";
CM_ SG_ 1885 CP_chargeCableSecured "Indicates whether a charge cable is secured in any inlet";
CM_ SG_ 1885 CP_chargeCablePresent "Indicates whether a charge cable is present in any inlet";
CM_ SG_ 1885 CP_latchCheckAvailable "Charge port controller: latch check available";
CM_ SG_ 1885 CP_UHF_controlState "Control state of UHF receiver";
CM_ SG_ 1885 CP_proximityV "Charge port controller: proximity v";
CM_ SG_ 1885 CP_proximityV_GBCC1 "Sensed voltage of GB DC inlet CC1 connection";
CM_ SG_ 1885 CP_proximityV_GBCC2 "Sensed voltage of GB DC inlet CC2 connection";
CM_ SG_ 1885 CP_doorPot "Position of the charge port door potentiometer";
CM_ SG_ 1885 CP_doorOpenRequest "Door open request trigger";
CM_ SG_ 1885 CP_doorOpenEndOfDriveReason "Reason why the door stopped moving in the open direction";
CM_ SG_ 1885 CP_coverClosed "Charge port controller: cover closed";
CM_ SG_ 1885 CP_doorCloseEndOfDriveReason "Reason why the door stopped moving in the closing direction";
CM_ SG_ 1885 CP_doorCloseRequest "Door close request trigger";
CM_ SG_ 1885 CP_latchDisengagingTime "Charge port controller: latch disengaging time";
CM_ SG_ 1885 CP_latchEngagingTime "Charge port controller: latch engaging time";
CM_ SG_ 1885 CP_latchDisengagingStopReason "Reason why the latch stopped moving in the engaged direction";
CM_ SG_ 1885 CP_latchEngagingStopReason "Reason why the latch stopped moving in the engaged direction";
CM_ SG_ 1885 CP_doorIdDetectionState "Charge port controller: door id detection state; raw 0 = signal not available (SNA)";
CM_ SG_ 1885 CP_doorIdDetectedBin "Charge port controller: door id detected bin";
CM_ BO_ 2042 "Charge port controller message: logging slow";
CM_ SG_ 2042 CP_loggingSlowSelect "Charge port controller: logging slow select";
CM_ SG_ 2042 CP_UHF_chipState "Charge port controller: UHF chip state";
CM_ SG_ 2042 CP_UHF_rssi "Signal strength of received UHF signal";
CM_ SG_ 2042 CP_UHF_rxOverflow "Charge port controller: UHF rx overflow";
CM_ SG_ 2042 CP_UHF_rxNumBytes "Charge port controller: UHF rx num bytes";
CM_ SG_ 2042 CP_UHF_selfTestRssi "Signal strength of received self-test UHF signal";
CM_ SG_ 2042 CP_latchI "Charge port controller: latch i";
CM_ SG_ 2042 CP_inlet1HarnessIdState "State of the CP's inlet 1 harness pedigree; raw 0 = signal not available (SNA)";
CM_ SG_ 2042 CP_inlet1HarnessIdValue "Pedigree of the CP's inlet 1 harness";
CM_ SG_ 2042 CP_inlet2HarnessIdState "State of the CP's inlet 2 harness pedigree; raw 0 = signal not available (SNA)";
CM_ SG_ 2042 CP_inlet2HarnessIdValue "Pedigree of the CP's inlet 2 harness";
CM_ SG_ 2042 CP_inletHeaterState "Reports the present state of the inlet heater.";
CM_ SG_ 2042 CP_inletHeaterDuty "Inlet heater PWM duty cycle";
CM_ SG_ 2042 CP_nvm_dataValid "Charge port controller: nvm data valid";
CM_ SG_ 2042 CP_nvm_doorOpenCycles "Charge port controller: nvm door open cycles";
CM_ SG_ 2042 CP_nvm_doorCloseCycles "Charge port controller: nvm door close cycles";
CM_ SG_ 2042 CP_nvm_doorOpen "Charge port controller: nvm door open";
CM_ SG_ 2042 CP_nvm_doorPresent "Charge port controller: nvm door present";
CM_ SG_ 2042 CP_nvm_doorPresentValid "Charge port controller: nvm door present valid";
CM_ SG_ 2042 CP_nvm_badPilotDiodeDetected "Charge port controller: nvm bad pilot diode detected";
CM_ SG_ 2042 CP_nvm_pilotDiodeFaultCount "Charge port controller: nvm pilot diode fault count";
CM_ SG_ 2042 CP_doorOpenLimiterMaxCount "Charge port controller: door open limiter max count";
CM_ SG_ 2042 CP_doorOpenLimiterMaxRequestType "Charge port controller: door open limiter max request type";
CM_ SG_ 2042 CP_doorCloseLimiterMaxCount "Charge port controller: door close limiter max count";
CM_ SG_ 2042 CP_doorCloseLimiterMaxRequestTyp "Charge port controller: door close limiter max request type";
CM_ BO_ 528 "Charge port controller message: status";
CM_ SG_ 528 CP_type "Charge port controller: type";
CM_ SG_ 528 CP_insertEnableLine "Sensed state of the charge port latch drive enable hardline";
CM_ SG_ 528 CP_latchState "Sensed state of the charge port latch; raw 0 = signal not available (SNA)";
CM_ SG_ 528 CP_permanentPowerRequest "Charge port controller: permanent power request";
CM_ SG_ 528 CP_chargeDoorOpen "Indicates whether the charge port door is open based on all door sensors";
CM_ SG_ 528 CP_doorControlState "State of the charge port door controller";
CM_ SG_ 528 CP_doorButtonPressed "Indicates whether the charge door button has been pressed";
CM_ SG_ 528 CP_swcanRelayClosed "Indicates whether the single wire CAN relay is closed";
CM_ SG_ 528 CP_inhibitOta "Reports the charge port's request to prevent scheduled Over-The-Air (OTA) updates during critical charging operations.";
CM_ SG_ 528 CP_chargeCableState "Charge cable connection state; raw 0 = signal not available (SNA)";
CM_ SG_ 528 CP_latchControlState "Control state of the charge port latch";
CM_ SG_ 528 CP_ledColor "Color of the charge port LED";
CM_ SG_ 528 CP_UHF_handleFound "Indicates whether a charge handle has been found with UHF";
CM_ SG_ 528 CP_faultLineSensed "A signal indicating the set / cleared state of the CP-HVP bi-directional fault line, as sensed by the CP";
CM_ SG_ 528 CP_doorPresenceState "State of door as detected by the presence sensor";
CM_ SG_ 528 CP_inductiveSensorState "State of inductive door sensor";
CM_ SG_ 528 CP_chargeDoorOpenUI "Indicates whether the charge port door is open based only on the door poteniometer";
CM_ SG_ 528 CP_vehicleUnlockRequest "Request to unlock the vehicle";
CM_ SG_ 528 CP_coldWeatherMode "Indicates whether the charge port is in cold weather mode";
CM_ SG_ 528 CP_latchEngaged "Charge port controller: latch engaged";
CM_ SG_ 528 CP_inletHeaterUiState "Reports to the User Interface (UI) the state of the inlet heater.";
CM_ BO_ 893 "Charge port controller message: thermal status";
CM_ SG_ 893 CP_thermalStatusSelect "Charge port controller: thermal status select";
CM_ SG_ 893 CP_pinTemperature1 "Sensed temperature of the charge port inlet pins";
CM_ SG_ 893 CP_pinTemperature2 "Sensed temperature of the charge port inlet pins";
CM_ SG_ 893 CP_pinTemperature3 "Sensed temperature of the charge port inlet pins";
CM_ BO_ 583 "Driver assistance computer message: autopilot debug";
CM_ SG_ 583 DAS_roadEstimator "Driver assistance computer: road estimator";
CM_ SG_ 583 DAS_arbiterBehavior "Which behavior task the arbiter has selected and sent to the controller";
CM_ SG_ 583 DAS_mapAvailability "Driver assistance computer: map availability";
CM_ SG_ 583 DAS_controllerRef "Driver assistance computer: controller ref";
CM_ SG_ 583 DAS_alcInternalState "Reports the internal state of the Automatic Lane Change (ALC) machine.";
CM_ SG_ 583 DAS_behaviorReport "Which target source are we controlling for longitudinally.";
CM_ SG_ 583 DAS_constructionZone "Driver assistance computer: construction zone";
CM_ SG_ 583 DAS_controllerHealth "Driver assistance computer: controller health";
CM_ SG_ 583 DAS_controlDistance "Driver assistance computer: control distance";
CM_ SG_ 583 DAS_autopilotAbortReason "Driver assistance computer: autopilot abort reason";
CM_ SG_ 583 DAS_rqstedBehaviorStatus "Indicates the autopilot behavior state with respect to automatic lane change.";
CM_ SG_ 583 DAS_forkState "Reports the internal state of the mission planner fork state machine.";
CM_ SG_ 583 DAS_laneChangeState "Indicates the state of the lane change state machine.";
CM_ SG_ 583 DAS_lastWatchdogCode "Tracks the last APP task to have triggered a Watchdog reset.";
CM_ BO_ 2041 "Driver assistance computer message: gps status";
CM_ SG_ 2041 DAS_gpsStatusMultiplexer "Driver assistance computer: gps status multiplexer";
CM_ SG_ 2041 DAS_gpsTransportModeState "Indicates if the transport mode algorithm detects the car is in transport mode.";
CM_ SG_ 2041 DAS_gpsSatsInUseHardware "The number of GPS satellites currently in use by hardware solution.";
CM_ SG_ 2041 DAS_gpsRejectingSatData "Indicates whether or not the GPS is rejecting satellites due to poor signal.";
CM_ SG_ 2041 DAS_gpsWheelsOffMotionDetected "Indicates that wheels-off acceleration detected";
CM_ SG_ 2041 DAS_gpsFixTypeHardware "The fix type of the GPS receiver, see u-blox M8 spec, section 33.13.1.1";
CM_ SG_ 2041 DAS_gpsRawxEnabled "GPS receiver has raw messages enabled";
CM_ SG_ 2041 DAS_gpsRxmRawxMia "Driver assistance computer: gps rxm rawx mia";
CM_ SG_ 2041 DAS_gpsRxmSfrbxMia "Driver assistance computer: gps rxm sfrbx mia";
CM_ SG_ 2041 DAS_gpsEsfMeasMia "AP is not receiving EsfMeas message from GPS receiver";
CM_ SG_ 2041 DAS_gpsEsfRawMia "AP is not receiving EsfRaw message from GPS receiver";
CM_ SG_ 2041 DAS_gpsNavStatusMia "AP is not receiving NavStatus message from GPS receiver";
CM_ SG_ 2041 DAS_gpsSoftwareConfigured "Software GPS solution is allowed";
CM_ SG_ 2041 DAS_gpsSoftwareUsed "Software GPS solution is actively used";
CM_ SG_ 2041 DAS_gpsSoftwareFastStartReady "Software GPS solution could use fast start mechanism at boot-up";
CM_ SG_ 2041 DAS_gpsSatsInUseSoftware "The number of GPS satellites currently in use by software solution on SOC-A.";
CM_ SG_ 2041 DAS_gpsFixTypeSoftware "The fix type of the GPS software solution on SOC-A.";
CM_ SG_ 2041 DAS_gpsCWJammingInidcator "Level of continuous wave jamming detected by GPS hardware";
CM_ SG_ 2041 DAS_gpsJammingState "State of GPS jamming monitor";
CM_ SG_ 2041 DAS_gpsSpoofDetectorState "Instantaneous state of GPS spoofing detector. Detection only triggers at the transition from real to suspected spoof signal.";
CM_ SG_ 2041 DAS_gpsInvalidMsgPercentage "Percentage of messages received by AP from GPS receiver that were invalid. Calculated over up-to 10s window.";
CM_ SG_ 2041 DAS_gnssConstellationsState "Indicates if GNSS constellations match expected configuration.";
CM_ SG_ 2041 DAS_gpsReceiverNoiseLevel "General noise level of GPS receiver.";
CM_ SG_ 2041 DAS_gpsAutomaticGainControl "Automatic Gain Control of GPS receiver.";
CM_ SG_ 2041 DAS_gpsPreviousPositionDeltaHw "Change in position of two consecutive location outputs from GPS hardware solution.";
CM_ SG_ 2041 DAS_gpsPreviousPositionDeltaSw "Change in position of two consecutive location outputs from GPS software solution.";
CM_ SG_ 2041 DAS_gpsNmeaDispatchFailureCount "Number of GPS messages dropped by AP without sending over to UI. Calculated over up-to 10s window.";
CM_ SG_ 2041 DAS_gnssMaxInstantaneousCnorGps "Maximum carrier-to-noise ratio among all satellites from GPS constellation.";
CM_ SG_ 2041 DAS_gnssMaxInstantaneousCnorGal "Maximum carrier-to-noise ratio among all satellites from GALILEO constellation.";
CM_ SG_ 2041 DAS_gnssMaxInstantaneousCnorBds "Maximum carrier-to-noise ratio among all satellites from BEIDOU constellation.";
CM_ SG_ 2041 DAS_gpsResetReason "When AP resets GPS receiver, this signal indicates the reason why";
CM_ SG_ 2041 DAS_gpsAccuracyHorizontal "Self-reported horizontal GPS accuracy";
CM_ SG_ 2041 DAS_gpsAccuracyVertical "Self-reported vertical GPS accuracy";
CM_ SG_ 2041 DAS_gpsSolutionFallback "GPS solution falling back from software to hardware";
CM_ SG_ 2041 DAS_gpsToMcuSource "This signal exposes which localization solution is being sent to the MCU.";
CM_ SG_ 2041 DAS_gpsSolutionSoc "Reports which System on Chip (SOC) is producing the GPS localization solution.";
CM_ SG_ 2041 DAS_gpsRedundancyActive "Reports whether the GPS Redundancy feature is active on the Autopilot (AP) board. This feature enables either System on Chip (SOC) to publish the Global Navigation Satellite System (GNSS) solution.";
CM_ SG_ 2041 DAS_gpsFixTypeSoftwareSocB "Reports the fix type of the GPS software solution on System on Chip B (SOC-B).";
CM_ SG_ 2041 DAS_gpsSatsInUseSoftwareSocB "Reports the number of GPS satellites currently in use by software solution on System on Chip B (SOC-B).";
CM_ SG_ 2041 DAS_gnssNumSatsGps "Number of satellites visible from GPS constellation.";
CM_ SG_ 2041 DAS_gnssNumSatsGal "Number of satellites visible from GALILEO constellation.";
CM_ SG_ 2041 DAS_gnssNumSatsBds "Number of satellites visible from BEIDOU constellation.";
CM_ SG_ 2041 DAS_gnssAvgInstantaneousCnorGps "Average carrier-to-noise ratio among all satellites from GPS constellation on the high band as reported by the Positioning Engine on SOC-A.";
CM_ SG_ 2041 DAS_gnssAvgInstantaneousCnorGal "Average carrier-to-noise ratio among all satellites from GALILEO constellation on the high band.";
CM_ SG_ 2041 DAS_gnssAvgInstantaneousCnorBds "Average carrier-to-noise ratio among all satellites from BEIDOU constellation on the high band as reported by the Positioning Engine on SOC-A.";
CM_ SG_ 2041 DAS_gnssAvgInstantaneousCnorGpsL "Measures the average carrier-to-noise ratio among all satellites from GPS constellation on the low band as reported by the Positioning Engine on System on Chip A (SOC-A).";
CM_ SG_ 2041 DAS_gnssAvgInstantaneousCnorGalL "Measures the average carrier-to-noise ratio among all satellites from GALILEO constellation on the low band.";
CM_ SG_ 2041 DAS_gnssAvgInstantaneousCnorBdsL "Measures the average carrier-to-noise ratio among all satellites from BEIDOU constellation on the low band as reported by the Positioning Engine on System on Chip A (SOC-A).";
BA_DEF_ "BusType" STRING;
BA_DEF_ "DBName" STRING;
BA_DEF_ "Baudrate" INT 0 1000000;
BA_DEF_ "BaudrateCANFD" INT 0 16000000;
BA_DEF_ "Manufacturer" STRING;
BA_DEF_ "FirmwareVersion" STRING;
BA_DEF_ "VehicleModel" STRING;
BA_DEF_ BU_ "ECU" STRING;
BA_DEF_ BO_ "GenMsgCycleTime" INT 0 3600000;
BA_DEF_ BO_ "GenMsgSendType" ENUM "Cyclic","NotUsed","NotUsed","NotUsed","NotUsed","NotUsed","NotUsed","IfActive","NoMsgSendType","NotUsed";
BA_DEF_ BO_ "VFrameFormat" ENUM "StandardCAN","ExtendedCAN","reserved","J1939PG","reserved","reserved","reserved","reserved","reserved","reserved","reserved","reserved","reserved","reserved","StandardCAN_FD","ExtendedCAN_FD";
BA_DEF_ BO_ "CANFD_BRS" ENUM "0","1";
BA_DEF_ SG_ "GenSigSNA" STRING;
BA_DEF_ SG_ "SystemSignalLongSymbol" STRING;
BA_DEF_ SG_ "Confidence" ENUM "validated","plausible","layout-only","contradicted";
BA_DEF_DEF_ "BusType" "CAN";
BA_DEF_DEF_ "DBName" "";
BA_DEF_DEF_ "Baudrate" 500000;
BA_DEF_DEF_ "BaudrateCANFD" 2000000;
BA_DEF_DEF_ "Manufacturer" "";
BA_DEF_DEF_ "FirmwareVersion" "";
BA_DEF_DEF_ "VehicleModel" "";
BA_DEF_DEF_ "ECU" "";
BA_DEF_DEF_ "GenMsgCycleTime" 0;
BA_DEF_DEF_ "GenMsgSendType" "NoMsgSendType";
BA_DEF_DEF_ "VFrameFormat" "StandardCAN";
BA_DEF_DEF_ "CANFD_BRS" "1";
BA_DEF_DEF_ "GenSigSNA" "";
BA_DEF_DEF_ "SystemSignalLongSymbol" "";
BA_DEF_DEF_ "Confidence" "layout-only";
BA_ "DBName" "Model3_ETH";
BA_ "Manufacturer" "Tesla";
BA_ "FirmwareVersion" "2025.20.8";
BA_ "VehicleModel" "Model 3";
BA_ "ECU" BU_ ADSP "ADSP";
BA_ "ECU" BU_ APB "APB";
BA_ "ECU" BU_ APP "APP";
BA_ "ECU" BU_ APS "APS";
BA_ "ECU" BU_ BB "BB";
BA_ "ECU" BU_ BMS "BMS";
BA_ "ECU" BU_ CC "CC";
BA_ "ECU" BU_ CP "CP";
BA_ "ECU" BU_ DAS "DAS";
BA_ "ECU" BU_ DI "DI";
BA_ "ECU" BU_ DIF "DIF";
BA_ "ECU" BU_ DIR "DIR";
BA_ "ECU" BU_ EPAS3P "EPAS3P";
BA_ "ECU" BU_ EPAS3S "EPAS3S";
BA_ "ECU" BU_ EPBL "EPBL";
BA_ "ECU" BU_ EPBR "EPBR";
BA_ "ECU" BU_ GTW "GTW";
BA_ "ECU" BU_ HVP "HVP";
BA_ "ECU" BU_ ICR "ICR";
BA_ "ECU" BU_ IDB "IDB";
BA_ "ECU" BU_ PCS "PCS";
BA_ "ECU" BU_ PM "PM";
BA_ "ECU" BU_ TCU "TCU";
BA_ "ECU" BU_ UI "UI";
BA_ "ECU" BU_ UIS "UIS";
BA_ "ECU" BU_ VC "VC";
BA_ "ECU" BU_ VCFRONT "VCFRONT";
BA_ "ECU" BU_ VCLEFT "VCLEFT";
BA_ "ECU" BU_ VCRIGHT "VCRIGHT";
BA_ "ECU" BU_ VCSEC "VCSEC";
BA_ "GenMsgCycleTime" BO_ 1383 200;
BA_ "GenMsgSendType" BO_ 1383 0;
BA_ "GenMsgCycleTime" BO_ 600 100;
BA_ "GenMsgSendType" BO_ 600 0;
BA_ "GenMsgCycleTime" BO_ 909 1000;
BA_ "GenMsgSendType" BO_ 909 0;
BA_ "GenMsgCycleTime" BO_ 2046 1000;
BA_ "GenMsgSendType" BO_ 2046 0;
BA_ "GenMsgCycleTime" BO_ 1040 500;
BA_ "GenMsgSendType" BO_ 1040 0;
BA_ "GenMsgCycleTime" BO_ 603 1000;
BA_ "GenMsgSendType" BO_ 603 0;
BA_ "GenMsgCycleTime" BO_ 601 100;
BA_ "GenMsgSendType" BO_ 601 0;
BA_ "GenMsgCycleTime" BO_ 2044 100;
BA_ "GenMsgSendType" BO_ 2044 0;
BA_ "GenMsgCycleTime" BO_ 970 500;
BA_ "GenMsgSendType" BO_ 970 0;
BA_ "GenMsgCycleTime" BO_ 943 10;
BA_ "GenMsgSendType" BO_ 943 0;
BA_ "GenMsgCycleTime" BO_ 1138 1000;
BA_ "GenMsgSendType" BO_ 1138 0;
BA_ "GenMsgCycleTime" BO_ 2029 100;
BA_ "GenMsgSendType" BO_ 2029 0;
BA_ "GenMsgCycleTime" BO_ 306 10;
BA_ "GenMsgSendType" BO_ 306 0;
BA_ "GenMsgCycleTime" BO_ 884 1000;
BA_ "GenMsgSendType" BO_ 884 0;
BA_ "GenMsgCycleTime" BO_ 946 30000;
BA_ "GenMsgSendType" BO_ 946 0;
BA_ "GenMsgCycleTime" BO_ 914 1000;
BA_ "GenMsgSendType" BO_ 914 0;
BA_ "GenMsgCycleTime" BO_ 594 100;
BA_ "GenMsgSendType" BO_ 594 0;
BA_ "GenMsgCycleTime" BO_ 674 100;
BA_ "GenMsgSendType" BO_ 674 0;
BA_ "GenMsgCycleTime" BO_ 658 100;
BA_ "GenMsgSendType" BO_ 658 0;
BA_ "GenMsgCycleTime" BO_ 530 100;
BA_ "GenMsgSendType" BO_ 530 0;
BA_ "GenMsgCycleTime" BO_ 786 1000;
BA_ "GenMsgSendType" BO_ 786 0;
BA_ "GenMsgCycleTime" BO_ 2028 1000;
BA_ "GenMsgSendType" BO_ 2028 0;
BA_ "GenMsgCycleTime" BO_ 754 100;
BA_ "GenMsgSendType" BO_ 754 0;
BA_ "GenMsgCycleTime" BO_ 810 5000;
BA_ "GenMsgSendType" BO_ 810 0;
BA_ "GenMsgCycleTime" BO_ 797 100;
BA_ "GenMsgSendType" BO_ 797 0;
BA_ "GenMsgCycleTime" BO_ 669 100;
BA_ "GenMsgSendType" BO_ 669 0;
BA_ "GenMsgCycleTime" BO_ 541 100;
BA_ "GenMsgSendType" BO_ 541 0;
BA_ "GenMsgCycleTime" BO_ 1885 200;
BA_ "GenMsgSendType" BO_ 1885 0;
BA_ "GenMsgCycleTime" BO_ 2042 1000;
BA_ "GenMsgSendType" BO_ 2042 0;
BA_ "GenMsgCycleTime" BO_ 528 100;
BA_ "GenMsgSendType" BO_ 528 0;
BA_ "GenMsgCycleTime" BO_ 893 1000;
BA_ "GenMsgSendType" BO_ 893 0;
BA_ "GenMsgCycleTime" BO_ 583 100;
BA_ "GenMsgSendType" BO_ 583 0;
BA_ "GenMsgCycleTime" BO_ 2041 1000;
BA_ "GenMsgSendType" BO_ 2041 0;
BA_ "Confidence" SG_ 1383 ADSP_a2baState 0;
BA_ "Confidence" SG_ 1383 ADSP_a2bbState 0;
BA_ "Confidence" SG_ 1383 ADSP_baseamp0State 0;
BA_ "Confidence" SG_ 1383 ADSP_baseamp1State 0;
BA_ "Confidence" SG_ 1383 ADSP_baseamp2State 0;
BA_ "Confidence" SG_ 1383 ADSP_baseamp3State 0;
BA_ "Confidence" SG_ 1383 ADSP_audioReady 0;
BA_ "Confidence" SG_ 1383 ADSP_tcuI2SEnabled 1;
BA_ "Confidence" SG_ 1383 ADSP_ancState 1;
BA_ "Confidence" SG_ 1383 ADSP_telephonyRxMute 0;
BA_ "Confidence" SG_ 1383 ADSP_sourceSelect 1;
BA_ "Confidence" SG_ 1383 ADSP_tunerSelect 1;
BA_ "Confidence" SG_ 1383 ADSP_ancMode 1;
BA_ "Confidence" SG_ 1383 ADSP_spkMuteAll 1;
BA_ "Confidence" SG_ 1383 ADSP_allAudioReady 1;
BA_ "Confidence" SG_ 1383 ADSP_callState 1;
BA_ "Confidence" SG_ 1383 ADSP_telephonyTxMute 1;
BA_ "Confidence" SG_ 1383 ADSP_eCall_ENS_state 0;
BA_ "Confidence" SG_ 1383 ADSP_eCallSelfTest 0;
BA_ "Confidence" SG_ 1383 ADSP_eCallState 0;
BA_ "Confidence" SG_ 1383 ADSP_eCallMicrophoneStatus 1;
BA_ "Confidence" SG_ 1383 ADSP_eCallSpeakerStatus 1;
BA_ "Confidence" SG_ 1383 ADSP_requestFailoverSpeaker 1;
BA_ "Confidence" SG_ 600 APB_watchdogState 0;
BA_ "GenSigSNA" SG_ 600 APB_watchdogState "7";
BA_ "Confidence" SG_ 600 APB_fusedState 0;
BA_ "GenSigSNA" SG_ 600 APB_fusedState "3";
BA_ "Confidence" SG_ 600 APB_cameraHeaterRequest 0;
BA_ "Confidence" SG_ 600 APB_factorySummonStatus 0;
BA_ "GenSigSNA" SG_ 600 APB_factorySummonStatus "0";
BA_ "Confidence" SG_ 600 APB_clipRecordingStatus 0;
BA_ "Confidence" SG_ 600 APB_summonUnavailableReason 0;
BA_ "Confidence" SG_ 600 APB_fsdSuspendState 0;
BA_ "GenSigSNA" SG_ 600 APB_fsdSuspendState "3";
BA_ "Confidence" SG_ 600 APB_fsdRevokeStrikeoutCount 0;
BA_ "GenSigSNA" SG_ 600 APB_fsdRevokeStrikeoutCount "7";
BA_ "Confidence" SG_ 600 APB_teslaVisionSupported 0;
BA_ "GenSigSNA" SG_ 600 APB_teslaVisionSupported "3";
BA_ "Confidence" SG_ 600 APB_teslaVisionUnsupportedReason 0;
BA_ "Confidence" SG_ 600 APB_fsdRevokeCount 0;
BA_ "GenSigSNA" SG_ 600 APB_fsdRevokeCount "7";
BA_ "Confidence" SG_ 600 APB_excessiveAccelPedalWarning 0;
BA_ "Confidence" SG_ 600 APB_unifiedObjectStackSupported 0;
BA_ "GenSigSNA" SG_ 600 APB_unifiedObjectStackSupported "3";
BA_ "Confidence" SG_ 600 APB_DDAWSystemStatus 1;
BA_ "GenSigSNA" SG_ 600 APB_DDAWSystemStatus "4";
BA_ "Confidence" SG_ 600 APB_socOperatingMode 1;
BA_ "Confidence" SG_ 600 APB_summonVersionIdentifier 1;
BA_ "Confidence" SG_ 600 APB_sentryState 0;
BA_ "GenSigSNA" SG_ 600 APB_sentryState "6";
BA_ "Confidence" SG_ 600 APB_autoparkVersionIdentifier 0;
BA_ "Confidence" SG_ 600 APB_suspendResumeAvailable 0;
BA_ "Confidence" SG_ 600 APB_statusCounter 0;
BA_ "Confidence" SG_ 600 APB_statusChecksum 0;
BA_ "Confidence" SG_ 909 APP_inTunnel 0;
BA_ "GenSigSNA" SG_ 909 APP_inTunnel "0";
BA_ "Confidence" SG_ 909 APP_windshieldHeaterOnReason 1;
BA_ "GenSigSNA" SG_ 909 APP_windshieldHeaterOnReason "0";
BA_ "Confidence" SG_ 909 APP_selfieCameraBlocked 0;
BA_ "GenSigSNA" SG_ 909 APP_selfieCameraBlocked "0";
BA_ "Confidence" SG_ 909 APP_selfieCameraLUX 0;
BA_ "GenSigSNA" SG_ 909 APP_selfieCameraLUX "255";
BA_ "Confidence" SG_ 909 APP_sceneTagClearlyRaining 0;
BA_ "GenSigSNA" SG_ 909 APP_sceneTagClearlyRaining "0";
BA_ "Confidence" SG_ 909 APP_sceneTagFog 0;
BA_ "GenSigSNA" SG_ 909 APP_sceneTagFog "0";
BA_ "Confidence" SG_ 909 APP_sceneTagFullyBlocked 0;
BA_ "GenSigSNA" SG_ 909 APP_sceneTagFullyBlocked "0";
BA_ "Confidence" SG_ 909 APP_sceneTagIndoors 0;
BA_ "GenSigSNA" SG_ 909 APP_sceneTagIndoors "0";
BA_ "Confidence" SG_ 909 APP_sceneTagLensFlare 0;
BA_ "GenSigSNA" SG_ 909 APP_sceneTagLensFlare "0";
BA_ "Confidence" SG_ 909 APP_sceneTagRaining 0;
BA_ "GenSigSNA" SG_ 909 APP_sceneTagRaining "0";
BA_ "Confidence" SG_ 909 APP_sceneTagSevereWeather 0;
BA_ "GenSigSNA" SG_ 909 APP_sceneTagSevereWeather "0";
BA_ "Confidence" SG_ 909 APP_sceneTagSnowing 0;
BA_ "GenSigSNA" SG_ 909 APP_sceneTagSnowing "0";
BA_ "Confidence" SG_ 909 APP_sceneTagSnowyRoad 0;
BA_ "GenSigSNA" SG_ 909 APP_sceneTagSnowyRoad "0";
BA_ "Confidence" SG_ 909 APP_sceneTagSunGlare 0;
BA_ "GenSigSNA" SG_ 909 APP_sceneTagSunGlare "0";
BA_ "Confidence" SG_ 909 APP_sceneTagTunnel 0;
BA_ "GenSigSNA" SG_ 909 APP_sceneTagTunnel "0";
BA_ "Confidence" SG_ 909 APP_sceneTagWetRoad 0;
BA_ "GenSigSNA" SG_ 909 APP_sceneTagWetRoad "0";
BA_ "Confidence" SG_ 909 APP_fisheyeInPathVisibility 0;
BA_ "GenSigSNA" SG_ 909 APP_fisheyeInPathVisibility "0";
BA_ "Confidence" SG_ 909 APP_fisheyeOverallVisibility 0;
BA_ "GenSigSNA" SG_ 909 APP_fisheyeOverallVisibility "0";
BA_ "Confidence" SG_ 909 APP_mainInPathVisibility 0;
BA_ "GenSigSNA" SG_ 909 APP_mainInPathVisibility "0";
BA_ "Confidence" SG_ 909 APP_mainOverallVisibility 0;
BA_ "GenSigSNA" SG_ 909 APP_mainOverallVisibility "0";
BA_ "Confidence" SG_ 909 APP_narrowInPathVisibility 0;
BA_ "GenSigSNA" SG_ 909 APP_narrowInPathVisibility "0";
BA_ "Confidence" SG_ 909 APP_narrowOverallVisibility 0;
BA_ "GenSigSNA" SG_ 909 APP_narrowOverallVisibility "0";
BA_ "Confidence" SG_ 909 APP_frontCamOcclusionType 0;
BA_ "Confidence" SG_ 2046 APP_cameraPosition 1;
BA_ "Confidence" SG_ 2046 APP_mainCamExtPitchCal 0;
BA_ "GenSigSNA" SG_ 2046 APP_mainCamExtPitchCal "511";
BA_ "Confidence" SG_ 2046 APP_mainCamExtYawCal 0;
BA_ "GenSigSNA" SG_ 2046 APP_mainCamExtYawCal "511";
BA_ "Confidence" SG_ 2046 APP_mainCalibTime 0;
BA_ "GenSigSNA" SG_ 2046 APP_mainCalibTime "127";
BA_ "Confidence" SG_ 2046 APP_mainCalibProgress 0;
BA_ "GenSigSNA" SG_ 2046 APP_mainCalibProgress "127";
BA_ "Confidence" SG_ 2046 APP_mainCalibrated 0;
BA_ "Confidence" SG_ 2046 APP_narrowCamExtPitchCal 0;
BA_ "GenSigSNA" SG_ 2046 APP_narrowCamExtPitchCal "511";
BA_ "Confidence" SG_ 2046 APP_narrowCamExtYawCal 0;
BA_ "GenSigSNA" SG_ 2046 APP_narrowCamExtYawCal "511";
BA_ "Confidence" SG_ 2046 APP_narrowCalibTime 0;
BA_ "GenSigSNA" SG_ 2046 APP_narrowCalibTime "127";
BA_ "Confidence" SG_ 2046 APP_narrowCalibProgress 0;
BA_ "GenSigSNA" SG_ 2046 APP_narrowCalibProgress "127";
BA_ "Confidence" SG_ 2046 APP_narrowCalibrated 0;
BA_ "Confidence" SG_ 2046 APP_fisheyeCamExtPitchCal 0;
BA_ "GenSigSNA" SG_ 2046 APP_fisheyeCamExtPitchCal "511";
BA_ "Confidence" SG_ 2046 APP_fisheyeCamExtYawCal 0;
BA_ "GenSigSNA" SG_ 2046 APP_fisheyeCamExtYawCal "511";
BA_ "Confidence" SG_ 2046 APP_fisheyeCalibTime 0;
BA_ "GenSigSNA" SG_ 2046 APP_fisheyeCalibTime "127";
BA_ "Confidence" SG_ 2046 APP_fisheyeCalibProgress 0;
BA_ "GenSigSNA" SG_ 2046 APP_fisheyeCalibProgress "127";
BA_ "Confidence" SG_ 2046 APP_fisheyeCalibrated 0;
BA_ "Confidence" SG_ 2046 APP_lPillarCamExtPitchCal 0;
BA_ "GenSigSNA" SG_ 2046 APP_lPillarCamExtPitchCal "511";
BA_ "Confidence" SG_ 2046 APP_lPillarCamExtYawCal 0;
BA_ "GenSigSNA" SG_ 2046 APP_lPillarCamExtYawCal "511";
BA_ "Confidence" SG_ 2046 APP_lPillarCalibTime 0;
BA_ "GenSigSNA" SG_ 2046 APP_lPillarCalibTime "127";
BA_ "Confidence" SG_ 2046 APP_lPillarCalibProgress 0;
BA_ "GenSigSNA" SG_ 2046 APP_lPillarCalibProgress "127";
BA_ "Confidence" SG_ 2046 APP_lPillarCalibrated 0;
BA_ "Confidence" SG_ 2046 APP_rPillarCamExtPitchCal 0;
BA_ "GenSigSNA" SG_ 2046 APP_rPillarCamExtPitchCal "511";
BA_ "Confidence" SG_ 2046 APP_rPillarCamExtYawCal 0;
BA_ "GenSigSNA" SG_ 2046 APP_rPillarCamExtYawCal "511";
BA_ "Confidence" SG_ 2046 APP_rPillarCalibTime 0;
BA_ "GenSigSNA" SG_ 2046 APP_rPillarCalibTime "127";
BA_ "Confidence" SG_ 2046 APP_rPillarCalibProgress 0;
BA_ "GenSigSNA" SG_ 2046 APP_rPillarCalibProgress "127";
BA_ "Confidence" SG_ 2046 APP_rPillarCalibrated 0;
BA_ "Confidence" SG_ 2046 APP_lRepeatCamExtPitchCal 0;
BA_ "GenSigSNA" SG_ 2046 APP_lRepeatCamExtPitchCal "511";
BA_ "Confidence" SG_ 2046 APP_lRepeatCamExtYawCal 0;
BA_ "GenSigSNA" SG_ 2046 APP_lRepeatCamExtYawCal "511";
BA_ "Confidence" SG_ 2046 APP_lRepeatCalibTime 0;
BA_ "GenSigSNA" SG_ 2046 APP_lRepeatCalibTime "127";
BA_ "Confidence" SG_ 2046 APP_lRepeatCalibProgress 0;
BA_ "GenSigSNA" SG_ 2046 APP_lRepeatCalibProgress "127";
BA_ "Confidence" SG_ 2046 APP_lRepeatCalibrated 0;
BA_ "Confidence" SG_ 2046 APP_rRepeatCamExtPitchCal 0;
BA_ "GenSigSNA" SG_ 2046 APP_rRepeatCamExtPitchCal "511";
BA_ "Confidence" SG_ 2046 APP_rRepeatCamExtYawCal 0;
BA_ "GenSigSNA" SG_ 2046 APP_rRepeatCamExtYawCal "511";
BA_ "Confidence" SG_ 2046 APP_rRepeatCalibTime 0;
BA_ "GenSigSNA" SG_ 2046 APP_rRepeatCalibTime "127";
BA_ "Confidence" SG_ 2046 APP_rRepeatCalibProgress 0;
BA_ "GenSigSNA" SG_ 2046 APP_rRepeatCalibProgress "127";
BA_ "Confidence" SG_ 2046 APP_rRepeatCalibrated 0;
BA_ "Confidence" SG_ 2046 APP_backupCamExtPitchCal 0;
BA_ "GenSigSNA" SG_ 2046 APP_backupCamExtPitchCal "511";
BA_ "Confidence" SG_ 2046 APP_backupCamExtYawCal 0;
BA_ "GenSigSNA" SG_ 2046 APP_backupCamExtYawCal "511";
BA_ "Confidence" SG_ 2046 APP_backupCalibTime 0;
BA_ "GenSigSNA" SG_ 2046 APP_backupCalibTime "127";
BA_ "Confidence" SG_ 2046 APP_backupCalibProgress 0;
BA_ "GenSigSNA" SG_ 2046 APP_backupCalibProgress "127";
BA_ "Confidence" SG_ 2046 APP_backupCalibrated 0;
BA_ "Confidence" SG_ 1040 APP_backupCameraFeedGood 0;
BA_ "Confidence" SG_ 1040 APP_backupCameraFrameRate 0;
BA_ "Confidence" SG_ 1040 APP_cameraBlockedFrontMain 0;
BA_ "Confidence" SG_ 1040 APP_cameraBlockedFrontFisheye 0;
BA_ "Confidence" SG_ 1040 APP_cameraBlockedFrontNarrow 0;
BA_ "Confidence" SG_ 1040 APP_cameraBlockedLeftPillar 0;
BA_ "Confidence" SG_ 1040 APP_cameraBlockedLeftRepeater 0;
BA_ "Confidence" SG_ 1040 APP_cameraBlockedRightPillar 0;
BA_ "Confidence" SG_ 1040 APP_cameraBlockedRightRepeater 0;
BA_ "Confidence" SG_ 1040 APP_cameraBlockedBackup 0;
BA_ "Confidence" SG_ 603 APP_environmentRainy 0;
BA_ "Confidence" SG_ 603 APP_environmentSnowy 0;
BA_ "Confidence" SG_ 601 APP_watchdogState 0;
BA_ "GenSigSNA" SG_ 601 APP_watchdogState "7";
BA_ "Confidence" SG_ 601 APP_fusedState 0;
BA_ "GenSigSNA" SG_ 601 APP_fusedState "3";
BA_ "Confidence" SG_ 601 APP_cameraHeaterRequest 0;
BA_ "Confidence" SG_ 601 APP_factorySummonStatus 0;
BA_ "GenSigSNA" SG_ 601 APP_factorySummonStatus "0";
BA_ "Confidence" SG_ 601 APP_clipRecordingStatus 0;
BA_ "Confidence" SG_ 601 APP_allowApActivationWithBrake 0;
BA_ "Confidence" SG_ 601 APP_summonUnavailableReason 0;
BA_ "Confidence" SG_ 601 APP_fsdSuspendState 0;
BA_ "GenSigSNA" SG_ 601 APP_fsdSuspendState "3";
BA_ "Confidence" SG_ 601 APP_fsdRevokeStrikeoutCount 0;
BA_ "GenSigSNA" SG_ 601 APP_fsdRevokeStrikeoutCount "7";
BA_ "Confidence" SG_ 601 APP_teslaVisionSupported 0;
BA_ "GenSigSNA" SG_ 601 APP_teslaVisionSupported "3";
BA_ "Confidence" SG_ 601 APP_teslaVisionUnsupportedReason 0;
BA_ "Confidence" SG_ 601 APP_fsdRevokeCount 0;
BA_ "GenSigSNA" SG_ 601 APP_fsdRevokeCount "7";
BA_ "Confidence" SG_ 601 APP_excessiveAccelPedalWarning 0;
BA_ "Confidence" SG_ 601 APP_unifiedObjectStackSupported 0;
BA_ "GenSigSNA" SG_ 601 APP_unifiedObjectStackSupported "3";
BA_ "Confidence" SG_ 601 APP_DDAWSystemStatus 1;
BA_ "GenSigSNA" SG_ 601 APP_DDAWSystemStatus "4";
BA_ "Confidence" SG_ 601 APP_socOperatingMode 1;
BA_ "Confidence" SG_ 601 APP_summonVersionIdentifier 1;
BA_ "Confidence" SG_ 601 APP_sentryState 0;
BA_ "GenSigSNA" SG_ 601 APP_sentryState "6";
BA_ "Confidence" SG_ 601 APP_autoparkVersionIdentifier 0;
BA_ "Confidence" SG_ 601 APP_suspendResumeAvailable 0;
BA_ "Confidence" SG_ 601 APP_statusCounter 0;
BA_ "Confidence" SG_ 601 APP_statusChecksum 0;
BA_ "Confidence" SG_ 2044 APS_primaryTurbo 0;
BA_ "Confidence" SG_ 2044 APS_A_arbState 0;
BA_ "Confidence" SG_ 2044 APS_A_powerState 0;
BA_ "Confidence" SG_ 2044 APS_A_sleepState 0;
BA_ "Confidence" SG_ 2044 APS_A_resetState 0;
BA_ "Confidence" SG_ 2044 APS_A_faultState 0;
BA_ "Confidence" SG_ 2044 APS_secondaryTurbo 0;
BA_ "Confidence" SG_ 2044 APS_B_arbState 0;
BA_ "Confidence" SG_ 2044 APS_B_powerState 0;
BA_ "Confidence" SG_ 2044 APS_B_sleepState 0;
BA_ "Confidence" SG_ 2044 APS_B_resetState 0;
BA_ "Confidence" SG_ 2044 APS_B_faultState 0;
BA_ "Confidence" SG_ 970 APS_appStatusMonitorState 0;
BA_ "Confidence" SG_ 970 APS_vehBehaviorState 0;
BA_ "Confidence" SG_ 970 APS_canMaster 0;
BA_ "GenSigSNA" SG_ 970 APS_canMaster "3";
BA_ "Confidence" SG_ 970 APS_appGpioState 0;
BA_ "Confidence" SG_ 970 APS_eacInternalState 0;
BA_ "Confidence" SG_ 970 APS_switchState 0;
BA_ "Confidence" SG_ 970 APS_apbStatusMonitorState 0;
BA_ "Confidence" SG_ 970 APS_apbGpioState 0;
BA_ "Confidence" SG_ 970 APS_statusCounter 0;
BA_ "Confidence" SG_ 970 APS_locLimitReason 0;
BA_ "Confidence" SG_ 970 APS_appPowerStateRequest 0;
BA_ "Confidence" SG_ 970 APS_appPowerStateReason 0;
BA_ "Confidence" SG_ 970 APS_apbPowerStateRequest 1;
BA_ "Confidence" SG_ 970 APS_apbPowerStateReason 1;
BA_ "Confidence" SG_ 970 APS_heaterStateDebug 1;
BA_ "GenSigSNA" SG_ 970 APS_heaterStateDebug "7";
BA_ "Confidence" SG_ 970 APS_gpsAntennaState 1;
BA_ "Confidence" SG_ 970 APS_arbState 1;
BA_ "Confidence" SG_ 970 APS_socPowerOperatingMode 1;
BA_ "Confidence" SG_ 970 APS_otherArbState 1;
BA_ "Confidence" SG_ 943 BB_statusChecksum 0;
BA_ "Confidence" SG_ 943 BB_statusCounter 0;
BA_ "Confidence" SG_ 943 BB_sOutputRod 0;
BA_ "Confidence" SG_ 943 BB_sOutputRodQF 0;
BA_ "Confidence" SG_ 943 BB_sInputRod 0;
BA_ "Confidence" SG_ 943 BB_sInputRodQF 0;
BA_ "Confidence" SG_ 943 BB_driverBrakeApply 0;
BA_ "Confidence" SG_ 943 BB_driverBrakeApplyQF 0;
BA_ "Confidence" SG_ 943 BB_boosterStatus 0;
BA_ "Confidence" SG_ 943 BB_warningLampRequest 0;
BA_ "Confidence" SG_ 943 BB_brakeFluidLevel 0;
BA_ "Confidence" SG_ 943 BB_internalState 0;
BA_ "Confidence" SG_ 1138 BMS_cellChargeDcCurrentLimit 1;
BA_ "Confidence" SG_ 1138 BMS_voltageRegCurrentTarget 1;
BA_ "Confidence" SG_ 1138 BMS_vehicleChargeDcCurrentLimit 1;
BA_ "Confidence" SG_ 1138 BMS_chargeCurrentLimitMode 1;
BA_ "Confidence" SG_ 1138 BMS_timeToFinishHeatForCharge 1;
BA_ "GenSigSNA" SG_ 1138 BMS_timeToFinishHeatForCharge "127";
BA_ "Confidence" SG_ 1138 BMS_diNodeModelTemp 1;
BA_ "GenSigSNA" SG_ 1138 BMS_diNodeModelTemp "2047";
BA_ "Confidence" SG_ 2029 BMS_10HzDebug_Id 1;
BA_ "Confidence" SG_ 2029 BMS_activeCoolCellTargetT 1;
BA_ "Confidence" SG_ 2029 BMS_passiveCoolCellTargetT 1;
BA_ "Confidence" SG_ 306 BMS_packVoltage 1;
BA_ "Confidence" SG_ 306 BMS_packCurrent 0;
BA_ "GenSigSNA" SG_ 306 BMS_packCurrent "32768";
BA_ "Confidence" SG_ 306 BMS_currentUnfiltered 0;
BA_ "GenSigSNA" SG_ 306 BMS_currentUnfiltered "32768";
BA_ "Confidence" SG_ 306 BMS_chgTimeToFull 1;
BA_ "GenSigSNA" SG_ 306 BMS_chgTimeToFull "4095";
BA_ "Confidence" SG_ 884 BMS_log1MuxId 1;
BA_ "Confidence" SG_ 884 BMS_extDcPrechargeVoltageLimit 0;
BA_ "Confidence" SG_ 884 BMS_dcChargeCurrentRequest 0;
BA_ "Confidence" SG_ 884 BMS_dcChargeCurrentLimit 0;
BA_ "Confidence" SG_ 884 BMS_dcDischargeEnabled 0;
BA_ "Confidence" SG_ 884 BMS_rippleChargeRetryCount 0;
BA_ "Confidence" SG_ 884 BMS_dcChargeVoltageLimit 0;
BA_ "Confidence" SG_ 884 BMS_dcChargePowerLimit 0;
BA_ "Confidence" SG_ 884 BMS_maxExtIsoFcLinkV 0;
BA_ "Confidence" SG_ 884 BMS_socByDeltaVEnabled 0;
BA_ "Confidence" SG_ 884 BMS_socByDvMaxSocLimit 0;
BA_ "Confidence" SG_ 884 BMS_socByDvVoltageChangeOverAh 0;
BA_ "Confidence" SG_ 884 BMS_socByDvMaxSocByAhCorrected 0;
BA_ "Confidence" SG_ 884 BMS_socByDvMaxBrickVoltage 0;
BA_ "Confidence" SG_ 884 BMS_socByDvMaxBrickId 0;
BA_ "Confidence" SG_ 946 BMS_log2MuxId 1;
BA_ "Confidence" SG_ 946 BMS_cacAvg 0;
BA_ "Confidence" SG_ 946 BMS_cacMin 0;
BA_ "Confidence" SG_ 946 BMS_cacMinBrickId 0;
BA_ "Confidence" SG_ 946 BMS_cacMax 0;
BA_ "Confidence" SG_ 946 BMS_cacMaxBrickId 0;
BA_ "Confidence" SG_ 946 BMS_acRippleConfigNvramValid 0;
BA_ "Confidence" SG_ 946 BMS_hvChain_useLeakyBucket 0;
BA_ "Confidence" SG_ 946 BMS_hvChain_iLimit 0;
BA_ "GenSigSNA" SG_ 946 BMS_hvChain_iLimit "16383";
BA_ "Confidence" SG_ 946 BMS_hvChain_limitingState 0;
BA_ "GenSigSNA" SG_ 946 BMS_hvChain_limitingState "511";
BA_ "Confidence" SG_ 946 BMS_hvChain_limitingStateTempera 0;
BA_ "GenSigSNA" SG_ 946 BMS_hvChain_limitingStateTempera "4096";
BA_ "SystemSignalLongSymbol" SG_ 946 BMS_hvChain_limitingStateTempera "BMS_hvChain_limitingStateTemperature";
BA_ "Confidence" SG_ 946 BMS_acRippleIsSupported 0;
BA_ "Confidence" SG_ 946 BMS_acRippleStartTemperatureMax 0;
BA_ "Confidence" SG_ 946 BMS_acRippleStartTemperatureMin 0;
BA_ "Confidence" SG_ 946 BMS_fcLinkTestDecayTime 0;
BA_ "GenSigSNA" SG_ 946 BMS_fcLinkTestDecayTime "1023";
BA_ "Confidence" SG_ 946 BMS_fcLinkTestTimeSinceLastRun 0;
BA_ "Confidence" SG_ 946 BMS_pcsPrechargeTargetVoltage 0;
BA_ "Confidence" SG_ 946 BMS_recentOvUvAlert 0;
BA_ "Confidence" SG_ 946 BMS_recentIsoAlert 0;
BA_ "Confidence" SG_ 946 BMS_recentBmbMiaAlert 0;
BA_ "Confidence" SG_ 946 BMS_cacBlendingConfigNvramValid 0;
BA_ "Confidence" SG_ 946 BMS_cacBlendingEnabled 0;
BA_ "Confidence" SG_ 946 BMS_cacBlendPercentPerCycle 0;
BA_ "Confidence" SG_ 946 BMS_energyVariableChgRequested 0;
BA_ "Confidence" SG_ 946 BMS_packRestTime 0;
BA_ "Confidence" SG_ 946 BMS_idealEnergyFloor 0;
BA_ "GenSigSNA" SG_ 946 BMS_idealEnergyFloor "1023";
BA_ "Confidence" SG_ 946 BMS_thmGradientSlopeCondition 0;
BA_ "Confidence" SG_ 946 BMS_recentSlopeConditon 0;
BA_ "Confidence" SG_ 946 BMS_dynamicEnergyBuffer 0;
BA_ "GenSigSNA" SG_ 946 BMS_dynamicEnergyBuffer "1023";
BA_ "Confidence" SG_ 946 BMS_temperatureCondition 0;
BA_ "Confidence" SG_ 946 BMS_thmGradientSlope 0;
BA_ "Confidence" SG_ 946 BMS_thmGradient 0;
BA_ "Confidence" SG_ 946 BMS_dSocNormalizedMin 0;
BA_ "GenSigSNA" SG_ 946 BMS_dSocNormalizedMin "4095";
BA_ "Confidence" SG_ 946 BMS_dSocNormalizedFiltMin 0;
BA_ "GenSigSNA" SG_ 946 BMS_dSocNormalizedFiltMin "4095";
BA_ "Confidence" SG_ 946 BMS_dSocMinAlpha 0;
BA_ "GenSigSNA" SG_ 946 BMS_dSocMinAlpha "4095";
BA_ "Confidence" SG_ 946 BMS_dSocMaxLowAlphaCounter 0;
BA_ "Confidence" SG_ 946 BMS_dSocMinAlphaBrickID 0;
BA_ "Confidence" SG_ 946 BMS_dSocCacMargin 0;
BA_ "GenSigSNA" SG_ 946 BMS_dSocCacMargin "511";
BA_ "Confidence" SG_ 946 BMS_lifeModelAvgTempSeverity 0;
BA_ "GenSigSNA" SG_ 946 BMS_lifeModelAvgTempSeverity "31";
BA_ "Confidence" SG_ 946 BMS_lifeModelDepthOfDischargeSev 0;
BA_ "GenSigSNA" SG_ 946 BMS_lifeModelDepthOfDischargeSev "255";
BA_ "SystemSignalLongSymbol" SG_ 946 BMS_lifeModelDepthOfDischargeSev "BMS_lifeModelDepthOfDischargeSeverity";
BA_ "Confidence" SG_ 946 BMS_lifeModelHistogramCapacityLo 0;
BA_ "GenSigSNA" SG_ 946 BMS_lifeModelHistogramCapacityLo "511";
BA_ "SystemSignalLongSymbol" SG_ 946 BMS_lifeModelHistogramCapacityLo "BMS_lifeModelHistogramCapacityLoss";
BA_ "Confidence" SG_ 946 BMS_lifeModelHistogramBrickCapac 0;
BA_ "GenSigSNA" SG_ 946 BMS_lifeModelHistogramBrickCapac "8191";
BA_ "SystemSignalLongSymbol" SG_ 946 BMS_lifeModelHistogramBrickCapac "BMS_lifeModelHistogramBrickCapacity";
BA_ "Confidence" SG_ 946 BMS_lifeModelDcrGrowthPercent 0;
BA_ "GenSigSNA" SG_ 946 BMS_lifeModelDcrGrowthPercent "8192";
BA_ "Confidence" SG_ 946 BMS_nominalFullPackEnergyRaw 0;
BA_ "GenSigSNA" SG_ 946 BMS_nominalFullPackEnergyRaw "65535";
BA_ "Confidence" SG_ 946 BMS_userChargeCalibratingReason 1;
BA_ "Confidence" SG_ 946 BMS_nominalEnergyRemainingBuffer 1;
BA_ "GenSigSNA" SG_ 946 BMS_nominalEnergyRemainingBuffer "65535";
BA_ "SystemSignalLongSymbol" SG_ 946 BMS_nominalEnergyRemainingBuffer "BMS_nominalEnergyRemainingBuffered";
BA_ "Confidence" SG_ 946 BMS_idealEnergyRemainingBuffered 1;
BA_ "GenSigSNA" SG_ 946 BMS_idealEnergyRemainingBuffered "65535";
BA_ "Confidence" SG_ 946 BMS_largestCacSpreadErrorLower 0;
BA_ "GenSigSNA" SG_ 946 BMS_largestCacSpreadErrorLower "4095";
BA_ "Confidence" SG_ 946 BMS_lifeModelAverageCac 0;
BA_ "GenSigSNA" SG_ 946 BMS_lifeModelAverageCac "4095";
BA_ "Confidence" SG_ 946 BMS_lifeModelCacBrick1 0;
BA_ "GenSigSNA" SG_ 946 BMS_lifeModelCacBrick1 "4095";
BA_ "Confidence" SG_ 946 BMS_lifeModelAverageOffset 0;
BA_ "GenSigSNA" SG_ 946 BMS_lifeModelAverageOffset "512";
BA_ "Confidence" SG_ 946 BMS_percentCacUpdatesInTimeWindo 0;
BA_ "SystemSignalLongSymbol" SG_ 946 BMS_percentCacUpdatesInTimeWindo "BMS_percentCacUpdatesInTimeWindow";
BA_ "Confidence" SG_ 946 BMS_lifeModelMaxCacBrickId 0;
BA_ "GenSigSNA" SG_ 946 BMS_lifeModelMaxCacBrickId "255";
BA_ "Confidence" SG_ 946 BMS_lifeModelMaxCac 0;
BA_ "GenSigSNA" SG_ 946 BMS_lifeModelMaxCac "4095";
BA_ "Confidence" SG_ 946 BMS_lifeModelMinCacBrickId 0;
BA_ "GenSigSNA" SG_ 946 BMS_lifeModelMinCacBrickId "255";
BA_ "Confidence" SG_ 946 BMS_lifeModelMinCac 0;
BA_ "GenSigSNA" SG_ 946 BMS_lifeModelMinCac "4095";
BA_ "Confidence" SG_ 946 BMS_restingPointCacAvg 0;
BA_ "GenSigSNA" SG_ 946 BMS_restingPointCacAvg "4095";
BA_ "Confidence" SG_ 946 BMS_cacEstimationSource 0;
BA_ "Confidence" SG_ 946 BMS_synchronizedCacMaxRaw 0;
BA_ "GenSigSNA" SG_ 946 BMS_synchronizedCacMaxRaw "4095";
BA_ "Confidence" SG_ 946 BMS_synchronizedCacMinRaw 0;
BA_ "GenSigSNA" SG_ 946 BMS_synchronizedCacMinRaw "4095";
BA_ "Confidence" SG_ 946 BMS_largestSyncCacErrorStartSoc 0;
BA_ "Confidence" SG_ 946 BMS_largestSyncCacErrorEndSoc 0;
BA_ "Confidence" SG_ 946 BMS_runtimeSocConfigNvramValid 0;
BA_ "Confidence" SG_ 946 BMS_runtimeSocCorrectionsEnabled 0;
BA_ "Confidence" SG_ 946 BMS_rubberBandingEnabled 0;
BA_ "Confidence" SG_ 946 BMS_rubberBandingConfigNvramVali 0;
BA_ "SystemSignalLongSymbol" SG_ 946 BMS_rubberBandingConfigNvramVali "BMS_rubberBandingConfigNvramValid";
BA_ "Confidence" SG_ 946 BMS_runtimeSocMinTempForModel 0;
BA_ "Confidence" SG_ 946 BMS_energyBufferConfigNvramValid 0;
BA_ "Confidence" SG_ 946 BMS_thermalEvent1pDetectConfigDi 0;
BA_ "SystemSignalLongSymbol" SG_ 946 BMS_thermalEvent1pDetectConfigDi "BMS_thermalEvent1pDetectConfigDisabled";
BA_ "Confidence" SG_ 946 BMS_sohEnergy 0;
BA_ "GenSigSNA" SG_ 946 BMS_sohEnergy "2047";
BA_ "Confidence" SG_ 946 BMS_fullCapacitySohEnergy 0;
BA_ "GenSigSNA" SG_ 946 BMS_fullCapacitySohEnergy "2047";
BA_ "Confidence" SG_ 946 BMS_calibratedCapacitySohEnergy 0;
BA_ "GenSigSNA" SG_ 946 BMS_calibratedCapacitySohEnergy "2047";
BA_ "Confidence" SG_ 946 BMS_estimatedCapacitySohEnergy 0;
BA_ "GenSigSNA" SG_ 946 BMS_estimatedCapacitySohEnergy "2047";
BA_ "Confidence" SG_ 946 BMS_prevUserFacingSohEnergy 0;
BA_ "GenSigSNA" SG_ 946 BMS_prevUserFacingSohEnergy "2047";
BA_ "Confidence" SG_ 946 BMS_stateOfHealthMinCac 0;
BA_ "GenSigSNA" SG_ 946 BMS_stateOfHealthMinCac "8191";
BA_ "Confidence" SG_ 946 BMS_lifeModelStorageLossPackAge 0;
BA_ "GenSigSNA" SG_ 946 BMS_lifeModelStorageLossPackAge "16383";
BA_ "Confidence" SG_ 946 BMS_lifeModelThroughputCycleCoun 1;
BA_ "GenSigSNA" SG_ 946 BMS_lifeModelThroughputCycleCoun "4095";
BA_ "SystemSignalLongSymbol" SG_ 946 BMS_lifeModelThroughputCycleCoun "BMS_lifeModelThroughputCycleCount";
BA_ "Confidence" SG_ 946 BMS_lifeModelThroughputDcrCycleC 1;
BA_ "GenSigSNA" SG_ 946 BMS_lifeModelThroughputDcrCycleC "4095";
BA_ "SystemSignalLongSymbol" SG_ 946 BMS_lifeModelThroughputDcrCycleC "BMS_lifeModelThroughputDcrCycleCount";
BA_ "Confidence" SG_ 946 BMS_energyWalkCounter 0;
BA_ "Confidence" SG_ 946 BMS_energyWalkTimeoutCounter 0;
BA_ "Confidence" SG_ 946 BMS_dynamicCcvEnabled 0;
BA_ "Confidence" SG_ 946 BMS_chargeTargetLookupSoc 1;
BA_ "Confidence" SG_ 946 BMS_stateOfHealth 1;
BA_ "GenSigSNA" SG_ 946 BMS_stateOfHealth "1023";
BA_ "Confidence" SG_ 914 BMS_packConfigMultiplexer 1;
BA_ "Confidence" SG_ 914 BMS_reservedConfig_0 1;
BA_ "Confidence" SG_ 914 BMS_moduleType 0;
BA_ "Confidence" SG_ 914 BMS_thermalPackType 0;
BA_ "Confidence" SG_ 914 BMS_packMass 0;
BA_ "Confidence" SG_ 914 BMS_platformMaxBusVoltage 0;
BA_ "Confidence" SG_ 914 BMS_standbySupplyContinuousPower 0;
BA_ "SystemSignalLongSymbol" SG_ 914 BMS_standbySupplyContinuousPower "BMS_standbySupplyContinuousPowerLimit";
BA_ "Confidence" SG_ 594 BMS_maxRegenPower 0;
BA_ "Confidence" SG_ 594 BMS_maxDischargePower 0;
BA_ "Confidence" SG_ 594 BMS_maxStationaryHeatPower 0;
BA_ "Confidence" SG_ 594 BMS_powerLimitsState 0;
BA_ "Confidence" SG_ 594 BMS_notEnoughPowerForHeatPump 1;
BA_ "Confidence" SG_ 594 BMS_instantChargePowerCapability 0;
BA_ "GenSigSNA" SG_ 594 BMS_instantChargePowerCapability "65535";
BA_ "Confidence" SG_ 674 BMS_acRippleCurrentAmplitudeLimi 1;
BA_ "SystemSignalLongSymbol" SG_ 674 BMS_acRippleCurrentAmplitudeLimi "BMS_acRippleCurrentAmplitudeLimit";
BA_ "Confidence" SG_ 674 BMS_acRippleMaxVoltageLimit 1;
BA_ "Confidence" SG_ 674 BMS_acRippleMinVoltageLimit 1;
BA_ "Confidence" SG_ 674 BMS_acRippleFrequencyRequest 1;
BA_ "GenSigSNA" SG_ 674 BMS_acRippleFrequencyRequest "63";
BA_ "Confidence" SG_ 674 BMS_acRippleCurrentAmplitudeRequ 1;
BA_ "SystemSignalLongSymbol" SG_ 674 BMS_acRippleCurrentAmplitudeRequ "BMS_acRippleCurrentAmplitudeRequest";
BA_ "Confidence" SG_ 674 BMS_acRippleRequest 1;
BA_ "Confidence" SG_ 658 BMS_socMin 0;
BA_ "Confidence" SG_ 658 BMS_socUI 0;
BA_ "Confidence" SG_ 658 BMS_socMax 0;
BA_ "Confidence" SG_ 658 BMS_socAvg 0;
BA_ "Confidence" SG_ 658 BMS_beginningOfLifePackEnergy 0;
BA_ "GenSigSNA" SG_ 658 BMS_beginningOfLifePackEnergy "1023";
BA_ "Confidence" SG_ 658 BMS_battTempPct 1;
BA_ "GenSigSNA" SG_ 658 BMS_battTempPct "255";
BA_ "Confidence" SG_ 658 BMS_userChargeCurrentLimitMode 1;
BA_ "Confidence" SG_ 530 BMS_hvacPowerRequest 0;
BA_ "Confidence" SG_ 530 BMS_notEnoughPowerForDrive 0;
BA_ "Confidence" SG_ 530 BMS_notEnoughPowerForSupport 0;
BA_ "Confidence" SG_ 530 BMS_preconditionAllowed 0;
BA_ "Confidence" SG_ 530 BMS_updateAllowed 0;
BA_ "Confidence" SG_ 530 BMS_activeHeatingWorthwhile 1;
BA_ "Confidence" SG_ 530 BMS_cpMiaOnHvs 1;
BA_ "Confidence" SG_ 530 BMS_pcsPwmEnabled 1;
BA_ "Confidence" SG_ 530 BMS_contactorState 0;
BA_ "GenSigSNA" SG_ 530 BMS_contactorState "0";
BA_ "Confidence" SG_ 530 BMS_userChargeStatus 0;
BA_ "Confidence" SG_ 530 BMS_chargeRequest 1;
BA_ "Confidence" SG_ 530 BMS_state 0;
BA_ "GenSigSNA" SG_ 530 BMS_state "9";
BA_ "Confidence" SG_ 530 BMS_diLimpRequest 1;
BA_ "Confidence" SG_ 530 BMS_chgPowerAvailable 1;
BA_ "GenSigSNA" SG_ 530 BMS_chgPowerAvailable "4095";
BA_ "Confidence" SG_ 530 BMS_chargeRetryCount 1;
BA_ "Confidence" SG_ 530 BMS_conditioningRequest 0;
BA_ "Confidence" SG_ 530 BMS_smStateRequest 0;
BA_ "GenSigSNA" SG_ 530 BMS_smStateRequest "9";
BA_ "Confidence" SG_ 530 BMS_hvState 0;
BA_ "Confidence" SG_ 786 BMS_powerDissipation 1;
BA_ "Confidence" SG_ 786 BMS_flowRequest 1;
BA_ "Confidence" SG_ 786 BMS_inletActiveCoolTargetT 1;
BA_ "Confidence" SG_ 786 BMS_inletPassiveTargetT 1;
BA_ "Confidence" SG_ 786 BMS_inletActiveHeatTargetT 1;
BA_ "Confidence" SG_ 786 BMS_minPackTemperature 1;
BA_ "Confidence" SG_ 786 BMS_maxPackTemperature 1;
BA_ "Confidence" SG_ 2028 BMS_coldStagnationLimit 1;
BA_ "Confidence" SG_ 2028 BMS_hotStagnationLimit 1;
BA_ "Confidence" SG_ 2028 BMS_hotCellTempLimit 1;
BA_ "Confidence" SG_ 2028 BMS_activeCoolCellReferenceT 1;
BA_ "Confidence" SG_ 2028 BMS_activeHeatCellTargetT 1;
BA_ "Confidence" SG_ 2028 BMS_cellTempTargetMode 1;
BA_ "Confidence" SG_ 2028 BMS_requestDischarge 1;
BA_ "Confidence" SG_ 754 BMS_nmGoingToSleep 0;
BA_ "Confidence" SG_ 754 BMS_nmWakeUpBus 0;
BA_ "Confidence" SG_ 754 BMS_hvsBusAsleep 0;
BA_ "Confidence" SG_ 754 BMS_nmKeepAwakeReason 1;
BA_ "GenSigSNA" SG_ 754 BMS_nmKeepAwakeReason "0";
BA_ "Confidence" SG_ 754 BMS_nmWakeUpReason 0;
BA_ "Confidence" SG_ 810 BMS_thermalEventSuspected 0;
BA_ "Confidence" SG_ 810 BMS_vehicleNotificationsCounter 0;
BA_ "Confidence" SG_ 810 BMS_isolationResistance 0;
BA_ "GenSigSNA" SG_ 810 BMS_isolationResistance "1023";
BA_ "Confidence" SG_ 810 BMS_vehicleNotificationsChecksum 0;
BA_ "Confidence" SG_ 797 CC_chgStatus2Index 1;
BA_ "Confidence" SG_ 797 CC_buttonState 0;
BA_ "Confidence" SG_ 669 CP_evseOutputDcCurrent 0;
BA_ "Confidence" SG_ 669 CP_evseOutputDcVoltage 0;
BA_ "Confidence" SG_ 669 CP_evseOutputDcCurrentStale 0;
BA_ "Confidence" SG_ 541 CP_evseAccept 0;
BA_ "Confidence" SG_ 541 CP_evseRequest 0;
BA_ "Confidence" SG_ 541 CP_proximity 0;
BA_ "GenSigSNA" SG_ 541 CP_proximity "0";
BA_ "Confidence" SG_ 541 CP_pilot 0;
BA_ "GenSigSNA" SG_ 541 CP_pilot "7";
BA_ "Confidence" SG_ 541 CP_digitalCommsEstablished 0;
BA_ "Confidence" SG_ 541 CP_pilotCurrent 0;
BA_ "Confidence" SG_ 541 CP_cableType 0;
BA_ "GenSigSNA" SG_ 541 CP_cableType "4";
BA_ "Confidence" SG_ 541 CP_iecPilotState 0;
BA_ "GenSigSNA" SG_ 541 CP_iecPilotState "9";
BA_ "Confidence" SG_ 541 CP_plcSupported 0;
BA_ "Confidence" SG_ 541 CP_cableCurrentLimit 0;
BA_ "Confidence" SG_ 541 CP_teslaSwcanState 0;
BA_ "Confidence" SG_ 541 CP_evseChargeType_UI 0;
BA_ "Confidence" SG_ 541 CP_gbState 0;
BA_ "Confidence" SG_ 541 CP_gbdcStopChargeReason 0;
BA_ "Confidence" SG_ 541 CP_gbdcFailureReason 0;
BA_ "Confidence" SG_ 541 CP_gbdcChargeAttempts 0;
BA_ "Confidence" SG_ 541 CP_acChargeState 0;
BA_ "Confidence" SG_ 541 CP_teslaDcState 1;
BA_ "Confidence" SG_ 1885 CP_loggingFastSelect 1;
BA_ "Confidence" SG_ 1885 CP_inductiveSensor_raw 0;
BA_ "Confidence" SG_ 1885 CP_doorOpenActuationTime 0;
BA_ "Confidence" SG_ 1885 CP_doorCloseActuationTime 0;
BA_ "Confidence" SG_ 1885 CP_chargeCableSecured 0;
BA_ "Confidence" SG_ 1885 CP_chargeCablePresent 0;
BA_ "Confidence" SG_ 1885 CP_latchCheckAvailable 0;
BA_ "Confidence" SG_ 1885 CP_UHF_controlState 0;
BA_ "Confidence" SG_ 1885 CP_proximityV 0;
BA_ "Confidence" SG_ 1885 CP_proximityV_GBCC1 0;
BA_ "Confidence" SG_ 1885 CP_proximityV_GBCC2 0;
BA_ "Confidence" SG_ 1885 CP_doorPot 0;
BA_ "Confidence" SG_ 1885 CP_doorOpenRequest 0;
BA_ "Confidence" SG_ 1885 CP_doorOpenEndOfDriveReason 0;
BA_ "Confidence" SG_ 1885 CP_coverClosed 0;
BA_ "Confidence" SG_ 1885 CP_doorCloseEndOfDriveReason 0;
BA_ "Confidence" SG_ 1885 CP_doorCloseRequest 0;
BA_ "Confidence" SG_ 1885 CP_latchDisengagingTime 0;
BA_ "Confidence" SG_ 1885 CP_latchEngagingTime 0;
BA_ "Confidence" SG_ 1885 CP_latchDisengagingStopReason 0;
BA_ "Confidence" SG_ 1885 CP_latchEngagingStopReason 1;
BA_ "Confidence" SG_ 1885 CP_doorIdDetectionState 0;
BA_ "GenSigSNA" SG_ 1885 CP_doorIdDetectionState "0";
BA_ "Confidence" SG_ 1885 CP_doorIdDetectedBin 0;
BA_ "Confidence" SG_ 2042 CP_loggingSlowSelect 1;
BA_ "Confidence" SG_ 2042 CP_UHF_chipState 0;
BA_ "Confidence" SG_ 2042 CP_UHF_rssi 0;
BA_ "Confidence" SG_ 2042 CP_UHF_rxOverflow 0;
BA_ "Confidence" SG_ 2042 CP_UHF_rxNumBytes 0;
BA_ "Confidence" SG_ 2042 CP_UHF_selfTestRssi 0;
BA_ "Confidence" SG_ 2042 CP_latchI 0;
BA_ "Confidence" SG_ 2042 CP_inlet1HarnessIdState 0;
BA_ "GenSigSNA" SG_ 2042 CP_inlet1HarnessIdState "0";
BA_ "Confidence" SG_ 2042 CP_inlet1HarnessIdValue 0;
BA_ "Confidence" SG_ 2042 CP_inlet2HarnessIdState 0;
BA_ "GenSigSNA" SG_ 2042 CP_inlet2HarnessIdState "0";
BA_ "Confidence" SG_ 2042 CP_inlet2HarnessIdValue 0;
BA_ "Confidence" SG_ 2042 CP_inletHeaterState 0;
BA_ "Confidence" SG_ 2042 CP_inletHeaterDuty 0;
BA_ "Confidence" SG_ 2042 CP_nvm_dataValid 0;
BA_ "Confidence" SG_ 2042 CP_doorOpenLimiterMaxCount 1;
BA_ "Confidence" SG_ 2042 CP_doorOpenLimiterMaxRequestType 1;
BA_ "Confidence" SG_ 2042 CP_doorCloseLimiterMaxCount 1;
BA_ "Confidence" SG_ 2042 CP_doorCloseLimiterMaxRequestTyp 1;
BA_ "SystemSignalLongSymbol" SG_ 2042 CP_doorCloseLimiterMaxRequestTyp "CP_doorCloseLimiterMaxRequestType";
BA_ "Confidence" SG_ 528 CP_type 0;
BA_ "Confidence" SG_ 528 CP_insertEnableLine 0;
BA_ "Confidence" SG_ 528 CP_latchState 0;
BA_ "GenSigSNA" SG_ 528 CP_latchState "0";
BA_ "Confidence" SG_ 528 CP_permanentPowerRequest 0;
BA_ "Confidence" SG_ 528 CP_chargeDoorOpen 0;
BA_ "Confidence" SG_ 528 CP_doorControlState 0;
BA_ "Confidence" SG_ 528 CP_doorButtonPressed 0;
BA_ "Confidence" SG_ 528 CP_swcanRelayClosed 0;
BA_ "Confidence" SG_ 528 CP_inhibitOta 0;
BA_ "Confidence" SG_ 528 CP_chargeCableState 0;
BA_ "GenSigSNA" SG_ 528 CP_chargeCableState "0";
BA_ "Confidence" SG_ 528 CP_latchControlState 0;
BA_ "Confidence" SG_ 528 CP_ledColor 0;
BA_ "Confidence" SG_ 528 CP_UHF_handleFound 0;
BA_ "Confidence" SG_ 528 CP_faultLineSensed 0;
BA_ "Confidence" SG_ 528 CP_doorPresenceState 0;
BA_ "Confidence" SG_ 528 CP_inductiveSensorState 0;
BA_ "Confidence" SG_ 528 CP_chargeDoorOpenUI 0;
BA_ "Confidence" SG_ 528 CP_vehicleUnlockRequest 0;
BA_ "Confidence" SG_ 528 CP_coldWeatherMode 0;
BA_ "Confidence" SG_ 528 CP_inletHeaterUiState 1;
BA_ "Confidence" SG_ 893 CP_thermalStatusSelect 1;
BA_ "Confidence" SG_ 893 CP_pinTemperature1 0;
BA_ "Confidence" SG_ 893 CP_pinTemperature2 0;
BA_ "Confidence" SG_ 893 CP_pinTemperature3 0;
BA_ "Confidence" SG_ 583 DAS_roadEstimator 0;
BA_ "Confidence" SG_ 583 DAS_arbiterBehavior 0;
BA_ "Confidence" SG_ 583 DAS_mapAvailability 0;
BA_ "Confidence" SG_ 583 DAS_controllerRef 0;
BA_ "Confidence" SG_ 583 DAS_alcInternalState 0;
BA_ "Confidence" SG_ 583 DAS_behaviorReport 0;
BA_ "Confidence" SG_ 583 DAS_constructionZone 0;
BA_ "Confidence" SG_ 583 DAS_controllerHealth 0;
BA_ "Confidence" SG_ 583 DAS_controlDistance 0;
BA_ "Confidence" SG_ 583 DAS_autopilotAbortReason 0;
BA_ "Confidence" SG_ 583 DAS_rqstedBehaviorStatus 0;
BA_ "Confidence" SG_ 583 DAS_forkState 0;
BA_ "Confidence" SG_ 583 DAS_laneChangeState 0;
BA_ "Confidence" SG_ 583 DAS_lastWatchdogCode 1;
BA_ "Confidence" SG_ 2041 DAS_gpsStatusMultiplexer 1;
BA_ "Confidence" SG_ 2041 DAS_gpsTransportModeState 0;
BA_ "Confidence" SG_ 2041 DAS_gpsSatsInUseHardware 0;
BA_ "Confidence" SG_ 2041 DAS_gpsRejectingSatData 0;
BA_ "Confidence" SG_ 2041 DAS_gpsWheelsOffMotionDetected 0;
BA_ "Confidence" SG_ 2041 DAS_gpsFixTypeHardware 0;
BA_ "Confidence" SG_ 2041 DAS_gpsRawxEnabled 0;
BA_ "Confidence" SG_ 2041 DAS_gpsRxmRawxMia 0;
BA_ "Confidence" SG_ 2041 DAS_gpsRxmSfrbxMia 0;
BA_ "Confidence" SG_ 2041 DAS_gpsEsfMeasMia 0;
BA_ "Confidence" SG_ 2041 DAS_gpsEsfRawMia 0;
BA_ "Confidence" SG_ 2041 DAS_gpsNavStatusMia 0;
BA_ "Confidence" SG_ 2041 DAS_gpsSoftwareConfigured 0;
BA_ "Confidence" SG_ 2041 DAS_gpsSoftwareUsed 0;
BA_ "Confidence" SG_ 2041 DAS_gpsSoftwareFastStartReady 0;
BA_ "Confidence" SG_ 2041 DAS_gpsSatsInUseSoftware 0;
BA_ "Confidence" SG_ 2041 DAS_gpsFixTypeSoftware 0;
BA_ "Confidence" SG_ 2041 DAS_gpsCWJammingInidcator 0;
BA_ "Confidence" SG_ 2041 DAS_gpsJammingState 0;
BA_ "Confidence" SG_ 2041 DAS_gpsSpoofDetectorState 0;
BA_ "Confidence" SG_ 2041 DAS_gpsInvalidMsgPercentage 0;
BA_ "Confidence" SG_ 2041 DAS_gnssConstellationsState 0;
BA_ "Confidence" SG_ 2041 DAS_gpsReceiverNoiseLevel 0;
BA_ "Confidence" SG_ 2041 DAS_gpsAutomaticGainControl 0;
BA_ "Confidence" SG_ 2041 DAS_gpsPreviousPositionDeltaHw 0;
BA_ "Confidence" SG_ 2041 DAS_gpsPreviousPositionDeltaSw 0;
BA_ "Confidence" SG_ 2041 DAS_gpsNmeaDispatchFailureCount 0;
BA_ "Confidence" SG_ 2041 DAS_gnssMaxInstantaneousCnorGps 0;
BA_ "Confidence" SG_ 2041 DAS_gnssMaxInstantaneousCnorGal 0;
BA_ "Confidence" SG_ 2041 DAS_gnssMaxInstantaneousCnorBds 0;
BA_ "Confidence" SG_ 2041 DAS_gpsResetReason 0;
BA_ "Confidence" SG_ 2041 DAS_gpsAccuracyHorizontal 0;
BA_ "Confidence" SG_ 2041 DAS_gpsAccuracyVertical 0;
BA_ "Confidence" SG_ 2041 DAS_gpsSolutionFallback 0;
BA_ "Confidence" SG_ 2041 DAS_gpsToMcuSource 0;
BA_ "Confidence" SG_ 2041 DAS_gpsSolutionSoc 0;
BA_ "Confidence" SG_ 2041 DAS_gpsRedundancyActive 0;
BA_ "Confidence" SG_ 2041 DAS_gpsFixTypeSoftwareSocB 0;
BA_ "Confidence" SG_ 2041 DAS_gpsSatsInUseSoftwareSocB 0;
BA_ "Confidence" SG_ 2041 DAS_gnssNumSatsGps 0;
BA_ "Confidence" SG_ 2041 DAS_gnssNumSatsGal 0;
BA_ "Confidence" SG_ 2041 DAS_gnssNumSatsBds 0;
BA_ "Confidence" SG_ 2041 DAS_gnssAvgInstantaneousCnorGps 0;
BA_ "Confidence" SG_ 2041 DAS_gnssAvgInstantaneousCnorGal 0;
BA_ "Confidence" SG_ 2041 DAS_gnssAvgInstantaneousCnorBds 0;
BA_ "Confidence" SG_ 2041 DAS_gnssAvgInstantaneousCnorGpsL 0;
BA_ "SystemSignalLongSymbol" SG_ 2041 DAS_gnssAvgInstantaneousCnorGpsL "DAS_gnssAvgInstantaneousCnorGpsLowBand";
BA_ "Confidence" SG_ 2041 DAS_gnssAvgInstantaneousCnorGalL 0;
BA_ "SystemSignalLongSymbol" SG_ 2041 DAS_gnssAvgInstantaneousCnorGalL "DAS_gnssAvgInstantaneousCnorGalLowBand";
BA_ "Confidence" SG_ 2041 DAS_gnssAvgInstantaneousCnorBdsL 0;
BA_ "SystemSignalLongSymbol" SG_ 2041 DAS_gnssAvgInstantaneousCnorBdsL "DAS_gnssAvgInstantaneousCnorBdsLowBand";
VAL_ 1383 ADSP_a2baState 19 "INTERRUPT" 18 "PRE_IDLE" 17 "BUS_PARTIAL" 16 "REDISCOVER_RETRY_WAIT" 15 "BUS_DOWN" 14 "COMMAND_START" 13 "COMMAND_STOP" 12 "BUS_ECALL" 11 "BUS_IDLE" 10 "EXT_REQ" 9 "NODE_TEST" 8 "GOING_DOWN" 7 "DISCOVER_RETRY" 6 "DIAG" 5 "IDLE" 4 "DISCOVER_WAIT" 3 "DISCOVER" 2 "RESTART" 1 "DOWN" 0 "INIT" ;
VAL_ 1383 ADSP_a2bbState 19 "INTERRUPT" 18 "PRE_IDLE" 17 "BUS_PARTIAL" 16 "REDISCOVER_RETRY_WAIT" 15 "BUS_DOWN" 14 "COMMAND_START" 13 "COMMAND_STOP" 12 "BUS_ECALL" 11 "BUS_IDLE" 10 "EXT_REQ" 9 "NODE_TEST" 8 "GOING_DOWN" 7 "DISCOVER_RETRY" 6 "DIAG" 5 "IDLE" 4 "DISCOVER_WAIT" 3 "DISCOVER" 2 "RESTART" 1 "DOWN" 0 "INIT" ;
VAL_ 1383 ADSP_baseamp0State 7 "LDSHD_SELF_TEST" 6 "DIAG" 5 "OFF" 4 "TURN_OFF" 3 "HALT" 2 "ENABLED" 1 "CONFIGURED" 0 "INIT" ;
VAL_ 1383 ADSP_baseamp1State 7 "LDSHD_SELF_TEST" 6 "DIAG" 5 "OFF" 4 "TURN_OFF" 3 "HALT" 2 "ENABLED" 1 "CONFIGURED" 0 "INIT" ;
VAL_ 1383 ADSP_baseamp2State 7 "LDSHD_SELF_TEST" 6 "DIAG" 5 "OFF" 4 "TURN_OFF" 3 "HALT" 2 "ENABLED" 1 "CONFIGURED" 0 "INIT" ;
VAL_ 1383 ADSP_baseamp3State 7 "LDSHD_SELF_TEST" 6 "DIAG" 5 "OFF" 4 "TURN_OFF" 3 "HALT" 2 "ENABLED" 1 "CONFIGURED" 0 "INIT" ;
VAL_ 1383 ADSP_ancState 3 "ENABLED" 2 "DSP_ON" 1 "DSP_OFF" 0 "INIT" ;
VAL_ 1383 ADSP_sourceSelect 3 "PINK" 2 "SINE" 1 "TUNER" 0 "MEDIA" ;
VAL_ 1383 ADSP_tunerSelect 1 "XM" 0 "FM" ;
VAL_ 1383 ADSP_ancMode 22 "UNKNOWN" 21 "CALIBRATING_80" 20 "CALIBRATING_60" 19 "CALIBRATING_40" 18 "CALIBRATING_20" 17 "DISABLED_REASON_SENSOR_IMBALANCE" 16 "DISABLED_REASON_MUSIC_LOUD" 15 "DISABLED_REASON_FRUNK_OPEN" 14 "DISABLED_REASON_DOOR_OPEN" 13 "DISABLED_REASON_ACCELS" 12 "DISABLED_REASON_PARKED" 11 "DISABLED_REASON_WINDOW_OPEN" 10 "DISABLED_REASON_REAR_OCCUPANT" 9 "DISABLED_REASON_SEAT_MOVING" 8 "DISABLED_REASON_HVAC" 7 "DISABLED_REASON_CLOSURE_OPEN" 6 "DISABLED_REASON_A2BB" 5 "DISABLED_REASON_A2BA" 4 "CALIBRATING_00" 3 "ALL" 2 "REAR" 1 "FRONT" 0 "OFF" ;
VAL_ 1383 ADSP_eCall_ENS_state 5 "NORMAL" 4 "EMERGENCY" 3 "SOURCE_ERROR" 2 "SOURCE_MISSING" 1 "SIGNAL_ERROR" 0 "UNKOWN" ;
VAL_ 1383 ADSP_eCallSelfTest 2 "FAILED" 1 "PASSED" 0 "NOT_RUN_YET" ;
VAL_ 1383 ADSP_eCallState 1 "ACTIVE" 0 "INACTIVE" ;
VAL_ 1383 ADSP_eCallMicrophoneStatus 2 "FAILED" 1 "PASSED" 0 "NOT_RUN_YET" ;
VAL_ 1383 ADSP_eCallSpeakerStatus 3 "FAILED_DIAG" 2 "FAILED_DISCONNECT" 1 "PASSED" 0 "NOT_RUN_YET" ;
VAL_ 1383 ADSP_requestFailoverSpeaker 1 "TRUE" 0 "FALSE" ;
VAL_ 600 APB_watchdogState 7 "AP_WDOG_STATE_SNA" 4 "AP_WDOG_STATE_SHUTTING_DOWN" 3 "AP_WDOG_STATE_HEALTHY" 2 "AP_WDOG_STATE_CRITICAL" 1 "AP_WDOG_STATE_DEGRADED" 0 "AP_WDOG_STATE_UNKNOWN" ;
VAL_ 600 APB_fusedState 3 "APP_FUSE_SNA" 2 "APP_FUSE_FUSED" 1 "APP_FUSE_UNFUSED" 0 "APP_FUSE_UNKNOWN" ;
VAL_ 600 APB_factorySummonStatus 8 "FACTORY_SUMMON_END_OF_ROUTE" 7 "FACTORY_SUMMON_UNAVAILABLE_HEADING_NOT_INITIALIZED" 6 "FACTORY_SUMMON_UNAVAILABLE_VEHICLE_SPEED_INVALID" 5 "FACTORY_SUMMON_UNAVAILABLE_NO_GPS" 4 "FACTORY_SUMMON_UNAVAILABLE_GOAL_TOO_FAR" 3 "FACTORY_SUMMON_UNAVAILABLE_NO_QR_INSTRUCTION" 2 "FACTORY_SUMMON_AVAILABLE" 1 "FACTORY_SUMMON_ACTIVE" 0 "FACTORY_SUMMON_SNA" ;
VAL_ 600 APB_clipRecordingStatus 4 "APP_CLIP_FAULTED" 3 "APP_CLIP_TRIGGERED" 2 "APP_CLIP_RECORDING" 1 "APP_CLIP_IDLE" 0 "APP_CLIP_NO_DRIVE" ;
VAL_ 600 APB_summonUnavailableReason 28 "SMART_SUMMON_UNAVAILABLE_OUTSIDE_GEOFENCE" 27 "SMART_SUMMON_UNAVAILABLE_ACCEL_PEDAL_PRESSED" 26 "SMART_SUMMON_UNAVAILABLE_BRAKE_PEDAL_PRESSED" 25 "SMART_SUMMON_UNAVAILABLE_REMOTE_STOP_OR_ABORT_REQUEST_ACTIVE" 24 "SMART_SUMMON_UNAVAILABLE_CLOSURE_OPEN" 23 "SMART_SUMMON_UNAVAILABLE_LOW_TIRE_PRESSURE" 22 "SMART_SUMMON_UNAVAILABLE_EXTENDED_COMPUTE_INACTIVE" 21 "SMART_SUMMON_UNAVAILABLE_HIGH_GRADE" 20 "SMART_SUMMON_UNAVAILABLE_NO_CONTEXT" 19 "SMART_SUMMON_UNAVAILABLE_PUBLIC_ROAD_BOUNDARIES_NOT_VALID" 18 "SMART_SUMMON_UNAVAILABLE_ALL_SENSORS_OCCLUDED" 17 "SMART_SUMMON_UNAVAILABLE_ULTRASONIC_STALE" 16 "SMART_SUMMON_UNAVAILABLE_VISION_HEALTH_CRITICAL" 15 "SMART_SUMMON_UNAVAILABLE_CAMERA_NOT_CALIBRATED" 14 "SMART_SUMMON_UNAVAILABLE_END_OF_LEASH" 13 "SMART_SUMMON_UNAVAILABLE_PHONE_IS_TOO_FAR" 12 "SMART_SUMMON_UNAVAILABLE_EGO_GPS_UNAVAILABLE" 11 "SMART_SUMMON_UNAVAILABLE_PHONE_GPS_UNAVAILABLE" 10 "SMART_SUMMON_UNAVAILABLE_POOR_CONNECTION" 9 "SMART_SUMMON_UNAVAILABLE_PUBLIC_ROAD" 8 "SMART_SUMMON_UNAVAILABLE_EAC_UNAVAILABLE" 7 "SMART_SUMMON_UNAVAILABLE_CRUISE_UNAVAILABLE" 6 "SMART_SUMMON_UNAVAILABLE_ULTRASONIC_FAULT" 5 "SMART_SUMMON_UNAVAILABLE_ULTRASONIC_BLOCKED" 4 "SMART_SUMMON_UNAVAILABLE_CAMERA_BLOCKED" 3 "SMART_SUMMON_UNAVAILABLE_CAMERA_STREAM" 2 "SMART_SUMMON_UNAVAILABLE_NOT_IN_PARK" 1 "SMART_SUMMON_UNAVAILABLE_NONE" 0 "SMART_SUMMON_UNAVAILABLE_UNKNOWN" ;
VAL_ 600 APB_fsdSuspendState 3 "SNA" 1 "SUSPENDED" 0 "NOT_SUSPENDED" ;
VAL_ 600 APB_fsdRevokeStrikeoutCount 7 "SNA" ;
VAL_ 600 APB_teslaVisionSupported 3 "SNA" 1 "SUPPORTED" 0 "NOT_SUPPORTED" ;
VAL_ 600 APB_teslaVisionUnsupportedReason 4 "VEHICLE_LOCATION" 3 "UNSUPPORTED_CAMERA" 2 "AP_HARDWARE" 1 "NONE" 0 "UNKNOWN" ;
VAL_ 600 APB_fsdRevokeCount 7 "SNA" ;
VAL_ 600 APB_unifiedObjectStackSupported 3 "SNA" 1 "SUPPORTED" 0 "NOT_SUPPORTED" ;
VAL_ 600 APB_DDAWSystemStatus 4 "DDAW_SYSTEM_SNA" 3 "DDAW_SYSTEM_INVALID" 2 "DDAW_SYSTEM_FAILURE" 1 "DDAW_SYSTEM_DRIVER_DROWSY" 0 "DDAW_SYSTEM_NOMINAL" ;
VAL_ 600 APB_socOperatingMode 2 "AP_DUAL_SOC" 1 "AP_SINGLE_SOC" 0 "AP_UNKNOWN" ;
VAL_ 600 APB_summonVersionIdentifier 1 "ACTUALLY_SMART_SUMMON" 0 "LEGACY_SMART_SUMMON" ;
VAL_ 600 APB_sentryState 6 "SENTRY_SNA" 5 "SENTRY_QUIET" 4 "SENTRY_PANIC" 3 "SENTRY_AWARE" 2 "SENTRY_ARMED" 1 "SENTRY_IDLE" 0 "SENTRY_OFF" ;
VAL_ 600 APB_autoparkVersionIdentifier 2 "ACTUALLY_SMART_AUTOPARK" 1 "V3_VISION_AUTOPARK" 0 "LEGACY_AUTOPARK" ;
VAL_ 909 APP_inTunnel 2 "NOT_IN_TUNNEL" 1 "IN_TUNNEL" 0 "IN_TUNNEL_SNA" ;
VAL_ 909 APP_windshieldHeaterOnReason 7 "WINDSHIELD_HEATER_ON_REASON_HVAC_REQUESTED" 6 "WINDSHIELD_HEATER_ON_REASON_OVERRIDE" 5 "WINDSHIELD_HEATER_ON_REASON_OFF" 4 "WINDSHIELD_HEATER_ON_REASON_STARTUP" 3 "WINDSHIELD_HEATER_ON_REASON_CONDENSATION_LIKELY" 2 "WINDSHIELD_HEATER_ON_REASON_OCCLUDED" 1 "WINDSHIELD_HEATER_ON_REASON_DEFROST" 0 "WINDSHIELD_HEATER_ON_REASON_SNA" ;
VAL_ 909 APP_selfieCameraBlocked 2 "SELFIE_CAMERA_BLOCKED" 1 "SELFIE_CAMERA_NOT_BLOCKED" 0 "SELFIE_CAMERA_BLOCKED_SNA" ;
VAL_ 909 APP_selfieCameraLUX 255 "SNA" 254 "SATURATED" ;
VAL_ 909 APP_sceneTagClearlyRaining 2 "NOT_ACTIVATED" 1 "ACTIVATED" 0 "SNA" ;
VAL_ 909 APP_sceneTagFog 2 "NOT_ACTIVATED" 1 "ACTIVATED" 0 "SNA" ;
VAL_ 909 APP_sceneTagFullyBlocked 2 "NOT_ACTIVATED" 1 "ACTIVATED" 0 "SNA" ;
VAL_ 909 APP_sceneTagIndoors 2 "NOT_ACTIVATED" 1 "ACTIVATED" 0 "SNA" ;
VAL_ 909 APP_sceneTagLensFlare 2 "NOT_ACTIVATED" 1 "ACTIVATED" 0 "SNA" ;
VAL_ 909 APP_sceneTagRaining 2 "NOT_ACTIVATED" 1 "ACTIVATED" 0 "SNA" ;
VAL_ 909 APP_sceneTagSevereWeather 2 "NOT_ACTIVATED" 1 "ACTIVATED" 0 "SNA" ;
VAL_ 909 APP_sceneTagSnowing 2 "NOT_ACTIVATED" 1 "ACTIVATED" 0 "SNA" ;
VAL_ 909 APP_sceneTagSnowyRoad 2 "NOT_ACTIVATED" 1 "ACTIVATED" 0 "SNA" ;
VAL_ 909 APP_sceneTagSunGlare 2 "NOT_ACTIVATED" 1 "ACTIVATED" 0 "SNA" ;
VAL_ 909 APP_sceneTagTunnel 2 "NOT_ACTIVATED" 1 "ACTIVATED" 0 "SNA" ;
VAL_ 909 APP_sceneTagWetRoad 2 "NOT_ACTIVATED" 1 "ACTIVATED" 0 "SNA" ;
VAL_ 909 APP_fisheyeInPathVisibility 4 "VISIBILITY_CONDITION_NOMINAL" 3 "VISIBILITY_OCCLUDED_LOW_SEVERITY" 2 "VISIBILITY_OCCLUDED_MEDIUM_SEVERITY" 1 "VISIBILITY_OCCLUDED_HIGH_SEVERITY" 0 "VISIBILITY_CONDITION_SNA" ;
VAL_ 909 APP_fisheyeOverallVisibility 4 "VISIBILITY_CONDITION_NOMINAL" 3 "VISIBILITY_OCCLUDED_LOW_SEVERITY" 2 "VISIBILITY_OCCLUDED_MEDIUM_SEVERITY" 1 "VISIBILITY_OCCLUDED_HIGH_SEVERITY" 0 "VISIBILITY_CONDITION_SNA" ;
VAL_ 909 APP_mainInPathVisibility 4 "VISIBILITY_CONDITION_NOMINAL" 3 "VISIBILITY_OCCLUDED_LOW_SEVERITY" 2 "VISIBILITY_OCCLUDED_MEDIUM_SEVERITY" 1 "VISIBILITY_OCCLUDED_HIGH_SEVERITY" 0 "VISIBILITY_CONDITION_SNA" ;
VAL_ 909 APP_mainOverallVisibility 4 "VISIBILITY_CONDITION_NOMINAL" 3 "VISIBILITY_OCCLUDED_LOW_SEVERITY" 2 "VISIBILITY_OCCLUDED_MEDIUM_SEVERITY" 1 "VISIBILITY_OCCLUDED_HIGH_SEVERITY" 0 "VISIBILITY_CONDITION_SNA" ;
VAL_ 909 APP_narrowInPathVisibility 4 "VISIBILITY_CONDITION_NOMINAL" 3 "VISIBILITY_OCCLUDED_LOW_SEVERITY" 2 "VISIBILITY_OCCLUDED_MEDIUM_SEVERITY" 1 "VISIBILITY_OCCLUDED_HIGH_SEVERITY" 0 "VISIBILITY_CONDITION_SNA" ;
VAL_ 909 APP_narrowOverallVisibility 4 "VISIBILITY_CONDITION_NOMINAL" 3 "VISIBILITY_OCCLUDED_LOW_SEVERITY" 2 "VISIBILITY_OCCLUDED_MEDIUM_SEVERITY" 1 "VISIBILITY_OCCLUDED_HIGH_SEVERITY" 0 "VISIBILITY_CONDITION_SNA" ;
VAL_ 909 APP_frontCamOcclusionType 6 "UNKNOWN_OCCLUSION" 5 "DEW" 4 "STREAK" 3 "SUN_GLARE" 2 "DIRTY_OR_BLOCKED" 1 "CONDENSATION" 0 "OFFGASSING" ;
VAL_ 2046 APP_cameraPosition 10 "FASCIA" 9 "SELFIE" 8 "BACKUP" 7 "R_REPEATER" 6 "L_REPEATER" 5 "R_PILLAR" 4 "L_PILLAR" 3 "FISHEYE" 2 "NARROW" 1 "MAIN" 0 "INVALID" ;
VAL_ 2046 APP_mainCamExtPitchCal 511 "SNA" ;
VAL_ 2046 APP_mainCamExtYawCal 511 "SNA" ;
VAL_ 2046 APP_mainCalibTime 127 "SNA" ;
VAL_ 2046 APP_mainCalibProgress 127 "SNA" ;
VAL_ 2046 APP_narrowCamExtPitchCal 511 "SNA" ;
VAL_ 2046 APP_narrowCamExtYawCal 511 "SNA" ;
VAL_ 2046 APP_narrowCalibTime 127 "SNA" ;
VAL_ 2046 APP_narrowCalibProgress 127 "SNA" ;
VAL_ 2046 APP_fisheyeCamExtPitchCal 511 "SNA" ;
VAL_ 2046 APP_fisheyeCamExtYawCal 511 "SNA" ;
VAL_ 2046 APP_fisheyeCalibTime 127 "SNA" ;
VAL_ 2046 APP_fisheyeCalibProgress 127 "SNA" ;
VAL_ 2046 APP_lPillarCamExtPitchCal 511 "SNA" ;
VAL_ 2046 APP_lPillarCamExtYawCal 511 "SNA" ;
VAL_ 2046 APP_lPillarCalibTime 127 "SNA" ;
VAL_ 2046 APP_lPillarCalibProgress 127 "SNA" ;
VAL_ 2046 APP_rPillarCamExtPitchCal 511 "SNA" ;
VAL_ 2046 APP_rPillarCamExtYawCal 511 "SNA" ;
VAL_ 2046 APP_rPillarCalibTime 127 "SNA" ;
VAL_ 2046 APP_rPillarCalibProgress 127 "SNA" ;
VAL_ 2046 APP_lRepeatCamExtPitchCal 511 "SNA" ;
VAL_ 2046 APP_lRepeatCamExtYawCal 511 "SNA" ;
VAL_ 2046 APP_lRepeatCalibTime 127 "SNA" ;
VAL_ 2046 APP_lRepeatCalibProgress 127 "SNA" ;
VAL_ 2046 APP_rRepeatCamExtPitchCal 511 "SNA" ;
VAL_ 2046 APP_rRepeatCamExtYawCal 511 "SNA" ;
VAL_ 2046 APP_rRepeatCalibTime 127 "SNA" ;
VAL_ 2046 APP_rRepeatCalibProgress 127 "SNA" ;
VAL_ 2046 APP_backupCamExtPitchCal 511 "SNA" ;
VAL_ 2046 APP_backupCamExtYawCal 511 "SNA" ;
VAL_ 2046 APP_backupCalibTime 127 "SNA" ;
VAL_ 2046 APP_backupCalibProgress 127 "SNA" ;
VAL_ 601 APP_watchdogState 7 "AP_WDOG_STATE_SNA" 4 "AP_WDOG_STATE_SHUTTING_DOWN" 3 "AP_WDOG_STATE_HEALTHY" 2 "AP_WDOG_STATE_CRITICAL" 1 "AP_WDOG_STATE_DEGRADED" 0 "AP_WDOG_STATE_UNKNOWN" ;
VAL_ 601 APP_fusedState 3 "APP_FUSE_SNA" 2 "APP_FUSE_FUSED" 1 "APP_FUSE_UNFUSED" 0 "APP_FUSE_UNKNOWN" ;
VAL_ 601 APP_factorySummonStatus 8 "FACTORY_SUMMON_END_OF_ROUTE" 7 "FACTORY_SUMMON_UNAVAILABLE_HEADING_NOT_INITIALIZED" 6 "FACTORY_SUMMON_UNAVAILABLE_VEHICLE_SPEED_INVALID" 5 "FACTORY_SUMMON_UNAVAILABLE_NO_GPS" 4 "FACTORY_SUMMON_UNAVAILABLE_GOAL_TOO_FAR" 3 "FACTORY_SUMMON_UNAVAILABLE_NO_QR_INSTRUCTION" 2 "FACTORY_SUMMON_AVAILABLE" 1 "FACTORY_SUMMON_ACTIVE" 0 "FACTORY_SUMMON_SNA" ;
VAL_ 601 APP_clipRecordingStatus 4 "APP_CLIP_FAULTED" 3 "APP_CLIP_TRIGGERED" 2 "APP_CLIP_RECORDING" 1 "APP_CLIP_IDLE" 0 "APP_CLIP_NO_DRIVE" ;
VAL_ 601 APP_summonUnavailableReason 28 "SMART_SUMMON_UNAVAILABLE_OUTSIDE_GEOFENCE" 27 "SMART_SUMMON_UNAVAILABLE_ACCEL_PEDAL_PRESSED" 26 "SMART_SUMMON_UNAVAILABLE_BRAKE_PEDAL_PRESSED" 25 "SMART_SUMMON_UNAVAILABLE_REMOTE_STOP_OR_ABORT_REQUEST_ACTIVE" 24 "SMART_SUMMON_UNAVAILABLE_CLOSURE_OPEN" 23 "SMART_SUMMON_UNAVAILABLE_LOW_TIRE_PRESSURE" 22 "SMART_SUMMON_UNAVAILABLE_EXTENDED_COMPUTE_INACTIVE" 21 "SMART_SUMMON_UNAVAILABLE_HIGH_GRADE" 20 "SMART_SUMMON_UNAVAILABLE_NO_CONTEXT" 19 "SMART_SUMMON_UNAVAILABLE_PUBLIC_ROAD_BOUNDARIES_NOT_VALID" 18 "SMART_SUMMON_UNAVAILABLE_ALL_SENSORS_OCCLUDED" 17 "SMART_SUMMON_UNAVAILABLE_ULTRASONIC_STALE" 16 "SMART_SUMMON_UNAVAILABLE_VISION_HEALTH_CRITICAL" 15 "SMART_SUMMON_UNAVAILABLE_CAMERA_NOT_CALIBRATED" 14 "SMART_SUMMON_UNAVAILABLE_END_OF_LEASH" 13 "SMART_SUMMON_UNAVAILABLE_PHONE_IS_TOO_FAR" 12 "SMART_SUMMON_UNAVAILABLE_EGO_GPS_UNAVAILABLE" 11 "SMART_SUMMON_UNAVAILABLE_PHONE_GPS_UNAVAILABLE" 10 "SMART_SUMMON_UNAVAILABLE_POOR_CONNECTION" 9 "SMART_SUMMON_UNAVAILABLE_PUBLIC_ROAD" 8 "SMART_SUMMON_UNAVAILABLE_EAC_UNAVAILABLE" 7 "SMART_SUMMON_UNAVAILABLE_CRUISE_UNAVAILABLE" 6 "SMART_SUMMON_UNAVAILABLE_ULTRASONIC_FAULT" 5 "SMART_SUMMON_UNAVAILABLE_ULTRASONIC_BLOCKED" 4 "SMART_SUMMON_UNAVAILABLE_CAMERA_BLOCKED" 3 "SMART_SUMMON_UNAVAILABLE_CAMERA_STREAM" 2 "SMART_SUMMON_UNAVAILABLE_NOT_IN_PARK" 1 "SMART_SUMMON_UNAVAILABLE_NONE" 0 "SMART_SUMMON_UNAVAILABLE_UNKNOWN" ;
VAL_ 601 APP_fsdSuspendState 3 "SNA" 1 "SUSPENDED" 0 "NOT_SUSPENDED" ;
VAL_ 601 APP_fsdRevokeStrikeoutCount 7 "SNA" ;
VAL_ 601 APP_teslaVisionSupported 3 "SNA" 1 "SUPPORTED" 0 "NOT_SUPPORTED" ;
VAL_ 601 APP_teslaVisionUnsupportedReason 4 "VEHICLE_LOCATION" 3 "UNSUPPORTED_CAMERA" 2 "AP_HARDWARE" 1 "NONE" 0 "UNKNOWN" ;
VAL_ 601 APP_fsdRevokeCount 7 "SNA" ;
VAL_ 601 APP_unifiedObjectStackSupported 3 "SNA" 1 "SUPPORTED" 0 "NOT_SUPPORTED" ;
VAL_ 601 APP_DDAWSystemStatus 4 "DDAW_SYSTEM_SNA" 3 "DDAW_SYSTEM_INVALID" 2 "DDAW_SYSTEM_FAILURE" 1 "DDAW_SYSTEM_DRIVER_DROWSY" 0 "DDAW_SYSTEM_NOMINAL" ;
VAL_ 601 APP_socOperatingMode 2 "AP_DUAL_SOC" 1 "AP_SINGLE_SOC" 0 "AP_UNKNOWN" ;
VAL_ 601 APP_summonVersionIdentifier 1 "ACTUALLY_SMART_SUMMON" 0 "LEGACY_SMART_SUMMON" ;
VAL_ 601 APP_sentryState 6 "SENTRY_SNA" 5 "SENTRY_QUIET" 4 "SENTRY_PANIC" 3 "SENTRY_AWARE" 2 "SENTRY_ARMED" 1 "SENTRY_IDLE" 0 "SENTRY_OFF" ;
VAL_ 601 APP_autoparkVersionIdentifier 2 "ACTUALLY_SMART_AUTOPARK" 1 "V3_VISION_AUTOPARK" 0 "LEGACY_AUTOPARK" ;
VAL_ 2044 APS_primaryTurbo 2 "TURBO_UNKNOWN" 1 "TURBO_B" 0 "TURBO_A" ;
VAL_ 2044 APS_A_arbState 7 "ARB_STATE_COUNT" 6 "ARB_STATE_UNKNOWN" 5 "ARB_STATE_MIA" 4 "ARB_STATE_FAULT" 3 "ARB_STATE_SECONDARY" 2 "ARB_STATE_PRIMARY" 1 "ARB_STATE_IDLE" 0 "ARB_STATE_INIT" ;
VAL_ 2044 APS_A_powerState 28 "POWER_STATE_AP_FORCE_POWER_OFF" 27 "POWER_STATE_AP_WAIT_FOR_SHUTDOWN_ABORT" 26 "POWER_STATE_AP_IN_LINUX" 25 "POWER_STATE_AP_IDLE" 24 "POWER_STATE_VEH_BOOTING" 23 "POWER_STATE_UNKNOWN" 22 "POWER_STATE_MIA" 21 "POWER_STATE_FAULT" 20 "POWER_STATE_SOC_OFF_ABORT" 19 "POWER_STATE_SOC_OFF" 18 "POWER_STATE_SOC_OFF_READY" 17 "POWER_STATE_AP_SUSPENDED" 16 "POWER_STATE_AP_OFF_ABORT_WAIT_FOR_ACK" 15 "POWER_STATE_AP_OFF_ABORT" 14 "POWER_STATE_AP_OFF_READY_WAIT_FOR_RESPONSE" 13 "POWER_STATE_AP_OFF_READY_WAIT_FOR_ACK" 12 "POWER_STATE_AP_OFF_READY" 11 "POWER_STATE_AP_OFF_PREPARE" 10 "POWER_STATE_AP_WAIT_FOR_SHUTDOWN" 9 "POWER_STATE_AP_ON" 8 "POWER_STATE_AP_IN_COREBOOT" 7 "POWER_STATE_AP_BOOTING" 6 "POWER_STATE_AP_ON_READY_WAIT_FOR_RESPONSE" 5 "POWER_STATE_AP_ON_READY_WAIT_FOR_ACK" 4 "POWER_STATE_AP_ON_READY" 3 "POWER_STATE_AP_ON_PREPARE_WAIT_FOR_RESPONSE" 2 "POWER_STATE_AP_ON_PREPARE_WAIT_FOR_ACK" 1 "POWER_STATE_AP_ON_PREPARE" 0 "POWER_STATE_IDLE" ;
VAL_ 2044 APS_A_sleepState 9 "SLEEP_STATE_COUNT" 8 "SLEEP_STATE_UNKNOWN" 7 "SLEEP_STATE_MIA" 6 "SLEEP_STATE_FAULT" 5 "SLEEP_STATE_ABORT" 4 "SLEEP_STATE_SLEEPING" 3 "SLEEP_STATE_GOING_TO_SLEEP" 2 "SLEEP_STATE_READY" 1 "SLEEP_STATE_WAIT_FOR_BUS_SILENCE" 0 "SLEEP_STATE_IDLE" ;
VAL_ 2044 APS_A_resetState 5 "RESET_STATE_COUNT" 4 "RESET_STATE_UNKNOWN" 3 "RESET_STATE_MIA" 2 "RESET_STATE_FAULT" 1 "RESET_STATE_RESETTING" 0 "RESET_STATE_NOT_RESETTING" ;
VAL_ 2044 APS_A_faultState 27 "FAULT_STATE_COUNT" 26 "FAULT_STATE_UNKNOWN" 25 "FAULT_STATE_MIA" 24 "FAULT_STATE_UNEXPECTED" 23 "FAULT_STATE_SCS" 22 "FAULT_STATE_SOFTWARE_FAULT" 21 "FAULT_STATE_TRIP1_FAULT" 20 "FAULT_STATE_TRIP0_FAULT" 19 "FAULT_STATE_WDT" 18 "FAULT_STATE_CPU_FAULT" 17 "FAULT_STATE_DROOP_TRIP" 16 "FAULT_STATE_DROOP_GPU" 15 "FAULT_STATE_DROOP_CPUCL2" 14 "FAULT_STATE_DROOP_CPUCL1" 13 "FAULT_STATE_DROOP_CPUCL0" 12 "FAULT_STATE_MIF_ECC_AP" 11 "FAULT_STATE_MIF7_DFI_ALERT" 10 "FAULT_STATE_MIF6_DFI_ALERT" 9 "FAULT_STATE_MIF5_DFI_ALERT" 8 "FAULT_STATE_MIF4_DFI_ALERT" 7 "FAULT_STATE_MIF3_DFI_ALERT" 6 "FAULT_STATE_MIF2_DFI_ALERT" 5 "FAULT_STATE_MIF1_DFI_ALERT" 4 "FAULT_STATE_MIF0_DFI_ALERT" 3 "FAULT_STATE_MIF_ECC_UNCORRECTED" 2 "FAULT_STATE_MIF_ECC_CORRECTED" 1 "FAULT_STATE_GIC" 0 "FAULT_STATE_NONE" ;
VAL_ 2044 APS_secondaryTurbo 2 "TURBO_UNKNOWN" 1 "TURBO_B" 0 "TURBO_A" ;
VAL_ 2044 APS_B_arbState 7 "ARB_STATE_COUNT" 6 "ARB_STATE_UNKNOWN" 5 "ARB_STATE_MIA" 4 "ARB_STATE_FAULT" 3 "ARB_STATE_SECONDARY" 2 "ARB_STATE_PRIMARY" 1 "ARB_STATE_IDLE" 0 "ARB_STATE_INIT" ;
VAL_ 2044 APS_B_powerState 28 "POWER_STATE_AP_FORCE_POWER_OFF" 27 "POWER_STATE_AP_WAIT_FOR_SHUTDOWN_ABORT" 26 "POWER_STATE_AP_IN_LINUX" 25 "POWER_STATE_AP_IDLE" 24 "POWER_STATE_VEH_BOOTING" 23 "POWER_STATE_UNKNOWN" 22 "POWER_STATE_MIA" 21 "POWER_STATE_FAULT" 20 "POWER_STATE_SOC_OFF_ABORT" 19 "POWER_STATE_SOC_OFF" 18 "POWER_STATE_SOC_OFF_READY" 17 "POWER_STATE_AP_SUSPENDED" 16 "POWER_STATE_AP_OFF_ABORT_WAIT_FOR_ACK" 15 "POWER_STATE_AP_OFF_ABORT" 14 "POWER_STATE_AP_OFF_READY_WAIT_FOR_RESPONSE" 13 "POWER_STATE_AP_OFF_READY_WAIT_FOR_ACK" 12 "POWER_STATE_AP_OFF_READY" 11 "POWER_STATE_AP_OFF_PREPARE" 10 "POWER_STATE_AP_WAIT_FOR_SHUTDOWN" 9 "POWER_STATE_AP_ON" 8 "POWER_STATE_AP_IN_COREBOOT" 7 "POWER_STATE_AP_BOOTING" 6 "POWER_STATE_AP_ON_READY_WAIT_FOR_RESPONSE" 5 "POWER_STATE_AP_ON_READY_WAIT_FOR_ACK" 4 "POWER_STATE_AP_ON_READY" 3 "POWER_STATE_AP_ON_PREPARE_WAIT_FOR_RESPONSE" 2 "POWER_STATE_AP_ON_PREPARE_WAIT_FOR_ACK" 1 "POWER_STATE_AP_ON_PREPARE" 0 "POWER_STATE_IDLE" ;
VAL_ 2044 APS_B_sleepState 9 "SLEEP_STATE_COUNT" 8 "SLEEP_STATE_UNKNOWN" 7 "SLEEP_STATE_MIA" 6 "SLEEP_STATE_FAULT" 5 "SLEEP_STATE_ABORT" 4 "SLEEP_STATE_SLEEPING" 3 "SLEEP_STATE_GOING_TO_SLEEP" 2 "SLEEP_STATE_READY" 1 "SLEEP_STATE_WAIT_FOR_BUS_SILENCE" 0 "SLEEP_STATE_IDLE" ;
VAL_ 2044 APS_B_resetState 5 "RESET_STATE_COUNT" 4 "RESET_STATE_UNKNOWN" 3 "RESET_STATE_MIA" 2 "RESET_STATE_FAULT" 1 "RESET_STATE_RESETTING" 0 "RESET_STATE_NOT_RESETTING" ;
VAL_ 2044 APS_B_faultState 27 "FAULT_STATE_COUNT" 26 "FAULT_STATE_UNKNOWN" 25 "FAULT_STATE_MIA" 24 "FAULT_STATE_UNEXPECTED" 23 "FAULT_STATE_SCS" 22 "FAULT_STATE_SOFTWARE_FAULT" 21 "FAULT_STATE_TRIP1_FAULT" 20 "FAULT_STATE_TRIP0_FAULT" 19 "FAULT_STATE_WDT" 18 "FAULT_STATE_CPU_FAULT" 17 "FAULT_STATE_DROOP_TRIP" 16 "FAULT_STATE_DROOP_GPU" 15 "FAULT_STATE_DROOP_CPUCL2" 14 "FAULT_STATE_DROOP_CPUCL1" 13 "FAULT_STATE_DROOP_CPUCL0" 12 "FAULT_STATE_MIF_ECC_AP" 11 "FAULT_STATE_MIF7_DFI_ALERT" 10 "FAULT_STATE_MIF6_DFI_ALERT" 9 "FAULT_STATE_MIF5_DFI_ALERT" 8 "FAULT_STATE_MIF4_DFI_ALERT" 7 "FAULT_STATE_MIF3_DFI_ALERT" 6 "FAULT_STATE_MIF2_DFI_ALERT" 5 "FAULT_STATE_MIF1_DFI_ALERT" 4 "FAULT_STATE_MIF0_DFI_ALERT" 3 "FAULT_STATE_MIF_ECC_UNCORRECTED" 2 "FAULT_STATE_MIF_ECC_CORRECTED" 1 "FAULT_STATE_GIC" 0 "FAULT_STATE_NONE" ;
VAL_ 970 APS_appStatusMonitorState 7 "STATUS_MONITOR_NUM_STATES" 6 "STATUS_MONITOR_STATE_RECOVERY" 5 "STATUS_MONITOR_STATE_SHUTTING_DOWN" 4 "STATUS_MONITOR_STATE_CRITICAL" 3 "STATUS_MONITOR_STATE_NOMINAL" 2 "STATUS_MONITOR_STATE_INIT" 1 "STATUS_MONITOR_STATE_PWR_OFF" 0 "STATUS_MONITOR_STATE_UNKNOWN" ;
VAL_ 970 APS_vehBehaviorState 8 "VEH_BEHAVIOR_NUM_STATES" 7 "VEH_BEHAVIOR_STATE_SYSTEM_FAULT" 6 "VEH_BEHAVIOR_STATE_APS_OVERRIDE" 5 "VEH_BEHAVIOR_STATE_APS_FAIL_SAFE" 4 "VEH_BEHAVIOR_STATE_APS_BRIDGE_APB" 3 "VEH_BEHAVIOR_STATE_APS_BRIDGE_APP" 2 "VEH_BEHAVIOR_STATE_APS_CONTROL" 1 "VEH_BEHAVIOR_STATE_APS_AVAILABLE" 0 "VEH_BEHAVIOR_STATE_UNKNOWN" ;
VAL_ 970 APS_canMaster 3 "CAN_MASTER_SNA" 2 "CAN_MASTER_APB" 1 "CAN_MASTER_APP" 0 "CAN_MASTER_APS" ;
VAL_ 970 APS_appGpioState 3 "AP_GPIO_STATE_HEALTHY" 2 "AP_GPIO_STATE_CRITICAL" 1 "AP_GPIO_STATE_DISABLED" 0 "AP_GPIO_STATE_PWR_DOWN_REBOOT" ;
VAL_ 970 APS_eacInternalState 7 "APS_EAC_NUM_STATES" 6 "APS_EAC_STATE_LSS" 5 "APS_EAC_STATE_OVERRIDE" 4 "APS_EAC_STATE_INHIBIT" 3 "APS_EAC_STATE_AUTOPARK" 2 "APS_EAC_STATE_CONTINUOUS" 1 "APS_EAC_STATE_MOMENTARY" 0 "APS_EAC_STATE_INIT" ;
VAL_ 970 APS_apbStatusMonitorState 7 "STATUS_MONITOR_NUM_STATES" 6 "STATUS_MONITOR_STATE_RECOVERY" 5 "STATUS_MONITOR_STATE_SHUTTING_DOWN" 4 "STATUS_MONITOR_STATE_CRITICAL" 3 "STATUS_MONITOR_STATE_NOMINAL" 2 "STATUS_MONITOR_STATE_INIT" 1 "STATUS_MONITOR_STATE_PWR_OFF" 0 "STATUS_MONITOR_STATE_UNKNOWN" ;
VAL_ 970 APS_apbGpioState 3 "AP_GPIO_STATE_HEALTHY" 2 "AP_GPIO_STATE_CRITICAL" 1 "AP_GPIO_STATE_DISABLED" 0 "AP_GPIO_STATE_PWR_DOWN_REBOOT" ;
VAL_ 970 APS_locLimitReason 7 "LOC_LIMITS_EXTENDED" 6 "LOC_MONITOR_UNAVAILABLE" 5 "NO_RADAR_TARGET" 4 "RADAR_NOT_HEALTHY" 3 "PRIMARY_AP_NOT_HEALTHY" 2 "ACC_AND_AEB_UNAVAILABLE" 1 "NOT_IN_DRIVE" 0 "NOMINAL_DEFAULT" ;
VAL_ 970 APS_appPowerStateRequest 3 "AP_POWER_STATE_SLEEP" 2 "AP_POWER_STATE_SUSPEND" 1 "AP_POWER_STATE_SENTRY" 0 "AP_POWER_STATE_NOMINAL" ;
VAL_ 970 APS_appPowerStateReason 12 "UI_SUMMON_STANDBY_MODE_ENABLED" 11 "SLEEP_REQUEST_RECVD" 10 "AP_POWER_REQUEST_OVERHEATED" 9 "LOADSHED_POWER_REQUEST_PENDING" 8 "VC_POWER_REQUEST" 7 "AP_POWER_REQUEST_OVERRIDE" 6 "AP_POWER_REQUEST_OVERHEATING" 5 "AP_POWER_REQUEST_HYSTERESIS" 4 "GTW_GOTO_FULL_POWER" 3 "AP_NOT_IN_PARK" 2 "AP_NM_REASON_SET" 1 "AP_WDOG_UNHEALTHY" 0 "UI_POWER_STATE_REQUEST" ;
VAL_ 970 APS_apbPowerStateRequest 3 "AP_POWER_STATE_SLEEP" 2 "AP_POWER_STATE_SUSPEND" 1 "AP_POWER_STATE_SENTRY" 0 "AP_POWER_STATE_NOMINAL" ;
VAL_ 970 APS_apbPowerStateReason 12 "UI_SUMMON_STANDBY_MODE_ENABLED" 11 "SLEEP_REQUEST_RECVD" 10 "AP_POWER_REQUEST_OVERHEATED" 9 "LOADSHED_POWER_REQUEST_PENDING" 8 "VC_POWER_REQUEST" 7 "AP_POWER_REQUEST_OVERRIDE" 6 "AP_POWER_REQUEST_OVERHEATING" 5 "AP_POWER_REQUEST_HYSTERESIS" 4 "GTW_GOTO_FULL_POWER" 3 "AP_NOT_IN_PARK" 2 "AP_NM_REASON_SET" 1 "AP_WDOG_UNHEALTHY" 0 "UI_POWER_STATE_REQUEST" ;
VAL_ 970 APS_heaterStateDebug 7 "APS_HEATER_SNA" 4 "APS_HEATER_FAULT_SHORT" 3 "APS_HEATER_FAULT_OPEN" 2 "APS_HEATER_ON_NOT_HEATING" 1 "APS_HEATER_ON_HEATING" 0 "APS_HEATER_OFF" ;
VAL_ 970 APS_gpsAntennaState 2 "GPS_ANTENNA_CONNECTED" 1 "GPS_ANTENNA_UNKNOWN" 0 "GPS_ANTENNA_DISCONNECTED" ;
VAL_ 970 APS_arbState 7 "ARB_STATE_N_COUNT" 6 "ARB_STATE_N_UNKNOWN" 5 "ARB_STATE_N_MIA" 4 "ARB_STATE_N_FAULT" 3 "ARB_STATE_N_SECONDARY" 2 "ARB_STATE_N_PRIMARY" 1 "ARB_STATE_N_IDLE" 0 "ARB_STATE_N_INIT" ;
VAL_ 970 APS_socPowerOperatingMode 2 "APS_DUAL_SOC" 1 "APS_SINGLE_SOC" 0 "APS_UNKNOWN" ;
VAL_ 970 APS_otherArbState 7 "ARB_STATE_N_COUNT" 6 "ARB_STATE_N_UNKNOWN" 5 "ARB_STATE_N_MIA" 4 "ARB_STATE_N_FAULT" 3 "ARB_STATE_N_SECONDARY" 2 "ARB_STATE_N_PRIMARY" 1 "ARB_STATE_N_IDLE" 0 "ARB_STATE_N_INIT" ;
VAL_ 943 BB_sOutputRodQF 2 "Faulty" 1 "Normal" 0 "NotInit_orOff" ;
VAL_ 943 BB_sInputRodQF 2 "Faulty" 1 "Normal" 0 "NotInit_orOff" ;
VAL_ 943 BB_driverBrakeApply 1 "DRIVER_APPLYING_BRAKES" 0 "BRAKES_NOT_APPLIED" ;
VAL_ 943 BB_driverBrakeApplyQF 2 "Faulty" 1 "Normal" 0 "NotInit_orOff" ;
VAL_ 943 BB_boosterStatus 6 "ACTUATION" 5 "READY" 4 "ACTIVE_GOOD_CHECK" 3 "DIAGNOSTIC" 2 "FAILURE" 1 "INIT" 0 "OFF" ;
VAL_ 943 BB_warningLampRequest 2 "RED_BRAKE_LAMP_REQUEST" 1 "YELLOW_BRAKE_LAMP_REQUEST" 0 "NO_LAMP_REQUEST" ;
VAL_ 943 BB_brakeFluidLevel 3 "BRAKE_FLUID_LEVEL_INVALID" 2 "BRAKE_FLUID_LEVEL_NORMAL" 1 "BRAKE_FLUID_LEVEL_LOW" 0 "BRAKE_FLUID_LEVEL_UNKNOWN" ;
VAL_ 943 BB_internalState 7 "READY_TO_SHUTDOWN" 6 "POST_DRIVE_CHECK" 5 "TRANSITION_TO_IDLE" 4 "DIAGNOSTIC" 3 "EXTERNAL_BRAKE_REQUEST" 2 "LOCAL_BRAKE_REQUEST" 1 "PRE_DRIVE_CHECK" 0 "NO_MODE_ACTIVE" ;
VAL_ 1138 BMS_chargeCurrentLimitMode 20 "CHG_LIMIT_RIPPLE_HEAT_ACTIVE" 19 "CHG_LIMIT_NEAR_HWOT_LIMIT" 18 "CHG_LIMIT_LIMP_MODE" 17 "CHG_LIMIT_MISSING_CELL" 16 "CHG_LIMIT_CAC_IMBALANCE" 15 "CHG_LIMIT_PCS_IMPLICIT" 14 "CHG_LIMIT_EVSE_IMPLICIT" 13 "CHG_LIMIT_RAMP_UP_PHASE" 12 "CHG_LIMIT_HVAC_COOLING" 11 "CHG_LIMIT_HV_CHAIN" 10 "CHG_LIMIT_CONFIG" 9 "CHG_LIMIT_TETHERING" 8 "CHG_LIMIT_LEAKY_BUCKET" 7 "CHG_LIMIT_BRICK_VOLTAGE_REG" 6 "CHG_LIMIT_BRICK_TEMP_TOO_COLD" 5 "CHG_LIMIT_BRICK_TEMP_TOO_HOT" 4 "CHG_LIMIT_BRICK_TEMP_OPTIMAL_CELL_PROFILE" 3 "CHG_LIMIT_CP" 2 "CHG_LIMIT_PCS" 1 "CHG_LIMIT_EVSE" 0 "CHG_LIMIT_NONE" ;
VAL_ 1138 BMS_timeToFinishHeatForCharge 127 "SNA" 126 "CALCULATING" ;
VAL_ 1138 BMS_diNodeModelTemp 2047 "SNA" ;
VAL_ 2029 BMS_10HzDebug_Id 34 "AGED_SOC_OCV" 33 "THM_TARGETS" 32 "SOC_AND_OCV" 31 "DRIVE_LIMITS" 30 "STANDBY_SUPPLY" 29 "SLEEP_WAKE" 28 "POWER_PREDICTION_3" 27 "POWER_PREDICTION_2" 26 "POWER_PREDICTION_1" 25 "ADC_FLOOD" 24 "ADC_MISC" 23 "ADC_DCLINK" 22 "ADC_CP" 21 "ADC_VREF" 20 "WAKE_TIMERS" 19 "CAC_3" 18 "CAC_2" 17 "CAC_1" 16 "HYST" 15 "PACK_VOLTAGES" 14 "THM_MODEL_DATA_11" 13 "THM_MODEL_DATA_10" 12 "THM_MODEL_DATA_9" 3 "SOC_RESTING" 2 "ISOLATION" 1 "AHR_COUNTER" 0 "STATE" ;
VAL_ 306 BMS_packCurrent -32768 "SNA" ;
VAL_ 306 BMS_currentUnfiltered -32768 "SNA" ;
VAL_ 306 BMS_chgTimeToFull 4095 "SNA" ;
VAL_ 884 BMS_log1MuxId 27 "SLEEP_CURRENT_2" 26 "SLEEP_CURRENT_1" 25 "CHARGE_LIMIT_2" 24 "CHARGE_LIMIT_1" 23 "CHARGE_ENERGY_4" 22 "CHARGE_ENERGY_3" 21 "CHARGE_ENERGY_2" 20 "CHARGE_ENERGY_1" 19 "PACK_DATA" 18 "IMPEDANCE_DEVIATION_2" 17 "IMPEDANCE_DEVIATION_1" 16 "SOC_BY_DELTA_V_2" 15 "SOC_BY_DELTA_V_1" 14 "CHARGE_REGULATION" 13 "CHARGE_TERMINATION" 12 "BANDOLIER_MODEL_THERMISTOR_TEMPS_2" 11 "BANDOLIER_MODEL_THERMISTOR_TEMPS_1" 10 "BANDOLIER_MODEL_PACK_TEMPS" 9 "CHARGE_INTERFACE_2" 8 "CHARGE_INTERFACE_1" 7 "NEG_CTR_HEALTH_2" 6 "NEG_CTR_HEALTH_1" 5 "POS_CTR_HEALTH_2" 4 "POS_CTR_HEALTH_1" 3 "STATES_AND_BOOLS" 2 "CPU_USAGE3" 1 "CPU_USAGE2" 0 "CPU_USAGE1" ;
VAL_ 946 BMS_log2MuxId 83 "MUX_83" 82 "MUX_82" 81 "MUX_81" 80 "MUX_80" 79 "MUX_79" 78 "MUX_78" 77 "MUX_77" 76 "MUX_76" 75 "MUX_75" 74 "MUX_74" 73 "MUX_73" 72 "MUX_72" 71 "MUX_71" 70 "MUX_70" 69 "MUX_69" 68 "MUX_68" 67 "MUX_67" 66 "MUX_66" 65 "MUX_65" 64 "MUX_64" 63 "MUX_63" 62 "MUX_62" 61 "MUX_61" 60 "MUX_60" 59 "MUX_59" 58 "MUX_58" 57 "MUX_57" 56 "MUX_56" 55 "LIFE_MODEL_HIST_SUMMARY_DATA" 54 "LIFE_MODEL_STORAGE_HIST_DATA" 53 "SPME_MAX_SOC_BRICK_DATA" 52 "SPME_MIN_SOC_BRICK_DATA" 51 "SPME_DATA_3" 50 "SPME_BRICK_1_DATA_2" 49 "SPME_BRICK_1_DATA_1" 48 "SPME_PACK_LEVEL" 47 "BRICK_BLEED_TIMES_5" 46 "HISTOGRAMS_SUMMARY" 45 "SOH" 44 "CAC4" 43 "ISOLATION" 42 "BRICK_BLEED_TIMES_4" 41 "BRICK_BLEED_TIMES_3" 40 "BRICK_BLEED_TIMES_2" 39 "BRICK_BLEED_TIMES_1" 38 "LIFE_MODEL" 37 "BRICK_BALANCE_4" 36 "BRICK_BALANCE_3" 35 "BRICK_BALANCE_2" 34 "BRICK_BALANCE_1" 33 "ALPHA_1" 32 "HISTOGRAMS_4" 31 "HISTOGRAMS_3" 30 "HISTOGRAMS_2" 29 "HISTOGRAMS_1" 28 "HISTOGRAMS_0" 27 "VSH_RES_3" 26 "VSH_RES_2" 25 "VSH_RES_1" 24 "SOC_BY_OCV_CORRECTION" 23 "BRICK_VOLTAGE_CHANGE" 22 "CAC3" 21 "ENERGY_AND_REST_DATA" 20 "FC_LINK_LEAKAGE_TEST" 19 "ENERGY_RESERVE" 18 "HV_CHAIN_MODEL" 17 "NEG_CTR_HEALTH_4" 16 "NEG_CTR_HEALTH_3" 15 "NEG_CTR_HEALTH_2" 14 "NEG_CTR_HEALTH_1" 13 "POS_CTR_HEALTH_4" 12 "POS_CTR_HEALTH_3" 11 "POS_CTR_HEALTH_2" 10 "POS_CTR_HEALTH_1" 9 "CTR_RESISTANCE" 8 "100HZ_1KHZ_TASK_STATS" 7 "10HZ_TASK_STATS" 6 "1HZ_TASK_STATS" 5 "AHR_COUNTER" 4 "CHARGING" 3 "VSH_TEST" 2 "FLOOD_PORT" 1 "CAC2" 0 "CAC1" ;
VAL_ 946 BMS_hvChain_iLimit 16383 "SNA" ;
VAL_ 946 BMS_hvChain_limitingState 511 "SNA" ;
VAL_ 946 BMS_hvChain_limitingStateTempera -4096 "SNA" ;
VAL_ 946 BMS_fcLinkTestDecayTime 1023 "SNA" ;
VAL_ 946 BMS_idealEnergyFloor 1023 "SNA" ;
VAL_ 946 BMS_dynamicEnergyBuffer 1023 "SNA" ;
VAL_ 946 BMS_dSocNormalizedMin 4095 "SNA" ;
VAL_ 946 BMS_dSocNormalizedFiltMin 4095 "SNA" ;
VAL_ 946 BMS_dSocMinAlpha 4095 "SNA" ;
VAL_ 946 BMS_dSocCacMargin 511 "SNA" ;
VAL_ 946 BMS_lifeModelAvgTempSeverity 31 "SNA" ;
VAL_ 946 BMS_lifeModelDepthOfDischargeSev 255 "SNA" ;
VAL_ 946 BMS_lifeModelHistogramCapacityLo 511 "SNA" ;
VAL_ 946 BMS_lifeModelHistogramBrickCapac 8191 "SNA" ;
VAL_ 946 BMS_lifeModelDcrGrowthPercent -8192 "SNA" ;
VAL_ 946 BMS_nominalFullPackEnergyRaw 65535 "SNA" ;
VAL_ 946 BMS_userChargeCalibratingReason 2 "USR_CHG_CALIBRATING_RUBBER_BANDING_HOLD" 1 "USR_CHG_CALIBRATING_FULL_CHARGE" 0 "USR_CHG_CALIBRATING_INACTIVE" ;
VAL_ 946 BMS_nominalEnergyRemainingBuffer 65535 "SNA" ;
VAL_ 946 BMS_idealEnergyRemainingBuffered 65535 "SNA" ;
VAL_ 946 BMS_largestCacSpreadErrorLower 4095 "SNA" ;
VAL_ 946 BMS_lifeModelAverageCac 4095 "SNA" ;
VAL_ 946 BMS_lifeModelCacBrick1 4095 "SNA" ;
VAL_ 946 BMS_lifeModelAverageOffset -512 "SNA" ;
VAL_ 946 BMS_lifeModelMaxCacBrickId 255 "SNA" ;
VAL_ 946 BMS_lifeModelMaxCac 4095 "SNA" ;
VAL_ 946 BMS_lifeModelMinCacBrickId 255 "SNA" ;
VAL_ 946 BMS_lifeModelMinCac 4095 "SNA" ;
VAL_ 946 BMS_restingPointCacAvg 4095 "SNA" ;
VAL_ 946 BMS_cacEstimationSource 2 "CAC_SOURCE_LIFE_MODEL" 1 "CAC_SOURCE_RESTING_POINT_CAC" 0 "CAC_SOURCE_UNKNOWN" ;
VAL_ 946 BMS_synchronizedCacMaxRaw 4095 "SNA" ;
VAL_ 946 BMS_synchronizedCacMinRaw 4095 "SNA" ;
VAL_ 946 BMS_sohEnergy 2047 "SNA" ;
VAL_ 946 BMS_fullCapacitySohEnergy 2047 "SNA" ;
VAL_ 946 BMS_calibratedCapacitySohEnergy 2047 "SNA" ;
VAL_ 946 BMS_estimatedCapacitySohEnergy 2047 "SNA" ;
VAL_ 946 BMS_prevUserFacingSohEnergy 2047 "SNA" ;
VAL_ 946 BMS_stateOfHealthMinCac 8191 "SNA" ;
VAL_ 946 BMS_lifeModelStorageLossPackAge 16383 "SNA" ;
VAL_ 946 BMS_lifeModelThroughputCycleCoun 4095 "SNA" ;
VAL_ 946 BMS_lifeModelThroughputDcrCycleC 4095 "SNA" ;
VAL_ 946 BMS_stateOfHealth 1023 "SNA" ;
VAL_ 914 BMS_packConfigMultiplexer 1 "Mux1" 0 "Mux0" ;
VAL_ 914 BMS_reservedConfig_0 31 "BMS_CONFIG_31" 30 "BMS_CONFIG_30" 29 "BMS_CONFIG_29" 28 "BMS_CONFIG_28" 27 "BMS_CONFIG_27" 26 "BMS_CONFIG_26" 25 "BMS_CONFIG_25" 24 "BMS_CONFIG_24" 23 "BMS_CONFIG_23" 22 "BMS_CONFIG_22" 21 "BMS_CONFIG_21" 20 "BMS_CONFIG_20" 19 "BMS_CONFIG_19" 18 "BMS_CONFIG_18" 17 "BMS_CONFIG_17" 16 "BMS_CONFIG_16" 15 "BMS_CONFIG_15" 14 "BMS_CONFIG_14" 13 "BMS_CONFIG_13" 12 "BMS_CONFIG_12" 11 "BMS_CONFIG_11" 10 "BMS_CONFIG_10" 9 "BMS_CONFIG_9" 8 "BMS_CONFIG_8" 7 "BMS_CONFIG_7" 6 "BMS_CONFIG_6" 5 "BMS_CONFIG_5" 4 "BMS_CONFIG_4" 3 "BMS_CONFIG_3" 2 "BMS_CONFIG_2" 1 "BMS_CONFIG_1" 0 "BMS_CONFIG_0" ;
VAL_ 914 BMS_moduleType 5 "BMS_MOD_TYPE_5" 4 "BMS_MOD_TYPE_4" 3 "BMS_MOD_TYPE_3" 2 "BMS_MOD_TYPE_2" 1 "BMS_MOD_TYPE_1" 0 "BMS_MOD_TYPE_UNKNOWN" ;
VAL_ 914 BMS_thermalPackType 9 "E3D_40P" 8 "E3D" 7 "BLADERUNNER_E1" 6 "BFF00S" 5 "P2" 4 "BFF00_E1" 3 "CATL_E1" 2 "E3" 1 "E1" 0 "UNKNOWN" ;
VAL_ 914 BMS_standbySupplyContinuousPower 3 "17W" 2 "16W" 1 "4W" 0 "0W" ;
VAL_ 594 BMS_powerLimitsState 1 "POWER_CALCULATED_FOR_DRIVE" 0 "POWER_NOT_CALCULATED_FOR_DRIVE" ;
VAL_ 594 BMS_instantChargePowerCapability 65535 "SNA" ;
VAL_ 674 BMS_acRippleFrequencyRequest 63 "SNA" ;
VAL_ 674 BMS_acRippleRequest 4 "RIPPLE_FAULTED" 3 "RIPPLE_ON" 2 "RIPPLE_STANDBY" 1 "RIPPLE_OFF" 0 "RIPPLE_NOT_SUPPORTED" ;
VAL_ 658 BMS_beginningOfLifePackEnergy 1023 "SNA" ;
VAL_ 658 BMS_battTempPct 255 "SNA" ;
VAL_ 658 BMS_userChargeCurrentLimitMode 4 "USR_CHG_LIMIT_EVSE_RELOCATION_RECOMMENDED" 3 "USR_CHG_LIMIT_HIGH_SOC" 2 "USR_CHG_LIMIT_BATT_TEMP_LOW" 1 "USR_CHG_LIMIT_EVSE" 0 "USR_CHG_LIMIT_NONE" ;
VAL_ 530 BMS_contactorState 6 "BMS_CTRSET_BLOCKED" 5 "BMS_CTRSET_WELDED" 4 "BMS_CTRSET_CLOSED" 3 "BMS_CTRSET_CLOSING" 2 "BMS_CTRSET_OPENING" 1 "BMS_CTRSET_OPEN" 0 "BMS_CTRSET_SNA" ;
VAL_ 530 BMS_userChargeStatus 6 "BMS_CALIBRATING" 5 "BMS_CHARGE_STOPPED" 4 "BMS_CHARGE_COMPLETE" 3 "BMS_CHARGING" 2 "BMS_ABOUT_TO_CHARGE" 1 "BMS_NO_POWER" 0 "BMS_DISCONNECTED" ;
VAL_ 530 BMS_state 10 "BMS_DIAG" 9 "BMS_SNA" 8 "BMS_TEST" 7 "BMS_WELD" 6 "BMS_FAULT" 5 "BMS_CLEAR_FAULT" 4 "BMS_FEIM" 3 "BMS_CHARGE" 2 "BMS_SUPPORT" 1 "BMS_DRIVE" 0 "BMS_STANDBY" ;
VAL_ 530 BMS_diLimpRequest 1 "LIMP_REQUEST_WELDED" 0 "LIMP_REQUEST_NONE" ;
VAL_ 530 BMS_chgPowerAvailable 4095 "SNA" ;
VAL_ 530 BMS_smStateRequest 10 "BMS_DIAG" 9 "BMS_SNA" 8 "BMS_TEST" 7 "BMS_WELD" 6 "BMS_FAULT" 5 "BMS_CLEAR_FAULT" 4 "BMS_FEIM" 3 "BMS_CHARGE" 2 "BMS_SUPPORT" 1 "BMS_DRIVE" 0 "BMS_STANDBY" ;
VAL_ 530 BMS_hvState 6 "HV_UP" 5 "HV_UP_FOR_DC_CHARGE" 4 "HV_UP_FOR_CHARGE" 3 "HV_UP_FOR_DRIVE" 2 "HV_GOING_DOWN" 1 "HV_COMING_UP" 0 "HV_DOWN" ;
VAL_ 2028 BMS_cellTempTargetMode 11 "V2X_SESSION" 10 "PASSIVE_COOL_ON_NAV" 9 "ACTIVE_COOL_ON_NAV" 8 "SOH_HEAT_PACK" 7 "DRAGSTRIP" 6 "PASSIVE_HEAT_ON_NAV" 5 "ACTIVE_HEAT_ON_NAV" 4 "DISCONNECTED_PRECONDITION" 3 "CONNECTED_PRECONDITION" 2 "HIGH_POWER_CHARGE" 1 "LOW_POWER_CHARGE" 0 "DEFAULT" ;
VAL_ 754 BMS_nmKeepAwakeReason 7 "BMS_KEEPAWAKE_REASON_PRECONDITIONING" 6 "BMS_KEEPAWAKE_REASON_CP_ACTIVE" 5 "BMS_KEEPAWAKE_REASON_BMS_ACTIVE" 4 "BMS_KEEPAWAKE_REASON_HVP_ACTIVE" 3 "BMS_KEEPAWAKE_REASON_FC_CTR_CLEANING" 2 "BMS_KEEPAWAKE_REASON_CRITICAL_ALERT" 1 "BMS_KEEPAWAKE_REASON_CTRS_CLOSED" 0 "BMS_KEEPAWAKE_REASON_NONE_SNA" ;
VAL_ 754 BMS_nmWakeUpReason 4 "BMS_WAKEUP_REASON_CRITICALALERT" 3 "BMS_WAKEUP_REASON_WANTTOCHARGE" 2 "BMS_WAKEUP_REASON_CAN_HVS" 1 "BMS_WAKEUP_REASON_CAN_VEH" 0 "BMS_WAKEUP_REASON_NONE" ;
VAL_ 810 BMS_isolationResistance 1023 "SNA" ;
VAL_ 797 CC_chgStatus2Index 0 "Mux0" ;
VAL_ 797 CC_buttonState 1 "CC_BUTTON_PRESSED" 0 "CC_BUTTON_RELEASED" ;
VAL_ 541 CP_proximity 3 "CHG_PROXIMITY_LATCHED" 2 "CHG_PROXIMITY_UNLATCHED" 1 "CHG_PROXIMITY_DISCONNECTED" 0 "CHG_PROXIMITY_SNA" ;
VAL_ 541 CP_pilot 7 "CHG_PILOT_SNA" 6 "CHG_PILOT_UNUSED_6" 5 "CHG_PILOT_INVALID" 4 "CHG_PILOT_IDLE" 3 "CHG_PILOT_FAST_CHARGE" 2 "CHG_PILOT_LINE_CHARGE" 1 "CHG_PILOT_FAULTED" 0 "CHG_PILOT_NONE" ;
VAL_ 541 CP_cableType 5 "CHG_CABLE_TYPE_SNA" 4 "CHG_CABLE_TYPE_MCS" 3 "CHG_CABLE_TYPE_GB_DC" 2 "CHG_CABLE_TYPE_GB_AC" 1 "CHG_CABLE_TYPE_SAE" 0 "CHG_CABLE_TYPE_IEC" ;
VAL_ 541 CP_iecPilotState 9 "IEC_PILOT_SNA" 8 "IEC_PILOT_NUM" 7 "IEC_PILOT_F" 6 "IEC_PILOT_E" 5 "IEC_PILOT_C3" 4 "IEC_PILOT_C2" 3 "IEC_PILOT_C1" 2 "IEC_PILOT_B3" 1 "IEC_PILOT_B2" 0 "IEC_PILOT_B1" ;
VAL_ 541 CP_teslaSwcanState 8 "TESLA_SWCAN_V2L_ESTABLISHED" 7 "TESLA_SWCAN_V2L_RECEIVE" 6 "TESLA_SWCAN_OFFBOARD_UPDATE_IN_PROGRESS" 5 "TESLA_SWCAN_GO_TO_SLEEP" 4 "TESLA_SWCAN_FAULT" 3 "TESLA_SWCAN_ESTABLISHED" 2 "TESLA_SWCAN_RECEIVE" 1 "TESLA_SWCAN_ACCEPT" 0 "TESLA_SWCAN_INACTIVE" ;
VAL_ 541 CP_evseChargeType_UI 2 "AC_CHARGER_PRESENT" 1 "DC_CHARGER_PRESENT" 0 "NO_CHARGER_PRESENT" ;
VAL_ 541 CP_gbState 15 "GBDC_TESTER_PRESENT" 14 "GBDC_FAULTED" 13 "GBDC_RETRY_CHARGE" 12 "GBDC_ERROR_HANDLING" 11 "GBDC_END_OF_CHARGE" 10 "GBDC_CHARGE_DISABLING" 9 "GBDC_STOP_CHARGE_REQUESTED" 8 "GBDC_CHARGING" 7 "GBDC_READY_TO_CHARGE" 6 "GBDC_VEH_PACK_PRECHARGE" 5 "GBDC_CHARGE_PARAM_CONFIG" 4 "GBDC_RECOGNITION" 3 "GBDC_HANDSHAKING_EXT_ISO" 2 "GBDC_COMMS_RECEIVED" 1 "GBDC_WAIT_FOR_COMMS" 0 "GBDC_INACTIVE" ;
VAL_ 541 CP_gbdcStopChargeReason 8 "GBDC_PARAM_MISMATCH" 7 "GBDC_SUPERCHARGER_COMMS_TIMEOUT" 6 "GBDC_LIVE_DISCONNECT" 5 "GBDC_EVSE_CRITICAL_FAULT" 4 "GBDC_EVSE_FAULT" 3 "GBDC_COMMS_TIMEOUT" 2 "GBDC_EVSE_REQUESTED" 1 "GBDC_VEH_REQUESTED" 0 "GBDC_STOP_REASON_NONE" ;
VAL_ 541 CP_gbdcFailureReason 3 "GBDC_CRITICAL_FAILURE" 2 "GBDC_SHUTDOWN_FAILURE" 1 "GBDC_ATTEMPTS_EXPIRED" 0 "GBDC_FAILURE_NONE" ;
VAL_ 541 CP_acChargeState 6 "AC_CHARGE_FAULT" 5 "AC_CHARGE_VEH_SHUTDOWN" 4 "AC_CHARGE_ONBOARD_CHARGER_SHUTDOWN" 3 "AC_CHARGE_ENABLED" 2 "AC_CHARGE_STANDBY" 1 "AC_CHARGE_CONNECTED_CHARGE_BLOCKED" 0 "AC_CHARGE_INACTIVE" ;
VAL_ 541 CP_teslaDcState 10 "TESLA_DC_FAULT" 9 "TESLA_DC_EMERGENCY_SHUTDOWN" 8 "TESLA_DC_VEH_SHUTDOWN" 7 "TESLA_DC_EVSE_SHUTDOWN" 6 "TESLA_DC_ENABLED" 5 "TESLA_DC_EXT_PRECHARGE_ACTIVE" 4 "TESLA_DC_EXT_TEST_ACTIVE" 3 "TESLA_DC_EXT_TESTS_ENABLED" 2 "TESLA_DC_STANDBY" 1 "TESLA_DC_CONNECTED_CHARGE_BLOCKED" 0 "TESLA_DC_INACTIVE" ;
VAL_ 1885 CP_loggingFastSelect 5 "5" 4 "4" 3 "3" 2 "2" 1 "1" 0 "0" ;
VAL_ 1885 CP_chargeCablePresent 1 "CABLE_PRESENT" 0 "CABLE_NOT_PRESENT" ;
VAL_ 1885 CP_UHF_controlState 10 "CP_UHF_FAULT" 9 "CP_UHF_SLEEP" 8 "CP_UHF_HANDLE_FOUND" 7 "CP_UHF_READ_RXFIFO" 6 "CP_UHF_CHECK_RX" 5 "CP_UHF_RX" 4 "CP_UHF_PREPARE_RX" 3 "CP_UHF_CALIBRATE" 2 "CP_UHF_IDLE" 1 "CP_UHF_CONFIG" 0 "CP_UHF_INIT" ;
VAL_ 1885 CP_doorOpenRequest 8 "CPD_OPEN_REQ_NUM" 7 "CPD_OPEN_REQ_CABLE_RECONNECTED" 6 "CPD_OPEN_REQ_VCFRONT" 5 "CPD_OPEN_REQ_CLOSING_FAILED" 4 "CPD_OPEN_REQ_PUSH_TO_OPEN" 3 "CPD_OPEN_REQ_UHF" 2 "CPD_OPEN_REQ_SEC" 1 "CPD_OPEN_REQ_UI" 0 "CPD_OPEN_REQ_NONE" ;
VAL_ 1885 CP_doorOpenEndOfDriveReason 7 "CP_STOP_DRIVE_REASON_OVERCURRENT" 6 "CP_STOP_DRIVE_REASON_REQ_OVERRIDE" 5 "CP_STOP_DRIVE_REASON_ABSOLUTE_TIMEOUT" 4 "CP_STOP_DRIVE_REASON_MAX_TARGET_V" 3 "CP_STOP_DRIVE_REASON_REACHED_STOP" 2 "CP_STOP_DRIVE_REASON_STOPPED_MOVING_TIMEOUT" 1 "CP_STOP_DRIVE_REASON_STALLED" 0 "CP_STOP_DRIVE_REASON_NONE" ;
VAL_ 1885 CP_doorCloseEndOfDriveReason 7 "CP_STOP_DRIVE_REASON_OVERCURRENT" 6 "CP_STOP_DRIVE_REASON_REQ_OVERRIDE" 5 "CP_STOP_DRIVE_REASON_ABSOLUTE_TIMEOUT" 4 "CP_STOP_DRIVE_REASON_MAX_TARGET_V" 3 "CP_STOP_DRIVE_REASON_REACHED_STOP" 2 "CP_STOP_DRIVE_REASON_STOPPED_MOVING_TIMEOUT" 1 "CP_STOP_DRIVE_REASON_STALLED" 0 "CP_STOP_DRIVE_REASON_NONE" ;
VAL_ 1885 CP_doorCloseRequest 16 "CPD_CLOSE_REQ_NUM" 15 "CPD_CLOSE_REQ_COVER_OPEN" 14 "CPD_CLOSE_REQ_VCFRONT" 13 "CPD_CLOSE_REQ_OPEN_ON_WAKE" 12 "CPD_CLOSE_REQ_SENSOR_COMMS_RECOVERED" 11 "CPD_CLOSE_REQ_SENSOR_MISMATCH" 10 "CPD_CLOSE_REQ_INITIAL_CINCH" 9 "CPD_CLOSE_REQ_OPENED_IN_DRIVE_STATE" 8 "CPD_CLOSE_REQ_ENTER_DRIVE" 7 "CPD_CLOSE_REQ_FAULT_LINE" 6 "CPD_CLOSE_REQ_CAR_WASH" 5 "CPD_CLOSE_REQ_PUSH_TO_CLOSE" 4 "CPD_CLOSE_REQ_SEC" 3 "CPD_CLOSE_REQ_UI" 2 "CPD_CLOSE_REQ_DOOR_OPEN_TIMEOUT" 1 "CPD_CLOSE_REQ_CABLE_UNPLUGGED" 0 "CPD_CLOSE_REQ_NONE" ;
VAL_ 1885 CP_latchDisengagingStopReason 7 "CP_STOP_DRIVE_REASON_OVERCURRENT" 6 "CP_STOP_DRIVE_REASON_REQ_OVERRIDE" 5 "CP_STOP_DRIVE_REASON_ABSOLUTE_TIMEOUT" 4 "CP_STOP_DRIVE_REASON_MAX_TARGET_V" 3 "CP_STOP_DRIVE_REASON_REACHED_STOP" 2 "CP_STOP_DRIVE_REASON_STOPPED_MOVING_TIMEOUT" 1 "CP_STOP_DRIVE_REASON_STALLED" 0 "CP_STOP_DRIVE_REASON_NONE" ;
VAL_ 1885 CP_latchEngagingStopReason 7 "CP_STOP_DRIVE_REASON_OVERCURRENT" 6 "CP_STOP_DRIVE_REASON_REQ_OVERRIDE" 5 "CP_STOP_DRIVE_REASON_ABSOLUTE_TIMEOUT" 4 "CP_STOP_DRIVE_REASON_MAX_TARGET_V" 3 "CP_STOP_DRIVE_REASON_REACHED_STOP" 2 "CP_STOP_DRIVE_REASON_STOPPED_MOVING_TIMEOUT" 1 "CP_STOP_DRIVE_REASON_STALLED" 0 "CP_STOP_DRIVE_REASON_NONE" ;
VAL_ 1885 CP_doorIdDetectionState 2 "DOOR_ID_VALID" 1 "DOOR_ID_INVALID" 0 "DOOR_ID_UNKNOWN_SNA" ;
VAL_ 1885 CP_doorIdDetectedBin 3 "DOOR_ID_BIN_OPAL" 2 "DOOR_ID_BIN_HMC" 1 "DOOR_ID_BIN_NMB" 0 "DOOR_ID_BIN_UNKNOWN" ;
VAL_ 2042 CP_loggingSlowSelect 7 "7" 6 "6" 5 "5" 4 "4" 3 "3" 2 "2" 1 "1" 0 "0" ;
VAL_ 2042 CP_inlet1HarnessIdState 2 "HARNESS_PEDIGREE_VALID" 1 "HARNESS_PEDIGREE_INVALID" 0 "HARNESS_PEDIGREE_UNKNOWN_SNA" ;
VAL_ 2042 CP_inlet2HarnessIdState 2 "HARNESS_PEDIGREE_VALID" 1 "HARNESS_PEDIGREE_INVALID" 0 "HARNESS_PEDIGREE_UNKNOWN_SNA" ;
VAL_ 2042 CP_inletHeaterState 3 "INLET_HEATER_FAULTED" 2 "INLET_HEATER_ENABLED_LOWTEMP" 1 "INLET_HEATER_ENABLED_HIGHTEMP" 0 "INLET_HEATER_DISABLED" ;
VAL_ 2042 CP_doorOpenLimiterMaxRequestType 8 "CPD_OPEN_REQ_NUM" 7 "CPD_OPEN_REQ_CABLE_RECONNECTED" 6 "CPD_OPEN_REQ_VCFRONT" 5 "CPD_OPEN_REQ_CLOSING_FAILED" 4 "CPD_OPEN_REQ_PUSH_TO_OPEN" 3 "CPD_OPEN_REQ_UHF" 2 "CPD_OPEN_REQ_SEC" 1 "CPD_OPEN_REQ_UI" 0 "CPD_OPEN_REQ_NONE" ;
VAL_ 2042 CP_doorCloseLimiterMaxRequestTyp 16 "CPD_CLOSE_REQ_NUM" 15 "CPD_CLOSE_REQ_COVER_OPEN" 14 "CPD_CLOSE_REQ_VCFRONT" 13 "CPD_CLOSE_REQ_OPEN_ON_WAKE" 12 "CPD_CLOSE_REQ_SENSOR_COMMS_RECOVERED" 11 "CPD_CLOSE_REQ_SENSOR_MISMATCH" 10 "CPD_CLOSE_REQ_INITIAL_CINCH" 9 "CPD_CLOSE_REQ_OPENED_IN_DRIVE_STATE" 8 "CPD_CLOSE_REQ_ENTER_DRIVE" 7 "CPD_CLOSE_REQ_FAULT_LINE" 6 "CPD_CLOSE_REQ_CAR_WASH" 5 "CPD_CLOSE_REQ_PUSH_TO_CLOSE" 4 "CPD_CLOSE_REQ_SEC" 3 "CPD_CLOSE_REQ_UI" 2 "CPD_CLOSE_REQ_DOOR_OPEN_TIMEOUT" 1 "CPD_CLOSE_REQ_CABLE_UNPLUGGED" 0 "CPD_CLOSE_REQ_NONE" ;
VAL_ 528 CP_type 3 "CP_TYPE_IEC_CCS" 2 "CP_TYPE_GB" 1 "CP_TYPE_EURO_IEC" 0 "CP_TYPE_US_TESLA" ;
VAL_ 528 CP_latchState 3 "CP_LATCH_BLOCKING" 2 "CP_LATCH_ENGAGED" 1 "CP_LATCH_DISENGAGED" 0 "CP_LATCH_SNA" ;
VAL_ 528 CP_doorControlState 6 "CP_doorSenseClosed" 5 "CP_doorClosing" 4 "CP_doorSenseOpen" 3 "CP_doorOpening" 2 "CP_doorOpenRequested" 1 "CP_doorIdle" 0 "CP_doorInit" ;
VAL_ 528 CP_chargeCableState 2 "CHARGE_CABLE_CONNECTED" 1 "CHARGE_CABLE_NOT_CONNECTED" 0 "CHARGE_CABLE_UNKNOWN_SNA" ;
VAL_ 528 CP_latchControlState 5 "CP_latchEngaging" 4 "CP_latchDisengaged" 3 "CP_latchDisengaging" 2 "CP_latchDisengageRequested" 1 "CP_latchIdle" 0 "CP_latchInit" ;
VAL_ 528 CP_ledColor 13 "CP_LEDS_FLASHING_WHITE" 12 "CP_LEDS_FADING_OUT" 11 "CP_LEDS_FLASHING_PURPLE" 10 "CP_LEDS_FLASHING_BLUE" 9 "CP_LEDS_DEBUG" 8 "CP_LEDS_RAVE" 7 "CP_LEDS_AMBER" 6 "CP_LEDS_FLASHING_AMBER" 5 "CP_LEDS_FLASHING_GREEN" 4 "CP_LEDS_WHITE" 3 "CP_LEDS_BLUE" 2 "CP_LEDS_GREEN" 1 "CP_LEDS_RED" 0 "CP_LEDS_OFF" ;
VAL_ 528 CP_faultLineSensed 1 "FAULT_LINE_SET" 0 "FAULT_LINE_CLEARED" ;
VAL_ 528 CP_doorPresenceState 7 "CP_DOOR_PRESENCE_STATE_FAULT" 6 "CP_DOOR_PRESENCE_STATE_OFF_CHARGE" 5 "CP_DOOR_PRESENCE_STATE_OFF_DRIVE" 4 "CP_DOOR_PRESENCE_STATE_NOT_PRESENT" 3 "CP_DOOR_PRESENCE_STATE_PRESENT" 2 "CP_DOOR_PRESENCE_STATE_INIT_FROM_DRIVE" 1 "CP_DOOR_PRESENCE_STATE_INIT_FROM_CHARGE" 0 "CP_DOOR_PRESENCE_STATE_INIT" ;
VAL_ 528 CP_inductiveSensorState 7 "CP_INDUCTIVE_SENSOR_CONFIG" 6 "CP_INDUCTIVE_SENSOR_RESET" 5 "CP_INDUCTIVE_SENSOR_FAULT" 4 "CP_INDUCTIVE_SENSOR_WAIT_FOR_INIT" 3 "CP_INDUCTIVE_SENSOR_PAUSE" 2 "CP_INDUCTIVE_SENSOR_SHUTDOWN" 1 "CP_INDUCTIVE_SENSOR_POLL" 0 "CP_INDUCTIVE_SENSOR_INIT" ;
VAL_ 528 CP_coldWeatherMode 1 "CP_COLD_WEATHER_LATCH_MITIGATION" 0 "CP_COLD_WEATHER_NONE" ;
VAL_ 528 CP_inletHeaterUiState 4 "CP_HEATER_FAULTED" 3 "CP_HEATER_ENABLED" 2 "CP_HEATER_AVAILABLE" 1 "CP_HEATER_NOT_AVAILABLE" 0 "CP_HEATER_NOT_SUPPORTED" ;
VAL_ 893 CP_thermalStatusSelect 1 "1" 0 "0" ;
VAL_ 583 DAS_roadEstimator 3 "ROAD_ESTIMATOR_CRITICAL" 2 "ROAD_ESTIMATOR_DEGRADED" 1 "ROAD_ESTIMATOR_UNSTABLE_MEASUREMENTS" 0 "ROAD_ESTIMATOR_HEALTHY" ;
VAL_ 583 DAS_arbiterBehavior 4 "ARBITER_CITY_STREETS" 3 "ARBITER_LANE_CHANGE_RIGHT" 2 "ARBITER_LANE_CHANGE_LEFT" 1 "ARBITER_IN_LANE" 0 "ARBITER_INVALID" ;
VAL_ 583 DAS_mapAvailability 1 "APM_MAP_AVAILABLE" 0 "APM_MAP_NOT_AVAILABLE" ;
VAL_ 583 DAS_controllerRef 6 "CONTROLLER_REFERENCE_INDETERMINATE" 5 "CONTROLLER_REFERENCE_REF_TOO_SHORT" 4 "CONTROLLER_REFERENCE_BAD_REF_UPDATE" 3 "CONTROLLER_REFERENCE_STALE_LOCALIZATION" 2 "CONTROLLER_REFERENCE_STALE_REFERENCE" 1 "CONTROLLER_REFERENCE_UNHEALTHY" 0 "CONTROLLER_REFERENCE_HEALTHY" ;
VAL_ 583 DAS_alcInternalState 12 "ALC_RETRY" 11 "ALC_SOFT_ABORTING_RIGHT" 10 "ALC_SOFT_ABORTING_LEFT" 9 "ALC_ACTIVE_ACC_RIGHT" 8 "ALC_ACTIVE_ACC_LEFT" 7 "ALC_ACTIVE_RIGHT" 6 "ALC_ACTIVE_LEFT" 5 "ALC_PRE_ACTIVE_RIGHT" 4 "ALC_PRE_ACTIVE_LEFT" 3 "ALC_BEHAVIOR_CHECK" 2 "ALC_ABORTING" 1 "ALC_IDLE" 0 "ALC_DISABLED" ;
VAL_ 583 DAS_behaviorReport 71 "BEHAVIOR_MAX_SPEED_IN_REVERSE" 70 "BEHAVIOR_STOPPING_FOR_GEAR_CHANGE" 69 "BEHAVIOR_ROAD_SPEED" 68 "BEHAVIOR_CAMERA_FAILSAFES" 67 "BEHAVIOR_CAUTION_LIGHTS" 66 "BEHAVIOR_DRY_STEERING" 65 "BEHAVIOR_CREEP_FOR_SHORT_REF" 64 "BEHAVIOR_FAILED_LANE_CHANGE" 63 "BEHAVIOR_AHB_MANUAL_OVERRIDE" 62 "BEHAVIOR_FORWARD_LATERAL_OBJECT" 61 "BEHAVIOR_POOR_VISIBILITY" 60 "BEHAVIOR_MAIN_CAMERA_SUN_GLARE" 59 "BEHAVIOR_CITY_MERGE_OBJECT" 58 "BEHAVIOR_TRAJECTORY_OUTLIER_PRESSURE" 57 "BEHAVIOR_REFERENCE_LENGTH" 56 "BEHAVIOR_PATH_BLOCKED_BEYOND_TRAJ" 55 "BEHAVIOR_PATH_BLOCKED" 54 "BEHAVIOR_UNSUPPORTED_MANEUVER" 53 "BEHAVIOR_CROSSING_OBJECT" 52 "BEHAVIOR_CLEAR_TO_GO" 51 "BEHAVIOR_APPROACHING_TURN" 50 "BEHAVIOR_DYNAMIC_PINCH_POINT" 49 "BEHAVIOR_VANISHING_CIPV_KEEP_CALM" 48 "BEHAVIOR_ONRAMP_BOOST" 47 "BEHAVIOR_TRAFFIC_CONTROL_LAUNCH" 46 "BEHAVIOR_NARROW_CORRIDOR" 45 "BEHAVIOR_SPEED_BUMP" 44 "BEHAVIOR_SUGGESTED_VISION_SPEED" 43 "BEHAVIOR_ROUNDABOUT" 42 "BEHAVIOR_TOLLBOOTH" 41 "BEHAVIOR_CROSS_TRAFFIC_AVOIDANCE" 40 "BEHAVIOR_CROSSWALK" 39 "BEHAVIOR_RELEVANT_VRU" 38 "BEHAVIOR_RISK_MANAGER" 37 "BEHAVIOR_STATIC_OBJECT_MERGE_RIGHT" 36 "BEHAVIOR_STATIC_OBJECT_MERGE_LEFT" 35 "BEHAVIOR_CUTIN_VEHICLE" 34 "BEHAVIOR_STATIC_OBJECT" 33 "BEHAVIOR_LANE_SPEED_DIFF" 32 "BEHAVIOR_END_OF_NAV_ROUTE" 31 "BEHAVIOR_STEERING_SATURATED" 30 "BEHAVIOR_ACTIVE_SAFETY_SLOWDOWN" 29 "BEHAVIOR_MP_AP_INACTIVE" 28 "BEHAVIOR_MP_ULC" 27 "BEHAVIOR_MP_DI_CRUISE" 26 "BEHAVIOR_MP_AP_STATE_MACHINE" 25 "BEHAVIOR_MP_DRIVER_MONITOR" 24 "BEHAVIOR_MP_NOT_BUCKLED" 23 "BEHAVIOR_MP_AP_RESTRICTION" 22 "BEHAVIOR_CUTIN_VEHICLE_RIGHT" 21 "BEHAVIOR_CUTIN_VEHICLE_LEFT" 20 "BEHAVIOR_MERGE_VEHICLE_RIGHT" 19 "BEHAVIOR_MERGE_VEHICLE_LEFT" 18 "BEHAVIOR_NAV_PATH_CSA" 17 "BEHAVIOR_NAV_FLEET_SPEEDS" 16 "BEHAVIOR_VISION_SPEEDS" 15 "BEHAVIOR_SLOWING_FOR_TARGET_LANE" 14 "BEHAVIOR_DRIVABLE_SPACE_VIOLATION" 13 "BEHAVIOR_MAP_LANE_GEOMETRY" 12 "BEHAVIOR_VISION_LANE_GEOMETRY" 11 "BEHAVIOR_TRAFFIC_CONTROL" 10 "BEHAVIOR_UNDERTAKE_VEHICLE" 9 "BEHAVIOR_TARGET_LANE_VEHICLE" 8 "BEHAVIOR_IN_LANE_VEHICLE" 7 "BEHAVIOR_UNDERTAKE_ASSIST_KEEP_CALM" 6 "BEHAVIOR_TRAFFIC_CONTROL_STOPPED_STATE" 5 "BEHAVIOR_FLEET_SPEEDS" 4 "BEHAVIOR_KEEP_CALM" 3 "BEHAVIOR_RADAR_ONLY_BRAKING" 2 "BEHAVIOR_CURVE_SPEED_ADAPTATION" 1 "BEHAVIOR_VIEW_RANGE" ;
VAL_ 583 DAS_controllerHealth 3 "CONTROLLER_SOLVER_FAILURE" 2 "CONTROLLER_CRITICAL" 1 "CONTROLLER_DEGRADED" 0 "CONTROLLER_HEALTHY" ;
VAL_ 583 DAS_autopilotAbortReason 255 "ABORT_REASON_MAX" 80 "ABORT_DRIVER_SEAT_TRAVEL" 79 "ABORT_DRIVER_OCCLUDED_DISTRACTED" 78 "ABORT_DRIVER_REACHING_DISTRACTED" 77 "ABORT_LOW_CABIN_ILLUMINANCE" 76 "ABORT_CABIN_CAM_OCCLUSION_DNP" 75 "ABORT_DRIVER_OCCLUDED" 74 "ABORT_DRIVER_NOT_DETECTED_SELFIE" 73 "ABORT_DRIVER_E2E_UNKNOWN" 72 "ABORT_DRIVER_EMPTY_SEAT" 71 "ABORT_DRIVER_SEAT_RECLINED" 70 "ABORT_FSD_REGION_NOT_ALLOWED" 69 "ABORT_FERRY_CROSSING" 68 "ABORT_DOOR_OPEN" 67 "ABORT_FRUNK_OPEN" 66 "ABORT_TRUNK_OPEN" 65 "ABORT_CABIN_CAM_ISSUE" 64 "ABORT_TASK_FLOW_TRACE_TIMEOUT" 63 "ABORT_SEALED_MERGE_CROSSING" 62 "ABORT_FSD_GEOFENCE_DISABLED" 61 "ABORT_EXTENDED_COMPUTE_INACTIVE_PCIE_LINK_HEALTH" 60 "ABORT_EXTENDED_COMPUTE_INACTIVE_ETHERNET_LINK_HEALTH" 59 "ABORT_EXTENDED_COMPUTE_INACTIVE_OTHER_SOC_HEALTH_CRITICAL" 58 "ABORT_EXTENDED_COMPUTE_INACTIVE_OTHER_SOC_HEALTH_UNKNOWN" 57 "ABORT_CABIN_CAM_BLIND" 56 "ABORT_AHB_MANUAL_OVERRIDE" 55 "ABORT_DRIVER_NOT_PRESENT" 54 "ABORT_PERCEPTION_HEALTH_STALE" 53 "ABORT_PERCEPTION_HEALTH_POST_PROCESSING" 52 "ABORT_EXTENDED_COMPUTE_INACTIVE" 51 "ABORT_CITY_STREETS_REF_TOO_SHORT" 50 "ABORT_INVALID_BEHAVIOR" 49 "ABORT_ONCOMING_LANE" 48 "ABORT_HEADLIGHT_OFF_AT_NIGHT" 47 "ABORT_IBOOSTER_MIA" 46 "ABORT_INTEGRATOR_HEALTH_CRITICAL" 45 "ABORT_USER_OVERRIDE_STRIKEOUT" 44 "ABORT_SEATBELT_UNBUCKLED" 43 "ABORT_PERCEPTION_HEALTH_VISION" 42 "ABORT_INVALID_VEHICLE_SPEED" 41 "ABORT_INVALID_DI_PEDAL_POS" 40 "ABORT_W048_FEATURES_DISABLED" 39 "ABORT_EPAS_STEERING_ANGLE_INVALID" 38 "ABORT_STEERING_SATURATED_LANE_DEPARTURE" 37 "ABORT_REACHED_END_OF_NAV_STOP" 36 "ABORT_GORE_INCURSION" 35 "ABORT_MISSION_PLANNER_NO_VISION_LANES_FOUND" 34 "ABORT_CONTROLLER_REF_TOO_SHORT" 33 "ABORT_AEB" 32 "ABORT_CONTROLLER_BAD_REF_UPDATE" 31 "ABORT_CONTROLLER_STALE_LOCALIZATION" 30 "ABORT_CONTROLLER_STALE_REFERENCE" 29 "ABORT_MAP_HEALTH" 28 "ABORT_THERMAL_ISSUE" 27 "ABORT_CONTROLLER_NOT_ALLOWED" 26 "ABORT_CONTROLLER_SOLVER" 25 "ABORT_CONTROLLER_REFERENCE" 24 "ABORT_ROAD_ESTIMATOR_HEALTH" 23 "ABORT_ACC_FAULT" 22 "ABORT_ACC_CANCEL_SILENT" 21 "ABORT_ACC_CANCEL_GENERIC" 20 "ABORT_RADAR_FAULT" 19 "ABORT_RADAR_BLIND" 18 "ABORT_CAMERA_CALIBRATION" 17 "ABORT_CAMERA_FAILSAFES" 16 "ABORT_EPAS_EAC_ERROR" 15 "ABORT_EPAS_EAC_NOT_ACTIVE" 14 "ABORT_VEHICLE_SPEED_ABOVE_MAX" 13 "ABORT_TRAILER_MODE_ACTIVE" 12 "ABORT_USER_DISABLED" 11 "ABORT_CRUISE_NOT_ACTIVE" 10 "ABORT_CRUISE_FAULT" 9 "ABORT_VCRIGHT_MIA" 8 "ABORT_VCFRONT_MIA" 7 "ABORT_RADAR_MIA" 6 "ABORT_SCCM_MIA" 5 "ABORT_GTW_MIA" 4 "ABORT_EPAS_MIA" 3 "ABORT_ESP_MIA" 2 "ABORT_DI_MIA" 1 "ABORT_WATCHDOG_HEALTH" 0 "ABORT_NONE" ;
VAL_ 583 DAS_rqstedBehaviorStatus 22 "RQST_BEHAVIOR_INVALID_PLAN" 21 "RQST_BEHAVIOR_BLOCKED_BY_SLOW_TARGET_R" 20 "RQST_BEHAVIOR_BLOCKED_BY_SLOW_TARGET_L" 19 "RQST_BEHAVIOR_BAD_ORIGIN_UPDATE" 18 "RQST_BEHAVIOR_OUT_OF_DATE" 17 "RQST_BEHAVIOR_ROAD_NOT_APPROPRIATE" 16 "RQST_BEHAVIOR_BLOCKED_BY_LANE_TYPE_R" 15 "RQST_BEHAVIOR_BLOCKED_BY_ULTRASOUND_AND_CAMERA_R" 14 "RQST_BEHAVIOR_BLOCKED_BY_BLINDSPOT_CAMERA_INVALID_R" 13 "RQST_BEHAVIOR_BLOCKED_BY_BLINDSPOT_CAMERA_R" 12 "RQST_BEHAVIOR_BLOCKED_BY_ULTRASOUND_R" 11 "RQST_BEHAVIOR_BLOCKED_BY_LANE_TYPE_L" 10 "RQST_BEHAVIOR_BLOCKED_BY_ULTRASOUND_AND_CAMERA_L" 9 "RQST_BEHAVIOR_BLOCKED_BY_BLINDSPOT_CAMERA_INVALID_L" 8 "RQST_BEHAVIOR_BLOCKED_BY_BLINDSPOT_CAMERA_L" 7 "RQST_BEHAVIOR_BLOCKED_BY_ULTRASOUND_L" 6 "RQST_BEHAVIOR_BUILD_ARGUMENT_FAIL" 5 "RQST_BEHAVIOR_NO_TARGET_LANE_ON_MAP" 4 "RQST_BEHAVIOR_NO_SOURCE_LANE_ON_MAP" 3 "RQST_BEHAVIOR_MAP_NOT_INITIALIZED" 2 "RQST_BEHAVIOR_NO_DEST_POLYLANE" 1 "RQST_BEHAVIOR_NO_SRC_POLYLANE" 0 "RQST_BEHAVIOR_VALID" ;
VAL_ 583 DAS_forkState 29 "FORK_AWAITING_CONFIRMATION_RIGHT" 28 "FORK_AWAITING_CONFIRMATION_LEFT" 27 "FORK_UNAVAILABLE_INTERSECTION_ACTIVE" 26 "FORK_PRE_ACTIVE_RIGHT_NAV" 25 "FORK_PRE_ACTIVE_LEFT_NAV" 24 "FORK_UNAVAILABLE_WEATHER" 23 "FORK_UNAVAILABLE_TIGHT_TURN_RADIUS" 22 "FORK_ABORT_OTHER" 21 "FORK_ABORT_DISALLOW" 20 "FORK_ABORT_NOT_RIGHT_LANE" 19 "FORK_ABORT_NOT_LEFT_LANE" 18 "FORK_ABORT_BLINKER_CHANGE" 17 "FORK_ABORT_CONTROL_INACTIVE" 16 "FORK_FORK_COMPLETE" 15 "FORK_ACTIVE_RIGHT_USER" 14 "FORK_ACTIVE_RIGHT_NAV" 13 "FORK_ACTIVE_LEFT_USER" 12 "FORK_ACTIVE_LEFT_NAV" 11 "FORK_IDLE_NO_FORKS_AVAILABLE" 10 "FORK_IDLE_RIGHT_FORK_AVAILABLE" 9 "FORK_IDLE_LEFT_FORK_AVAILABLE" 8 "FORK_IDLE_BOTH_FORKS_AVAILABLE" 7 "FORK_UNAVAILABLE_OTHER" 6 "FORK_UNAVAILABLE_TOLL_BOOTH" 5 "FORK_UNAVAILABLE_DON_INACTIVE" 4 "FORK_UNAVAILABLE_CONTROLLED_ACCESS_TOO_FAR" 3 "FORK_UNAVAILABLE_CONSTRUCTION" 2 "FORK_UNAVAILABLE_AP_INACTIVE" 1 "FORK_UNAVAILABLE_DISABLED" 0 "FORK_INVALID" ;
VAL_ 583 DAS_laneChangeState 63 "LANE_CHANGE_UNKNOWN" 43 "LANE_CHANGE_ABORTING_DESTINATION_LANE_UNSTABLE" 42 "LANE_CHANGE_UNAVAILABLE_AUTOPILOT_ABORTING" 41 "LANE_CHANGE_UNAVAILABLE_BLINKER_LATCHED" 40 "LANE_CHANGE_ABORTING_SNOOZED" 39 "LANE_CHANGE_ABORTING_SOURCE_AND_TARGET_LANES_MERGED" 38 "LANE_CHANGE_UNAVAILABLE_NO_REAR_OBJECT" 37 "LANE_CHANGE_ABORTING_NO_HANDS_ON" 36 "LANE_CHANGE_UNAVAILABLE_BLINDSPOT_RESTRICTED" 35 "LANE_CHANGE_ABORTING_WEATHER" 34 "LANE_CHANGE_ABORTING_TIGHT_TURN_RADIUS" 33 "LANE_CHANGE_ABORTING_TOLL_BOOTH_DETECTED" 32 "LANE_CHANGE_ABORTING_CONSTRUCTION_DETECTED" 31 "LANE_CHANGE_ABORTING_GORE_POINT" 30 "LANE_CHANGE_BLOCKED_RIGHT" 29 "LANE_CHANGE_BLOCKED_LEFT" 28 "LANE_CHANGE_IN_PROGRESS_RIGHT" 27 "LANE_CHANGE_IN_PROGRESS_LEFT" 26 "LANE_CHANGE_ABORTING_ALC_REQUEST_BEFORE_ULC_CONFIRM" 25 "LANE_CHANGE_ABORTING_ULC_CONFIRMATION_TIMEOUT" 24 "LANE_CHANGE_ABORTING_HIGH_ALC_PROGRESS_ERROR" 23 "LANE_CHANGE_ABORTING_BEHAVIOR_CHANGED" 22 "LANE_CHANGE_ABORTING_BELOW_MIN_SPEED" 21 "LANE_CHANGE_ABORTING_INVALID_BEHAVIOR" 20 "LANE_CHANGE_ABORTING_ULC_BLINKER_TIMEOUT" 19 "LANE_CHANGE_ABORTING_ACC_AUTOSTEER_ACTIVATED" 18 "LANE_CHANGE_ABORTING_LOST_VISION_POSE" 17 "LANE_CHANGE_ABORTING_FORK_AVAILABLE" 16 "LANE_CHANGE_ABORTING_LINE_TYPE" 15 "LANE_CHANGE_ABORTING_INVALID_MODE" 14 "LANE_CHANGE_ABORTING_BLIND_SPOT_OCCUPIED" 13 "LANE_CHANGE_ABORTING_TIMEOUT" 12 "LANE_CHANGE_ABORTING_BLINKER" 11 "LANE_CHANGE_ABORTING_INACTIVE" 10 "LANE_CHANGE_AVAILABLE_BOTH" 9 "LANE_CHANGE_AVAILABLE_RIGHT_ONLY" 8 "LANE_CHANGE_AVAILABLE_LEFT_ONLY" 7 "LANE_CHANGE_UNAVAILABLE_INVALID_MODE" 6 "LANE_CHANGE_UNAVAILABLE_ULTRASONICS_NOT_READY" 5 "LANE_CHANGE_UNAVAILABLE_FORK_MODE" 4 "LANE_CHANGE_UNAVAILABLE_INACTIVE" 3 "LANE_CHANGE_UNAVAILABLE_NO_LANES" 2 "LANE_CHANGE_UNAVAILABLE_SPEED" 1 "LANE_CHANGE_UNAVAILABLE_ROAD_NOT_APPROPRIATE" 0 "LANE_CHANGE_UNAVAILABLE_DISABLED" ;
VAL_ 583 DAS_lastWatchdogCode 127 "TRIP_HISTORY_FAILED" 126 "TEXT_LOG_FAILED" 125 "AUTOPILOT_OBJECT_POSE_FAILED" 124 "RELOCALIZATION_FAILED" 123 "SLAM_MAPPING_FAILED" 122 "SLAM_BATCH_CALIB_FAILED" 121 "SLAM_BA_FAILED" 120 "SLAM_FAILED" 119 "RTDV_STREAMER_FAILED" 118 "RTDV_COMPRESSOR_FAILED" 117 "REPLAY_FAILED" 116 "REMOTE_ACCESS_FAILED" 115 "PT_TRACKER_FAILED" 114 "PERFORMANCE_COUNTER_MONITOR_FAILED" 113 "METRICS_DEV_FAILED" 112 "METRICS_API_FAILED" 111 "METRICS_FAILED" 110 "LOGGING_LOAD_GENERATOR_FAILED" 109 "LIDAR_FAILED" 108 "HTTP_SERVER_FAILED" 107 "FRAME_DECODER_FAILED" 106 "INFERENCE_ENGINE_FAILED" 105 "FACTORY_CAMERA_CALIBRATION_FAILED" 104 "DV_INSPECTOR_FAILED" 103 "DETERMINATOR_FAILED" 102 "DASH_CAM_FAILED" 101 "CLIP_REMOTE_WRITER_FAILED" 100 "COMPRESSOR_FAILED" 99 "FTRACE_SNAPSHOT_FAILED" 98 "SWITCH_MONITOR_FAILED" 97 "BLUEFIN_FAILED" 96 "BACKUP_CAMERA_FAILED" 95 "AUTONOMOUS_BEHAVIORS_FAILED" 94 "AUDIO_PROCESSOR_FAILED" 93 "CAMERA_HEALTH_FAILED" 92 "POSITIONING_ENGINE_FAILED" 91 "AUDIO_FAILED" 90 "IMU_CALIBRATION_FAILED" 89 "RADAR_EXTENDED_FAILED" 88 "TILE_PROVIDER_FAILED" 87 "RADAR_RECEIVER_FAILED" 86 "TELEMETRY_COMPLIANCE_FAILED" 85 "GEO_REGION_FAILED" 84 "FLEET_CONFIG_FAILED" 83 "X1_CLIENT_FAILED" 82 "SYNC_PIPELINE_FAILED" 81 "RADAR_FAILED" 80 "ULTRASONICS_FAILED" 79 "BEV_GRAPH_FAILED" 78 "CITY_STREETS_BEHAVIOR_FAILED" 77 "BRIDGE_FAILED" 76 "SCHEDULER_FAILED" 75 "DRIVABLE_SPACE_TRACKER_FAILED" 74 "CLIP_LOGGER_FAILED" 73 "HW_MONITOR_FAILED" 72 "PARKING_BEHAVIOR_FAILED" 71 "FIELD_CALIBRATION_FAILED" 70 "DYNAMICS_FAILED" 69 "UI_SERVER_FAILED" 68 "ACTIVE_SAFETY_FAILED" 67 "CAMERA_FAILED" 66 "MAP_MANAGER_FAILED" 65 "DRIVER_MONITOR_FAILED" 64 "MODEL_TOOLS_FAILED" 63 "LANE_CHANGE_BEHAVIOR_FAILED" 62 "UBX_LOG_FAILED" 61 "IMU_FAILED" 60 "RAIN_LIGHT_SENSING_FAILED" 59 "SNAPSHOT_TRIGGER_CLIENT_FAILED" 58 "STAY_IN_LANE_BEHAVIOR_FAILED" 57 "ATLAS_FAILED" 56 "ROAD_ESTIMATOR_FAILED" 55 "PERCEPTION_FAILED" 54 "MISSION_PLANNER_FAILED" 53 "LOCALIZER_FAILED" 52 "CONTROLLER_FAILED" 51 "AP_STATE_MACHINE_FAILED" 50 "ARBITER_FAILED" 49 "GPS_FAILED" 48 "INERTIATOR_FAILED" 47 "TEMPERATURE_MONITOR_FAILED" 46 "CAN_TX_FAILED" 45 "CAN_RX_FAILED" 44 "WATCHDOG_FAILED" 43 "LEGACY_FAILED" 42 "VISION_FAILED" 41 "SNAPSHOT_FAILED" 40 "TELEMETRY_FAILED" 39 "TELEMETRY_PACKAGER_FAILED" 30 "UNKNOWN_TASK_FAILED" 0 "NO_TASK_FAILED" ;
VAL_ 2041 DAS_gpsStatusMultiplexer 3 "Mux3" 2 "Mux2" 1 "Mux1" 0 "Mux0" ;
VAL_ 2041 DAS_gpsTransportModeState 1 "DAS_GPS_TRANSPORT_MODE_ON" 0 "DAS_GPS_TRANSPORT_MODE_OFF" ;
VAL_ 2041 DAS_gpsWheelsOffMotionDetected 1 "DAS_GPS_MOTION_DETECTED_ON" 0 "DAS_GPS_MOTION_DETECTED_OFF" ;
VAL_ 2041 DAS_gpsFixTypeHardware 6 "DEAD_RECOCKONING_FIX" 5 "FLOAT_RTK_FIX" 4 "REAL_TIME_KINEMATICS_FIX" 3 "PPS_FIX" 2 "DGPS_FIX" 1 "GPS_FIX" 0 "INVALID_FIX" ;
VAL_ 2041 DAS_gpsFixTypeSoftware 6 "DEAD_RECOCKONING_FIX" 5 "FLOAT_RTK_FIX" 4 "REAL_TIME_KINEMATICS_FIX" 3 "PPS_FIX" 2 "DGPS_FIX" 1 "GPS_FIX" 0 "INVALID_FIX" ;
VAL_ 2041 DAS_gpsJammingState 3 "GPS_JAMMING_STATE_CRITICAL" 2 "GPS_JAMMING_STATE_WARNING" 1 "GPS_JAMMING_STATE_NOMINAL" 0 "GPS_JAMMING_STATE_UNKNOWN" ;
VAL_ 2041 DAS_gpsSpoofDetectorState 3 "GPS_SPOOFING_MULTIPLE_INDICATIONS" 2 "GPS_SPOOFING_INDICATION_PRESENT" 1 "GPS_SPOOFING_NO_ACTIVE_INDICATION" 0 "GPS_SPOOFING_UNKNOWN" ;
VAL_ 2041 DAS_gnssConstellationsState 2 "CONSTELLATIONS_STATE_VALID" 1 "CONSTELLATIONS_STATE_INVALID" 0 "CONSTELLATIONS_STATE_UNKNOWN" ;
VAL_ 2041 DAS_gpsResetReason 13 "GPS_RESET_PPS_MISSING" 12 "GPS_RESET_SOLUTION_INCONSISTENCY" 11 "GPS_RESET_MANUAL_COLD_RESET" 10 "GPS_RESET_GNSS_CFG_CHANGE" 9 "GPS_RESET_RESUME_CONFIGURATION_FAULT" 8 "GPS_RESET_SUSPEND_CONFIGURATION_FAULT" 7 "GPS_RESET_SATELLITE_REJECTION_TIMEOUT" 6 "GPS_RESET_ENTER_TRANSPORT_MODE" 5 "GPS_RESET_EXIT_TRANSPORT_MODE" 4 "GPS_RESET_GNSS_DATA_MISSING" 3 "GPS_RESET_UBX_MISSING" 2 "GPS_RESET_DATA_CORRUPTED" 1 "GPS_RESET_DATA_MISSING" 0 "GPS_RESET_NONE" ;
VAL_ 2041 DAS_gpsToMcuSource 4 "GPS_TO_MCU_SOURCE_BLUEFIN_SOLUTION" 3 "GPS_TO_MCU_SOURCE_TESLA_VIO_SOLUTION" 2 "GPS_TO_MCU_SOURCE_SOFTWARE_SOLUTION" 1 "GPS_TO_MCU_SOURCE_HARDWARE_SOLUTION" 0 "GPS_TO_MCU_SOURCE_UNKNOWN" ;
VAL_ 2041 DAS_gpsSolutionSoc 2 "GPS_SOLUTION_SOC_B" 1 "GPS_SOLUTION_SOC_A" 0 "GPS_SOLUTION_SOC_UNKNOWN" ;
VAL_ 2041 DAS_gpsFixTypeSoftwareSocB 6 "DEAD_RECOCKONING_FIX" 5 "FLOAT_RTK_FIX" 4 "REAL_TIME_KINEMATICS_FIX" 3 "PPS_FIX" 2 "DGPS_FIX" 1 "GPS_FIX" 0 "INVALID_FIX" ;
VAL_ 2041 DAS_gnssNumSatsGps 15 "FIFTEEN_OR_MORE_SATELLITES" ;
VAL_ 2041 DAS_gnssNumSatsGal 15 "FIFTEEN_OR_MORE_SATELLITES" ;
VAL_ 2041 DAS_gnssNumSatsBds 15 "FIFTEEN_OR_MORE_SATELLITES" ;
